VERSION ""

NS_ :

BS_:

BU_: VMCU VGGSECUSystem TECU OBDScanT2 HMIIOM EMS ECUspare2 ECUspare1 DACU CIOM BBM

BO_ 2483002322 HMIIOM_BB2_07P: 8 HMIIOM
 SG_ AudioSourceBtStreamAvailable_ISi : 40|2@1+ (1,0) [0|0] ""  CIOM
 SG_ MainBeam_StalkStatus_4 : 56|3@1+ (1,0) [0|0] ""  VMCU
 SG_ AudioSourceCdAvailable_ISig_4 : 26|2@1+ (1,0) [0|0] ""  CIOM
 SG_ LightMode_SwitchStatus : 48|3@1+ (1,0) [0|0] ""  VMCU
 SG_ PhoneButtonIndication_cmd : 6|2@1+ (1,0) [0|0] ""  CIOM
 SG_ AudioVolumeIndicationCmd_ISig_4 : 8|6@1+ (1,0) [0|63] "Step"  CIOM
 SG_ AudioSourceIpodAvailable_ISig_4 : 36|2@1+ (1,0) [0|0] ""  CIOM
 SG_ AudioSystemStatus_ISig_4 : 4|2@1+ (1,0) [0|0] ""  CIOM
 SG_ WiperAdjustStatus_4 : 59|3@1+ (1,0) [0|0] ""  VMCU
 SG_ AudioSourceUsbAvailable_ISig_4 : 38|2@1+ (1,0) [0|0] ""  CIOM
 SG_ BTStatus : 24|2@1+ (1,0) [0|0] ""  CIOM
 SG_ AudioSourceStatus_ISig_4 : 21|3@1+ (1,0) [0|0] ""  CIOM
 SG_ Washing_Status_4 : 46|2@1+ (1,0) [0|0] ""  VMCU
 SG_ WiperStalkStat_4 : 51|3@1+ (1,0) [0|0] ""  VMCU
 SG_ AudioSourceStatus2_ISig_4 : 42|4@1+ (1,0) [0|0] ""  CIOM
 SG_ BrakeBlending_DeviceIndication : 14|2@1+ (1,0) [0|0] ""  CIOM
 SG_ PresetIndicationCmd_ISig_4 : 28|6@1+ (1,0) [0|63] "Enumeration"  CIOM
 SG_ BunkBacklightCmd_ISig_4 : 16|5@1+ (1,0) [0|0] ""  CIOM
 SG_ ABSInhibit_DeviceIndication : 34|2@1+ (1,0) [0|0] ""  CIOM
 SG_ DayOfWeek_stat_ISig_4 : 0|4@1+ (1,0) [0|0] ""  CIOM

BO_ 2499765033 HMIIOM_BB2_06S_FCM: 8 CIOM
 SG_ HMIIOM_BB2_06S_FCS : 0|64@1+ (1,0) [0|1] ""  HMIIOM

BO_ 2499765032 HMIIOM_BB2_06S: 13 HMIIOM
 SG_ PHTimerGUIEvCmd_Timer2Temp_ISig_ : 16|5@1+ (1,0) [0|0] ""  CIOM
 SG_ PHTimerGUIEvCmd_Timer1Recur_ISig : 24|4@1+ (1,0) [0|0] ""  CIOM
 SG_ PHTimerGUIEvCmd_Timer3Hours_ISig : 88|8@1+ (1,0) [0|255] "h"  CIOM
 SG_ PHTimerGUIEvCmd_Timer3Recur_ISig : 28|4@1+ (1,0) [0|0] ""  CIOM
 SG_ PHTimerGUIEvCmd_PhTimer1_cmd_ISi : 5|3@1+ (1,0) [0|0] ""  CIOM
 SG_ PHTimerGUIEvCmd_Timer2Minutes_IS : 72|8@1+ (1,0) [0|255] "min"  CIOM
 SG_ PHTimerGUIEvCmd_Timer3StartDay_I : 40|4@1+ (1,0) [0|0] ""  CIOM
 SG_ PHTimerGUIEvCmd_Timer2Hours_ISig : 48|8@1+ (1,0) [0|255] "h"  CIOM
 SG_ PHTimerGUIEvCmd_Timer1Duration_I : 96|7@1+ (1,0) [0|127] "min"  CIOM
 SG_ PHTimerGUIEvCmd_Timer2Recur_ISig : 44|4@1+ (1,0) [0|0] ""  CIOM
 SG_ PHTimerGUIEvCmd_Timer2StartDay_I : 36|4@1+ (1,0) [0|0] ""  CIOM
 SG_ PHTimerGUIEvCmd_Timer3Minutes_IS : 64|8@1+ (1,0) [0|255] "min"  CIOM
 SG_ PHTimerGUIEvCmd_Timer3Temp_ISig_ : 0|5@1+ (1,0) [0|0] ""  CIOM
 SG_ PHTimerGUIEvCmd_Timer1Temp_ISig_ : 8|5@1+ (1,0) [0|0] ""  CIOM
 SG_ PHTimerGUIEvCmd_Timer1StartDay_I : 32|4@1+ (1,0) [0|0] ""  CIOM
 SG_ PHTimerGUIEvCmd_PhTimer3_cmd_ISi : 13|3@1+ (1,0) [0|0] ""  CIOM
 SG_ PHTimerGUIEvCmd_PhTimer2_cmd_ISi : 21|3@1+ (1,0) [0|0] ""  CIOM
 SG_ PHTimerGUIEvCmd_Timer1Hours_ISig : 56|8@1+ (1,0) [0|255] "h"  CIOM
 SG_ PHTimerGUIEvCmd_Timer1Minutes_IS : 80|8@1+ (1,0) [0|255] "min"  CIOM

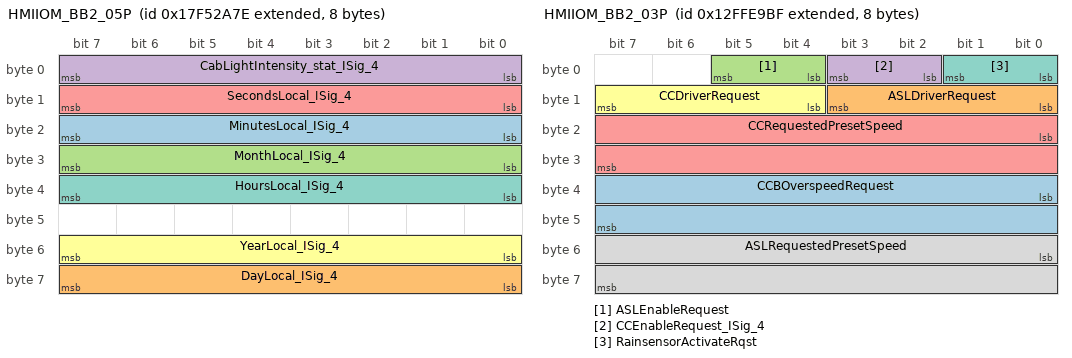
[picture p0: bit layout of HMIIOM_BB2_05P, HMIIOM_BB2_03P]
BO_ 2549426814 HMIIOM_BB2_05P: 8 HMIIOM
 SG_ MinutesLocal_ISig_4 : 16|8@1+ (1,0) [0|255] "min"  CIOM
 SG_ DayLocal_ISig_4 : 56|8@1+ (0.25,0) [0|63.75] "Days"  CIOM
 SG_ MonthLocal_ISig_4 : 24|8@1+ (1,0) [0|255] "Months"  CIOM
 SG_ CabLightIntensity_stat_ISig_4 : 0|8@1+ (0.4,0) [0|102] "Percent"  BBM,DACU
 SG_ SecondsLocal_ISig_4 : 8|8@1+ (0.25,0) [0|63.75] "s"  CIOM
 SG_ YearLocal_ISig_4 : 48|8@1+ (1,1985) [1985|2240] "Years"  CIOM
 SG_ HoursLocal_ISig_4 : 32|8@1+ (1,0) [0|255] "h"  CIOM

BO_ 2499743274 HMIIOM_BB2_04S_FCM: 8 CIOM
 SG_ HMIIOM_BB2_04S_FCS : 0|64@1+ (1,0) [0|1] ""  HMIIOM

BO_ 2499743273 HMIIOM_BB2_04S: 11 HMIIOM
 SG_ EngTimerGUIEvCmd_EhTimer3_cmd_IS : 24|3@1+ (1,0) [0|0] ""  CIOM
 SG_ EngTimerGUIEvCmd_Timer3StartDay_ : 20|4@1+ (1,0) [0|0] ""  CIOM
 SG_ EngTimerGUIEvCmd_Timer2Recur_ISi : 12|4@1+ (1,0) [0|0] ""  CIOM
 SG_ EngTimerGUIEvCmd_Timer3Recur_ISi : 8|4@1+ (1,0) [0|0] ""  CIOM
 SG_ EngTimerGUIEvCmd_Timer1Minutes_I : 72|8@1+ (1,0) [0|255] "min"  CIOM
 SG_ EngTimerGUIEvCmd_Timer3Hours_ISi : 56|8@1+ (1,0) [0|255] "h"  CIOM
 SG_ EngTimerGUIEvCmd_Timer1StartDay_ : 4|4@1+ (1,0) [0|0] ""  CIOM
 SG_ EngTimerGUIEvCmd_Timer3Minutes_I : 64|8@1+ (1,0) [0|255] "min"  CIOM
 SG_ EngTimerGUIEvCmd_Timer2StartDay_ : 16|4@1+ (1,0) [0|0] ""  CIOM
 SG_ EngTimerGUIEvCmd_Timer1Hours_ISi : 48|8@1+ (1,0) [0|255] "h"  CIOM
 SG_ EngTimerGUIEvCmd_EhTimer2_cmd_IS : 27|3@1+ (1,0) [0|0] ""  CIOM
 SG_ EngTimerGUIEvCmd_Timer2Minutes_I : 40|8@1+ (1,0) [0|255] "min"  CIOM
 SG_ EngTimerGUIEvCmd_Timer2Hours_ISi : 80|8@1+ (1,0) [0|255] "h"  CIOM
 SG_ EngTimerGUIEvCmd_Timer1Recur_ISi : 0|4@1+ (1,0) [0|0] ""  CIOM
 SG_ EngTimerGUIEvCmd_EhTimer1_cmd_IS : 32|3@1+ (1,0) [0|0] ""  CIOM

BO_ 2466245055 HMIIOM_BB2_03P: 8 HMIIOM
 SG_ CCBOverspeedRequest : 32|16@1+ (0.00390625,0) [0|255.99609375] "Km_per_h"  VMCU
 SG_ ASLDriverRequest : 8|4@1+ (1,0) [0|0] ""  VMCU
 SG_ ASLEnableRequest : 4|2@1+ (1,0) [0|0] ""  VMCU
 SG_ CCEnableRequest_ISig_4 : 2|2@1+ (1,0) [0|0] ""  CIOM,VMCU,BBM
 SG_ CCRequestedPresetSpeed : 16|16@1+ (0.00390625,0) [0|255.99609375] "Km_per_h"  VMCU
 SG_ CCDriverRequest : 12|4@1+ (1,0) [0|0] ""  VMCU,BBM
 SG_ RainsensorActivateRqst : 0|2@1+ (1,0) [0|0] ""  VMCU
 SG_ ASLRequestedPresetSpeed : 48|16@1+ (0.00390625,0) [0|255.99609375] "Km_per_h"  VMCU

BO_ 2365538239 HMIIOM_BB2_02P: 8 HMIIOM
 SG_ Rainsensor_ButtonStatus : 2|2@1+ (1,0) [0|0] ""  VMCU
 SG_ Traction_DualDeviceIndication : 43|4@1+ (1,0) [0|0] ""  CIOM
 SG_ WiperStalkStat_1 : 24|3@1+ (1,0) [0|0] ""  VMCU
 SG_ RequestForHighestGearRatio : 22|2@1+ (1,0) [0|0] ""  TECU
 SG_ RequestedUpshiftDownshiftSteps : 32|3@1+ (1,0) [0|0] ""  TECU
 SG_ WiperAdjustStatus_1 : 16|3@1+ (1,0) [0|0] ""  VMCU
 SG_ UpShiftRequest : 30|2@1+ (1,0) [0|0] ""  TECU
 SG_ MainBeam_StalkStatus_1 : 27|3@1+ (1,0) [0|0] ""  VMCU
 SG_ DirInd_StalkStatus_1 : 8|3@1+ (1,0) [0|0] ""  VMCU
 SG_ LimpHomeSwitch_stat : 14|2@1+ (1,0) [0|0] ""  TECU
 SG_ GearLeverPosition_UB_ISig_4 : 47|1@1+ (1,0) [0|0] ""  VMCU,BBM,TECU
 SG_ Washing_Status_2 : 4|2@1+ (1,0) [0|0] ""  VMCU
 SG_ EconomyPowerSwitch_stat : 38|2@1+ (1,0) [0|0] ""  TECU
 SG_ GearLeverPosition_ISig_4 : 52|4@1+ (1,0) [0|0] ""  VMCU,TECU,BBM
 SG_ DownShiftRequest : 56|2@1+ (1,0) [0|0] ""  TECU
 SG_ MainBeam_StalkStatus_2 : 35|3@1+ (1,0) [0|0] ""  VMCU
 SG_ DirInd_StalkStatus_2 : 11|3@1+ (1,0) [0|0] ""  VMCU
 SG_ RetarderStalkPosition_1 : 48|4@1+ (1,0) [0|0] ""  VMCU
 SG_ RetarderStalkPosition_2 : 58|4@1+ (1,0) [0|0] ""  VMCU
 SG_ EcoRollEnableRequest_ISig_4 : 6|2@1+ (1,0) [0|0] ""  TECU
 SG_ Washing_Status_1 : 0|2@1+ (1,0) [0|0] ""  VMCU
 SG_ SelectedEcoCruiseLevel_ISig_4 : 40|3@1+ (1,0) [0|0] ""  EMS,DACU,TECU,VMCU
 SG_ WiperStalkStat_2 : 19|3@1+ (1,0) [0|0] ""  VMCU

BO_ 2432634208 HMIIOM_BB2_01P: 8 HMIIOM
 SG_ IdleAdjustDeactivationRequest : 6|2@1+ (1,0) [0|0] ""  VMCU
 SG_ ACMode_Selection_ISig_4 : 11|3@1+ (1,0) [0|0] ""  CIOM
 SG_ TripmeterReset_rqst_ISig_4 : 19|3@1+ (1,0) [0|0] ""  VMCU
 SG_ WaterInFuelDrainRequest : 32|2@1+ (1,0) [0|0] ""  EMS
 SG_ FuncIndIlluminationLevel_ISig_4 : 8|3@1+ (1,0) [0|0] ""  VMCU,CIOM
 SG_ IdleAdjustActivationRequest : 38|2@1+ (1,0) [0|0] ""  VMCU
 SG_ AutoDefogmode_Selection_ISig_4 : 29|3@1+ (1,0) [0|0] ""  CIOM
 SG_ ResumeRequestForACC_ISig_4 : 22|2@1+ (1,0) [0|0] ""  DACU
 SG_ AudioMuteStat_ISig_4 : 57|3@1+ (1,0) [0|0] ""  CIOM
 SG_ IdleAdjustTrimGuiEventCmd : 42|3@1+ (1,0) [0|0] ""  VMCU
 SG_ IdleAdjustStoreRequest : 40|2@1+ (1,0) [0|0] ""  VMCU
 SG_ SWSpeedControlAdjustMode : 52|4@1+ (1,0) [0|0] ""  VMCU,CIOM
 SG_ ACCTimeGapRqst_ISig_4 : 3|3@1+ (1,0) [0|0] ""  DACU
 SG_ AQSMode_Selection_ISig_4 : 14|2@1+ (1,0) [0|0] ""  CIOM
 SG_ ACCEnableRqst_ISig_4 : 34|2@1+ (1,0) [0|0] ""  VMCU,DACU,CIOM
 SG_ StopAlert_cmd_ISig_4 : 45|3@1+ (1,0) [0|0] ""  VMCU
 SG_ BacklightCmd_ISig_4 : 24|5@1+ (1,0) [0|0] ""  CIOM,VMCU
 SG_ AutoBlowerLevel_Selection_ISig_4 : 16|3@1+ (1,0) [0|0] ""  CIOM
 SG_ CMTelltale_stat_ISig_4 : 0|3@1+ (1,0) [0|0] ""  DACU
 SG_ SWSpdCtrlButtonsStatus1 : 48|4@1+ (1,0) [0|0] ""  VMCU,DACU,CIOM

BO_ 2499755792 EMS_BB2_16P: 8 EMS
 SG_ SCR_SulphurLevel_ISig_4 : 0|8@1+ (1,0) [0|255] "Percent"  HMIIOM

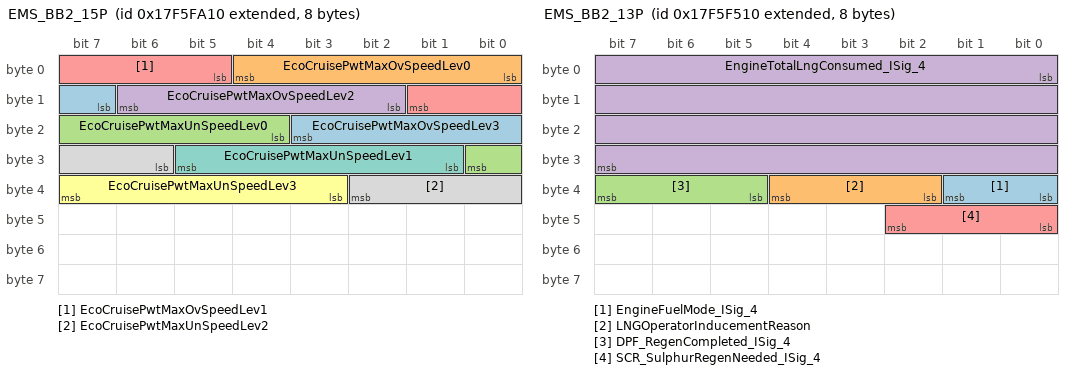
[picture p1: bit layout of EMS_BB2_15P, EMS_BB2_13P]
BO_ 2549479952 EMS_BB2_15P: 8 EMS
 SG_ EcoCruisePwtMaxOvSpeedLev3 : 15|5@1+ (1,0) [0|31] "Km_per_h"  VMCU
 SG_ EcoCruisePwtMaxOvSpeedLev0 : 0|5@1+ (1,0) [0|31] "Km_per_h"  VMCU
 SG_ EcoCruisePwtMaxUnSpeedLev0 : 20|5@1+ (1,0) [0|31] "Km_per_h"  VMCU
 SG_ EcoCruisePwtMaxOvSpeedLev2 : 10|5@1+ (1,0) [0|31] "Km_per_h"  VMCU
 SG_ EcoCruisePwtMaxOvSpeedLev1 : 5|5@1+ (1,0) [0|31] "Km_per_h"  VMCU
 SG_ EcoCruisePwtMaxUnSpeedLev3 : 35|5@1+ (1,0) [0|31] "Km_per_h"  VMCU
 SG_ EcoCruisePwtMaxUnSpeedLev1 : 25|5@1+ (1,0) [0|31] "Km_per_h"  VMCU
 SG_ EcoCruisePwtMaxUnSpeedLev2 : 30|5@1+ (1,0) [0|31] "Km_per_h"  VMCU

BO_ 2549479440 EMS_BB2_14P: 8 EMS
 SG_ TotPTOLNGHighAccuracy : 0|32@1+ (0.01,0) [0|42949672.95] "kg"  VMCU

BO_ 2549478672 EMS_BB2_13P: 8 EMS
 SG_ EngineFuelMode_ISig_4 : 32|2@1+ (1,0) [0|0] ""  HMIIOM,VMCU
 SG_ LNGOperatorInducementReason : 34|3@1+ (1,0) [0|0] ""  HMIIOM
 SG_ DPF_RegenCompleted_ISig_4 : 37|3@1+ (1,0) [0|0] ""  HMIIOM
 SG_ EngineTotalLngConsumed_ISig_4 : 0|32@1+ (0.01,0) [0|42949672.95] "kg"  CIOM,HMIIOM,VMCU
 SG_ SCR_SulphurRegenNeeded_ISig_4 : 40|3@1+ (1,0) [0|0] ""  HMIIOM

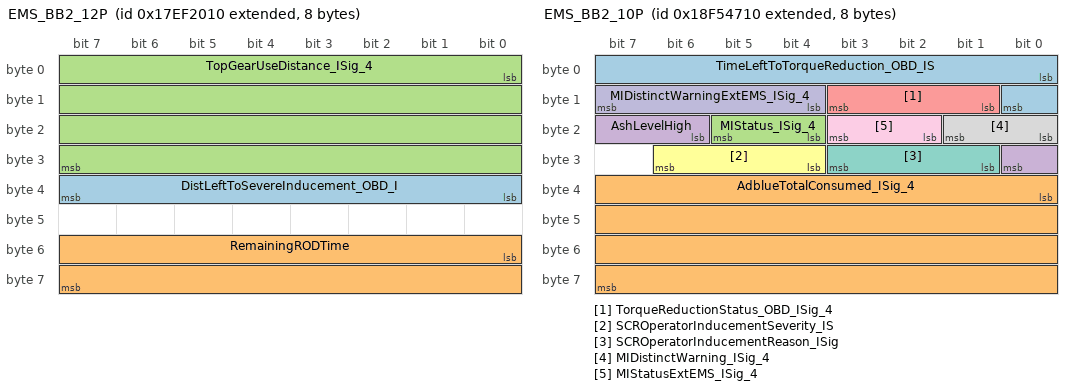
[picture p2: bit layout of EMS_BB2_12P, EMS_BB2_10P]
BO_ 2549030928 EMS_BB2_12P: 8 EMS
 SG_ DistLeftToSevereInducement_OBD_I : 32|8@1+ (5,0) [0|1275] "Km"  HMIIOM
 SG_ RemainingRODTime : 48|16@1+ (1,0) [0|65535] "s"  HMIIOM
 SG_ TopGearUseDistance_ISig_4 : 0|32@1+ (0.01,0) [0|42949672.95] "km"  HMIIOM

BO_ 2499780369 EMS_BB2_11S_FCM: 8 CIOM
 SG_ EMS_BB2_11S_FCS : 0|64@1+ (1,0) [0|0] ""  EMS

BO_ 2499780368 EMS_BB2_11S: 16 EMS
 SG_ KeyID_EngineStartAuth : 0|128@1+ (1,0) [0|0] ""  CIOM

BO_ 2566211344 EMS_BB2_10P: 8 EMS
 SG_ TimeLeftToTorqueReduction_OBD_IS : 0|9@1+ (12,0) [0|6132] "min"  HMIIOM
 SG_ AdblueTotalConsumed_ISig_4 : 32|32@1+ (0.01,0) [0|42949672.95] "l"  VMCU,HMIIOM
 SG_ MIStatus_ISig_4 : 20|2@1+ (1,0) [0|0] ""  VMCU,HMIIOM
 SG_ AshLevelHigh : 22|3@1+ (1,0) [0|0] ""  HMIIOM
 SG_ TorqueReductionStatus_OBD_ISig_4 : 9|3@1+ (1,0) [0|0] ""  HMIIOM
 SG_ SCROperatorInducementSeverity_IS : 28|3@1+ (1,0) [0|0] ""  HMIIOM
 SG_ SCROperatorInducementReason_ISig : 25|3@1+ (1,0) [0|0] ""  HMIIOM
 SG_ MIDistinctWarning_ISig_4 : 16|2@1+ (1,0) [0|0] ""  VMCU,HMIIOM
 SG_ MIStatusExtEMS_ISig_4 : 18|2@1+ (1,0) [0|0] ""  HMIIOM
 SG_ MIDistinctWarningExtEMS_ISig_4 : 12|4@1+ (1,0) [0|0] ""  VMCU,HMIIOM

BO_ 2565955857 EMS_BB2_09S_FCM: 8 CIOM
 SG_ EMS_BB2_09S_FCS : 0|64@1+ (1,0) [0|0] ""  EMS

BO_ 2565955856 EMS_BB2_09S: 11 EMS
 SG_ ECU4VIN_stat : 0|88@1+ (1,0) [0|0] ""  CIOM

BO_ 2566356790 EMS_BB2_08P: 8 EMS
 SG_ EngineRunningTime_ISig_4 : 0|32@1+ (1,0) [0|4294967295] "s"  BBM,HMIIOM,VMCU,CIOM
 SG_ TotPTOFuelHighAccuracy : 32|32@1+ (0.01,0) [0|42949672.95] "l"  VMCU

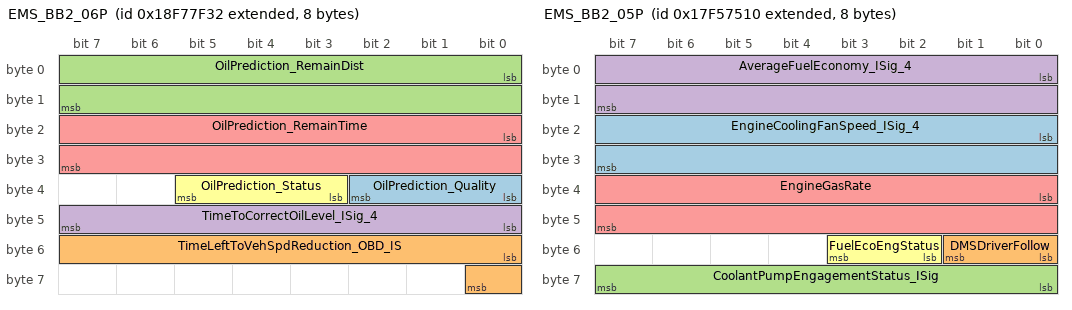
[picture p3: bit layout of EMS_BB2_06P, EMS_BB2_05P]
BO_ 2566356786 EMS_BB2_06P: 8 EMS
 SG_ OilPrediction_Quality : 32|3@1+ (1,0) [0|0] ""  CIOM,VMCU
 SG_ TimeLeftToVehSpdReduction_OBD_IS : 48|9@1+ (15,0) [0|7665] "min"  HMIIOM
 SG_ OilPrediction_RemainDist : 0|16@1+ (10,0) [0|655350] "km"  CIOM,VMCU
 SG_ TimeToCorrectOilLevel_ISig_4 : 40|8@1+ (1,0) [0|255] "min"  HMIIOM,VGGSECUSystem
 SG_ OilPrediction_RemainTime : 16|16@1+ (1,0) [0|65535] "h"  VMCU,CIOM
 SG_ OilPrediction_Status : 35|3@1+ (1,0) [0|0] ""  CIOM,VMCU

BO_ 2549445904 EMS_BB2_05P: 8 EMS
 SG_ EngineCoolingFanSpeed_ISig_4 : 16|16@1+ (1,0) [0|65535] "rpm"  VGGSECUSystem,CIOM
 SG_ DMSDriverFollow : 48|2@1+ (1,0) [0|0] ""  VMCU
 SG_ CoolantPumpEngagementStatus_ISig : 56|8@1+ (0.4,0) [0|102] "Percent"  CIOM
 SG_ AverageFuelEconomy_ISig_4 : 0|16@1+ (0.00390625,0) [0|255.99609375] "miles_per_gallon"  HMIIOM
 SG_ EngineGasRate : 32|16@1+ (0.05,0) [0|3276.75] "Kg_per_h"  VMCU,CIOM,HMIIOM
 SG_ FuelEcoEngStatus : 50|2@1+ (1,0) [0|0] ""  VMCU

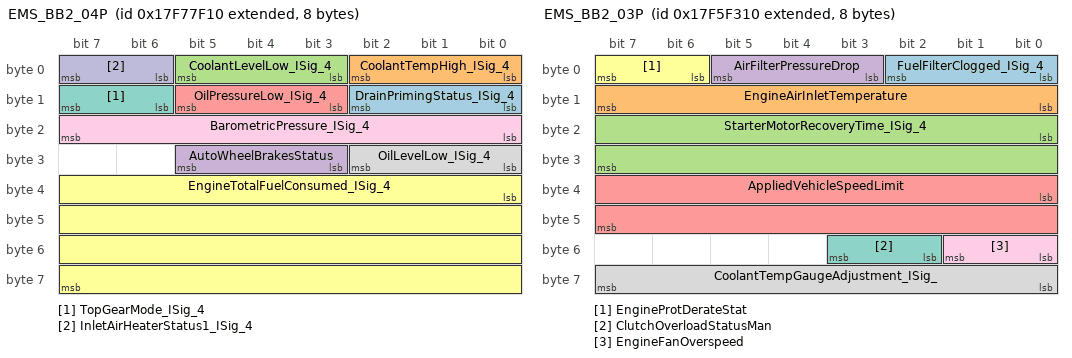
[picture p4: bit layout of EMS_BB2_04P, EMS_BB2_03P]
BO_ 2549579536 EMS_BB2_04P: 8 EMS
 SG_ DrainPrimingStatus_ISig_4 : 8|3@1+ (1,0) [0|0] ""  VGGSECUSystem,HMIIOM
 SG_ CoolantTempHigh_ISig_4 : 0|3@1+ (1,0) [0|0] ""  HMIIOM,VMCU,VGGSECUSystem,BBM
 SG_ CoolantLevelLow_ISig_4 : 3|3@1+ (1,0) [0|0] ""  VMCU,BBM,HMIIOM,VGGSECUSystem
 SG_ AutoWheelBrakesStatus : 27|3@1+ (1,0) [0|0] ""  TECU
 SG_ OilPressureLow_ISig_4 : 11|3@1+ (1,0) [0|0] ""  VMCU,HMIIOM,BBM,VGGSECUSystem
 SG_ EngineTotalFuelConsumed_ISig_4 : 32|32@1+ (0.01,0) [0|42949672.95] "l"  HMIIOM,BBM,CIOM,VMCU,TECU
 SG_ TopGearMode_ISig_4 : 14|2@1+ (1,0) [0|0] ""  HMIIOM
 SG_ OilLevelLow_ISig_4 : 24|3@1+ (1,0) [0|0] ""  VGGSECUSystem,HMIIOM,BBM
 SG_ BarometricPressure_ISig_4 : 16|8@1+ (0.5,0) [0|127.5] "kPa"  TECU,BBM,VMCU
 SG_ InletAirHeaterStatus1_ISig_4 : 6|2@1+ (1,0) [0|0] ""  HMIIOM,VGGSECUSystem

BO_ 2549478160 EMS_BB2_03P: 8 EMS
 SG_ FuelFilterClogged_ISig_4 : 0|3@1+ (1,0) [0|0] ""  VGGSECUSystem,HMIIOM
 SG_ EngineAirInletTemperature : 8|8@1+ (1,-40) [-40|215] "DegreeC"  VMCU
 SG_ StarterMotorRecoveryTime_ISig_4 : 16|16@1+ (1,0) [0|65535] "s"  VGGSECUSystem,HMIIOM
 SG_ AirFilterPressureDrop : 3|3@1+ (1,0) [0|0] ""  HMIIOM,VGGSECUSystem
 SG_ AppliedVehicleSpeedLimit : 32|16@1+ (0.00390625,0) [0|255.99609375] "Km_per_h"  VMCU,TECU,HMIIOM
 SG_ EngineProtDerateStat : 6|2@1+ (1,0) [0|0] ""  VGGSECUSystem,VMCU
 SG_ ClutchOverloadStatusMan : 50|2@1+ (1,0) [0|0] ""  HMIIOM
 SG_ CoolantTempGaugeAdjustment_ISig_ : 56|8@1+ (0.4,0) [0|102] "Percent"  VGGSECUSystem,HMIIOM
 SG_ EngineFanOverspeed : 48|2@1+ (1,0) [0|0] ""  VGGSECUSystem,HMIIOM

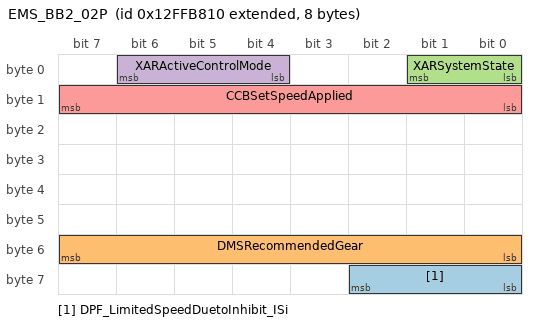
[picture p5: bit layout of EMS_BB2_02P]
BO_ 2466232336 EMS_BB2_02P: 8 EMS
 SG_ DPF_LimitedSpeedDuetoInhibit_ISi : 56|3@1+ (1,0) [0|0] ""  HMIIOM
 SG_ DMSRecommendedGear : 48|8@1+ (1,-125) [-125|130] "GearValue"  HMIIOM
 SG_ XARSystemState : 0|2@1+ (1,0) [0|0] ""  DACU
 SG_ XARActiveControlMode : 4|3@1+ (1,0) [0|0] ""  DACU
 SG_ CCBSetSpeedApplied : 8|8@1+ (1,0) [0|255] "Km_per_h"  VMCU,DACU

CM_ SG_ 2483002322 PresetIndicationCmd_ISig_4 "62 Error ; 63 Not Available";
CM_ SG_ 2499765032 PHTimerGUIEvCmd_Timer3Hours_ISig "254 Error ; 255 Not available";
CM_ SG_ 2499765032 PHTimerGUIEvCmd_Timer2Minutes_IS "254 Error ; 255 Not available";
CM_ SG_ 2499765032 PHTimerGUIEvCmd_Timer2Hours_ISig "254 Error ; 255 Not available";
CM_ SG_ 2499765032 PHTimerGUIEvCmd_Timer1Duration_I "126 Error ; 127 Not available";
CM_ SG_ 2499765032 PHTimerGUIEvCmd_Timer3Minutes_IS "254 Error ; 255 Not available";
CM_ SG_ 2499765032 PHTimerGUIEvCmd_Timer1Hours_ISig "254 Error ; 255 Not available";
CM_ SG_ 2499765032 PHTimerGUIEvCmd_Timer1Minutes_IS "254 Error ; 255 Not available";
CM_ SG_ 2549426814 MinutesLocal_ISig_4 "254 Error ; 255 Not available";
CM_ SG_ 2549426814 DayLocal_ISig_4 "254 Error ; 255 Not available";
CM_ SG_ 2549426814 MonthLocal_ISig_4 "254 Error ; 255 Not available";
CM_ SG_ 2549426814 CabLightIntensity_stat_ISig_4 "254 Error ; 255 Not available";
CM_ SG_ 2549426814 SecondsLocal_ISig_4 "254 Error ; 255 Not available";
CM_ SG_ 2549426814 YearLocal_ISig_4 "254 Error ; 255 Not available";
CM_ SG_ 2549426814 HoursLocal_ISig_4 "254 Error ; 255 Not available";
CM_ SG_ 2499743273 EngTimerGUIEvCmd_Timer1Minutes_I "254 Error ; 255 Not available";
CM_ SG_ 2499743273 EngTimerGUIEvCmd_Timer3Hours_ISi "254 Error ; 255 Not available";
CM_ SG_ 2499743273 EngTimerGUIEvCmd_Timer3Minutes_I "254 Error ; 255 Not available";
CM_ SG_ 2499743273 EngTimerGUIEvCmd_Timer1Hours_ISi "254 Error ; 255 Not available";
CM_ SG_ 2499743273 EngTimerGUIEvCmd_Timer2Minutes_I "254 Error ; 255 Not available";
CM_ SG_ 2499743273 EngTimerGUIEvCmd_Timer2Hours_ISi "254 Error ; 255 Not available";
CM_ SG_ 2466245055 CCBOverspeedRequest "65024 - 65279 Error ; 65280 - 65535 Not available";
CM_ SG_ 2466245055 CCRequestedPresetSpeed "65024 - 65279 Error ; 65280 - 65535 Not available";
CM_ SG_ 2466245055 ASLRequestedPresetSpeed "65024 - 65279 Error ; 65280 - 65535 Not available";
CM_ SG_ 2549478672 EngineTotalLngConsumed_ISig_4 "4211081216 - 4261412863 Spare; 4261412864 - 4278190079 Error; 4278190080 - 4294967295 NotAvailable";
CM_ SG_ 2566211344 TimeLeftToTorqueReduction_OBD_IS "510 Error ; 511 Not available";
CM_ SG_ 2566211344 AdblueTotalConsumed_ISig_4 "4261412864 - 4278190079 Error ; 4278190080 - 4294967295 Not available";
CM_ SG_ 2566356790 EngineRunningTime_ISig_4 "4261412864 - 4278190079 Error ; 4278190080 - 4294967295 Not available";
CM_ SG_ 2566356790 TotPTOFuelHighAccuracy "4261412864 - 4278190079 Error ; 4278190080 - 4294967295 Not available";
CM_ SG_ 2566356786 OilPrediction_RemainDist "65024 - 65279 Error ; 65280 - 65535 Not available";
CM_ SG_ 2566356786 TimeToCorrectOilLevel_ISig_4 "254 Error ; 255 Not Available";
CM_ SG_ 2566356786 OilPrediction_RemainTime "65024 - 65279 Error ; 65280 - 65535 Not available";
CM_ SG_ 2549579536 EngineTotalFuelConsumed_ISig_4 "4261412864 - 4278190079 Error ; 4278190080 - 4294967295 Not available";
CM_ SG_ 2549579536 BarometricPressure_ISig_4 "254 Error ; 255 Not available";
CM_ SG_ 2549478160 EngineAirInletTemperature "254 Error ; 255 Not available";
CM_ SG_ 2549478160 StarterMotorRecoveryTime_ISig_4 "65024 - 65279 Error ; 65280 - 65535 Not available";
CM_ SG_ 2549478160 AppliedVehicleSpeedLimit "65024 - 65279 Error ; 65280 - 65535 Not available";
CM_ BO_ 2466232336 "COM_MATRIX_1.7.0 Removed signals: XARActivePriority bit 2-3, XARAbilityMinAcceleration bit16-31, XARAbilityMaxAcceleration bit 32-47";
CM_ SG_ 2466232336 DMSRecommendedGear "250 No recommendation; 251 Up Arrow to be displayed when recommended upper gear is unknown; 252-253 Spare; 254 Error ; 255 Not available
";
BA_DEF_ BO_  "GenMsgStartDelayTime" INT 0 0;
BA_DEF_ BO_  "GenMsgDelayTime" INT 0 0;
BA_DEF_ BO_  "GenMsgCycleTime" INT 0 0;
BA_DEF_ BO_  "GenMsgSendType" ENUM  "Cyclic","NotUsed","NotUsed","NotUsed","NotUsed","NotUsed","NotUsed","IfActive","NoMsgSendType","NotUsed";
BA_DEF_ SG_  "GenSigStartValue" INT 0 0;
BA_DEF_ SG_  "GenSigCycleTimeActive" INT 0 0;
BA_DEF_ SG_  "GenSigCycleTime" INT 0 0;
BA_DEF_ SG_  "GenSigSendType" ENUM  "Cyclic","OnWrite","OnWriteWithRepetition","OnChange","OnChangeWithRepetition","IfActive","IfActiveWithRepetition","NoSigSendType","NotUsed","NotUsed","NotUsed","NotUsed","NotUsed";
BA_DEF_ BO_  "VFrameFormat" ENUM  "StandardCAN","ExtendedCAN","reserved","J1939PG";
BA_DEF_ SG_  "SigType" ENUM  "Default","Range","RangeSigned","ASCII","Discrete","Control","ReferencePGN","DTC","StringDelimiter","StringLength","StringLengthControl";
BA_DEF_ SG_  "SeToolVersion_SIGNAL" STRING ;
BA_DEF_ SG_  "SeToolUniqueID_SIGNAL" STRING ;
BA_DEF_ SG_  "SeToolOwnerSigGroup_SIGNAL" STRING ;
BA_DEF_ SG_  "SeToolOwnerSigGroupID_SIGNAL" STRING ;
BA_DEF_ SG_  "SeToolName_SIGNAL" STRING ;
BA_DEF_ SG_  "SeToolItemID_SIGNAL" STRING ;
BA_DEF_ SG_  "SeToolAncestorID_SIGNAL" STRING ;
BA_DEF_ SG_  "Platform_VMCU1_Sig" ENUM  "No","Yes";
BA_DEF_ BO_  "NmAsrMessage" ENUM  "No","Yes";
BA_DEF_ SG_  "NeedsUpdateBit" ENUM  "No","Yes";
BA_DEF_ SG_  "MmAnSignal" ENUM  "No","Yes";
BA_DEF_ SG_  "GenSigMaxLatency" INT 0 65535;
BA_DEF_ SG_  "GenSigILSupport" ENUM  "Yes","No";
BA_DEF_ BO_  "GenMsgRequestable" INT 0 1;
BA_DEF_ BO_  "GenMsgILSupport" ENUM  "No","Yes";
BA_DEF_ BO_  "DiagUUDTResponse" ENUM  "No","Yes";
BA_DEF_ BO_  "DiagState" ENUM  "No","Yes";
BA_DEF_ BO_  "DiagResponse" ENUM  "No","Yes";
BA_DEF_ BO_  "DiagRequest" ENUM  "No","Yes";
BA_DEF_ BO_  "DiagConnection" HEX 0 65535;
BA_DEF_ BO_  "CanTpSTmin" INT 0 255;
BA_DEF_ BO_  "CanTpFcFrameId" HEX 0 2147483647;
BA_DEF_ BO_  "CanTpBs" INT 0 255;
BA_DEF_ SG_  "SystemSignalLongSymbol" STRING ;
BA_DEF_REL_ BU_SG_REL_  "GenSigTimeoutTime" INT 0 65535;
BA_DEF_REL_ BU_SG_REL_  "GenSigFirstTimeoutTime" INT 0 65535;
BA_DEF_DEF_  "GenMsgStartDelayTime" 0;
BA_DEF_DEF_  "GenMsgDelayTime" 0;
BA_DEF_DEF_  "GenMsgCycleTime" 0;
BA_DEF_DEF_  "GenMsgSendType" "Cyclic";
BA_DEF_DEF_  "GenSigStartValue" 0;
BA_DEF_DEF_  "GenSigCycleTimeActive" 0;
BA_DEF_DEF_  "GenSigCycleTime" 0;
BA_DEF_DEF_  "GenSigSendType" "Cyclic";
BA_DEF_DEF_  "VFrameFormat" "ExtendedCAN";
BA_DEF_DEF_  "SigType" "Default";
BA_DEF_DEF_  "SeToolVersion_SIGNAL" "";
BA_DEF_DEF_  "SeToolUniqueID_SIGNAL" "";
BA_DEF_DEF_  "SeToolOwnerSigGroup_SIGNAL" "";
BA_DEF_DEF_  "SeToolOwnerSigGroupID_SIGNAL" "";
BA_DEF_DEF_  "SeToolName_SIGNAL" "";
BA_DEF_DEF_  "SeToolItemID_SIGNAL" "";
BA_DEF_DEF_  "SeToolAncestorID_SIGNAL" "";
BA_DEF_DEF_  "Platform_VMCU1_Sig" "No";
BA_DEF_DEF_  "NmAsrMessage" "No";
BA_DEF_DEF_  "NeedsUpdateBit" "No";
BA_DEF_DEF_  "MmAnSignal" "No";
BA_DEF_DEF_  "GenSigMaxLatency" 0;
BA_DEF_DEF_  "GenSigILSupport" "Yes";
BA_DEF_DEF_  "GenMsgRequestable" 1;
BA_DEF_DEF_  "GenMsgILSupport" "Yes";
BA_DEF_DEF_  "DiagUUDTResponse" "No";
BA_DEF_DEF_  "DiagState" "No";
BA_DEF_DEF_  "DiagResponse" "No";
BA_DEF_DEF_  "DiagRequest" "No";
BA_DEF_DEF_  "DiagConnection" 0;
BA_DEF_DEF_  "CanTpSTmin" 0;
BA_DEF_DEF_  "CanTpFcFrameId" 2147483647;
BA_DEF_DEF_  "CanTpBs" 255;
BA_DEF_DEF_REL_ "GenSigTimeoutTime" 0;
BA_DEF_DEF_REL_ "GenSigFirstTimeoutTime" 0;
BA_DEF_DEF_  "SystemSignalLongSymbol" "";
BA_ "GenMsgCycleTime" BO_ 2483002322 60;
BA_ "GenMsgStartDelayTime" BO_ 2483002322 10;
BA_ "GenMsgILSupport" BO_ 2499765033 0;
BA_ "GenMsgSendType" BO_ 2499765033 8;
BA_ "CanTpFcFrameId" BO_ 2499765032 352281385;
BA_ "GenMsgSendType" BO_ 2499765032 8;
BA_ "GenMsgDelayTime" BO_ 2499765032 75;
BA_ "GenMsgCycleTime" BO_ 2549426814 200;
BA_ "GenMsgStartDelayTime" BO_ 2549426814 5;
BA_ "GenMsgILSupport" BO_ 2499743274 0;
BA_ "GenMsgSendType" BO_ 2499743274 8;
BA_ "CanTpFcFrameId" BO_ 2499743273 352259626;
BA_ "GenMsgSendType" BO_ 2499743273 8;
BA_ "GenMsgDelayTime" BO_ 2499743273 75;
BA_ "GenMsgCycleTime" BO_ 2466245055 35;
BA_ "GenMsgStartDelayTime" BO_ 2466245055 20;
BA_ "GenMsgCycleTime" BO_ 2365538239 15;
BA_ "GenMsgCycleTime" BO_ 2432634208 25;
BA_ "GenMsgCycleTime" BO_ 2499755792 40;
BA_ "GenMsgStartDelayTime" BO_ 2499755792 50;
BA_ "GenMsgCycleTime" BO_ 2549479952 1000;
BA_ "GenMsgStartDelayTime" BO_ 2549479952 150;
BA_ "GenMsgCycleTime" BO_ 2549479440 1000;
BA_ "GenMsgCycleTime" BO_ 2549478672 500;
BA_ "GenMsgStartDelayTime" BO_ 2549478672 100;
BA_ "GenMsgCycleTime" BO_ 2549030928 1000;
BA_ "GenMsgStartDelayTime" BO_ 2549030928 75;
BA_ "GenMsgILSupport" BO_ 2499780369 0;
BA_ "GenMsgSendType" BO_ 2499780369 8;
BA_ "CanTpFcFrameId" BO_ 2499780368 352296721;
BA_ "GenMsgSendType" BO_ 2499780368 8;
BA_ "GenMsgDelayTime" BO_ 2499780368 85;
BA_ "GenMsgCycleTime" BO_ 2566211344 1000;
BA_ "GenMsgStartDelayTime" BO_ 2566211344 40;
BA_ "GenMsgILSupport" BO_ 2565955857 0;
BA_ "GenMsgSendType" BO_ 2565955857 8;
BA_ "CanTpFcFrameId" BO_ 2565955856 418472209;
BA_ "GenMsgSendType" BO_ 2565955856 8;
BA_ "GenMsgDelayTime" BO_ 2565955856 110;
BA_ "GenMsgCycleTime" BO_ 2566356790 1200;
BA_ "GenMsgStartDelayTime" BO_ 2566356790 60;
BA_ "GenMsgCycleTime" BO_ 2566356786 1500;
BA_ "GenMsgStartDelayTime" BO_ 2566356786 250;
BA_ "GenMsgCycleTime" BO_ 2549445904 250;
BA_ "GenMsgStartDelayTime" BO_ 2549445904 120;
BA_ "GenMsgCycleTime" BO_ 2549579536 250;
BA_ "GenMsgStartDelayTime" BO_ 2549579536 15;
BA_ "GenMsgCycleTime" BO_ 2549478160 250;
BA_ "GenMsgStartDelayTime" BO_ 2549478160 5;
BA_ "GenMsgCycleTime" BO_ 2466232336 45;
BA_ "GenSigCycleTime" SG_ 2483002322 AudioSourceBtStreamAvailable_ISi 100;
BA_ "GenSigCycleTimeActive" SG_ 2483002322 AudioSourceBtStreamAvailable_ISi 100;
BA_ "GenSigStartValue" SG_ 2483002322 AudioSourceBtStreamAvailable_ISi 3;
BA_ "Platform_VMCU1_Sig" SG_ 2483002322 AudioSourceBtStreamAvailable_ISi 1;
BA_ "SystemSignalLongSymbol" SG_ 2483002322 AudioSourceBtStreamAvailable_ISi "AudioSourceBtStreamAvailable_ISig_4";
BA_ "GenSigCycleTime" SG_ 2483002322 MainBeam_StalkStatus_4 100;
BA_ "GenSigCycleTimeActive" SG_ 2483002322 MainBeam_StalkStatus_4 100;
BA_ "GenSigStartValue" SG_ 2483002322 MainBeam_StalkStatus_4 7;
BA_ "Platform_VMCU1_Sig" SG_ 2483002322 MainBeam_StalkStatus_4 1;
BA_ "GenSigCycleTime" SG_ 2483002322 AudioSourceCdAvailable_ISig_4 100;
BA_ "GenSigCycleTimeActive" SG_ 2483002322 AudioSourceCdAvailable_ISig_4 100;
BA_ "GenSigStartValue" SG_ 2483002322 AudioSourceCdAvailable_ISig_4 3;
BA_ "Platform_VMCU1_Sig" SG_ 2483002322 AudioSourceCdAvailable_ISig_4 1;
BA_ "GenSigCycleTime" SG_ 2483002322 LightMode_SwitchStatus 100;
BA_ "GenSigCycleTimeActive" SG_ 2483002322 LightMode_SwitchStatus 100;
BA_ "GenSigStartValue" SG_ 2483002322 LightMode_SwitchStatus 7;
BA_ "Platform_VMCU1_Sig" SG_ 2483002322 LightMode_SwitchStatus 1;
BA_ "GenSigCycleTime" SG_ 2483002322 PhoneButtonIndication_cmd 100;
BA_ "GenSigCycleTimeActive" SG_ 2483002322 PhoneButtonIndication_cmd 100;
BA_ "GenSigStartValue" SG_ 2483002322 PhoneButtonIndication_cmd 3;
BA_ "GenSigMaxLatency" SG_ 2483002322 PhoneButtonIndication_cmd 71;
BA_ "Platform_VMCU1_Sig" SG_ 2483002322 PhoneButtonIndication_cmd 1;
BA_ "GenSigCycleTime" SG_ 2483002322 AudioVolumeIndicationCmd_ISig_4 100;
BA_ "GenSigCycleTimeActive" SG_ 2483002322 AudioVolumeIndicationCmd_ISig_4 100;
BA_ "GenSigMaxLatency" SG_ 2483002322 AudioVolumeIndicationCmd_ISig_4 71;
BA_ "Platform_VMCU1_Sig" SG_ 2483002322 AudioVolumeIndicationCmd_ISig_4 1;
BA_ "GenSigCycleTime" SG_ 2483002322 AudioSourceIpodAvailable_ISig_4 100;
BA_ "GenSigCycleTimeActive" SG_ 2483002322 AudioSourceIpodAvailable_ISig_4 100;
BA_ "GenSigStartValue" SG_ 2483002322 AudioSourceIpodAvailable_ISig_4 3;
BA_ "Platform_VMCU1_Sig" SG_ 2483002322 AudioSourceIpodAvailable_ISig_4 1;
BA_ "GenSigCycleTime" SG_ 2483002322 AudioSystemStatus_ISig_4 100;
BA_ "GenSigCycleTimeActive" SG_ 2483002322 AudioSystemStatus_ISig_4 100;
BA_ "GenSigStartValue" SG_ 2483002322 AudioSystemStatus_ISig_4 3;
BA_ "GenSigMaxLatency" SG_ 2483002322 AudioSystemStatus_ISig_4 71;
BA_ "Platform_VMCU1_Sig" SG_ 2483002322 AudioSystemStatus_ISig_4 1;
BA_ "GenSigCycleTime" SG_ 2483002322 WiperAdjustStatus_4 100;
BA_ "GenSigCycleTimeActive" SG_ 2483002322 WiperAdjustStatus_4 100;
BA_ "GenSigStartValue" SG_ 2483002322 WiperAdjustStatus_4 7;
BA_ "Platform_VMCU1_Sig" SG_ 2483002322 WiperAdjustStatus_4 1;
BA_ "GenSigCycleTime" SG_ 2483002322 AudioSourceUsbAvailable_ISig_4 100;
BA_ "GenSigCycleTimeActive" SG_ 2483002322 AudioSourceUsbAvailable_ISig_4 100;
BA_ "GenSigStartValue" SG_ 2483002322 AudioSourceUsbAvailable_ISig_4 3;
BA_ "Platform_VMCU1_Sig" SG_ 2483002322 AudioSourceUsbAvailable_ISig_4 1;
BA_ "GenSigCycleTime" SG_ 2483002322 BTStatus 100;
BA_ "GenSigCycleTimeActive" SG_ 2483002322 BTStatus 100;
BA_ "GenSigStartValue" SG_ 2483002322 BTStatus 3;
BA_ "Platform_VMCU1_Sig" SG_ 2483002322 BTStatus 1;
BA_ "GenSigCycleTime" SG_ 2483002322 AudioSourceStatus_ISig_4 100;
BA_ "GenSigCycleTimeActive" SG_ 2483002322 AudioSourceStatus_ISig_4 100;
BA_ "GenSigStartValue" SG_ 2483002322 AudioSourceStatus_ISig_4 7;
BA_ "GenSigMaxLatency" SG_ 2483002322 AudioSourceStatus_ISig_4 71;
BA_ "Platform_VMCU1_Sig" SG_ 2483002322 AudioSourceStatus_ISig_4 1;
BA_ "GenSigCycleTime" SG_ 2483002322 Washing_Status_4 100;
BA_ "GenSigCycleTimeActive" SG_ 2483002322 Washing_Status_4 100;
BA_ "GenSigStartValue" SG_ 2483002322 Washing_Status_4 3;
BA_ "Platform_VMCU1_Sig" SG_ 2483002322 Washing_Status_4 1;
BA_ "GenSigCycleTime" SG_ 2483002322 WiperStalkStat_4 100;
BA_ "GenSigCycleTimeActive" SG_ 2483002322 WiperStalkStat_4 100;
BA_ "GenSigStartValue" SG_ 2483002322 WiperStalkStat_4 7;
BA_ "Platform_VMCU1_Sig" SG_ 2483002322 WiperStalkStat_4 1;
BA_ "GenSigCycleTime" SG_ 2483002322 AudioSourceStatus2_ISig_4 100;
BA_ "GenSigCycleTimeActive" SG_ 2483002322 AudioSourceStatus2_ISig_4 100;
BA_ "GenSigStartValue" SG_ 2483002322 AudioSourceStatus2_ISig_4 15;
BA_ "Platform_VMCU1_Sig" SG_ 2483002322 AudioSourceStatus2_ISig_4 1;
BA_ "GenSigCycleTime" SG_ 2483002322 BrakeBlending_DeviceIndication 100;
BA_ "GenSigCycleTimeActive" SG_ 2483002322 BrakeBlending_DeviceIndication 100;
BA_ "GenSigStartValue" SG_ 2483002322 BrakeBlending_DeviceIndication 3;
BA_ "GenSigMaxLatency" SG_ 2483002322 BrakeBlending_DeviceIndication 71;
BA_ "Platform_VMCU1_Sig" SG_ 2483002322 BrakeBlending_DeviceIndication 1;
BA_ "GenSigCycleTime" SG_ 2483002322 PresetIndicationCmd_ISig_4 100;
BA_ "GenSigCycleTimeActive" SG_ 2483002322 PresetIndicationCmd_ISig_4 100;
BA_ "GenSigStartValue" SG_ 2483002322 PresetIndicationCmd_ISig_4 63;
BA_ "Platform_VMCU1_Sig" SG_ 2483002322 PresetIndicationCmd_ISig_4 1;
BA_ "GenSigCycleTime" SG_ 2483002322 BunkBacklightCmd_ISig_4 100;
BA_ "GenSigCycleTimeActive" SG_ 2483002322 BunkBacklightCmd_ISig_4 100;
BA_ "GenSigMaxLatency" SG_ 2483002322 BunkBacklightCmd_ISig_4 71;
BA_ "Platform_VMCU1_Sig" SG_ 2483002322 BunkBacklightCmd_ISig_4 1;
BA_ "GenSigCycleTime" SG_ 2483002322 ABSInhibit_DeviceIndication 100;
BA_ "GenSigCycleTimeActive" SG_ 2483002322 ABSInhibit_DeviceIndication 100;
BA_ "GenSigStartValue" SG_ 2483002322 ABSInhibit_DeviceIndication 3;
BA_ "Platform_VMCU1_Sig" SG_ 2483002322 ABSInhibit_DeviceIndication 1;
BA_ "GenSigCycleTime" SG_ 2483002322 DayOfWeek_stat_ISig_4 100;
BA_ "GenSigCycleTimeActive" SG_ 2483002322 DayOfWeek_stat_ISig_4 100;
BA_ "GenSigStartValue" SG_ 2483002322 DayOfWeek_stat_ISig_4 15;
BA_ "GenSigMaxLatency" SG_ 2483002322 DayOfWeek_stat_ISig_4 71;
BA_ "Platform_VMCU1_Sig" SG_ 2483002322 DayOfWeek_stat_ISig_4 1;
BA_ "GenSigSendType" SG_ 2499765033 HMIIOM_BB2_06S_FCS 7;
BA_ "Platform_VMCU1_Sig" SG_ 2499765033 HMIIOM_BB2_06S_FCS 1;
BA_ "GenSigSendType" SG_ 2499765032 PHTimerGUIEvCmd_Timer2Temp_ISig_ 1;
BA_ "GenSigCycleTime" SG_ 2499765032 PHTimerGUIEvCmd_Timer2Temp_ISig_ 100;
BA_ "GenSigCycleTimeActive" SG_ 2499765032 PHTimerGUIEvCmd_Timer2Temp_ISig_ 100;
BA_ "GenSigStartValue" SG_ 2499765032 PHTimerGUIEvCmd_Timer2Temp_ISig_ 31;
BA_ "GenSigMaxLatency" SG_ 2499765032 PHTimerGUIEvCmd_Timer2Temp_ISig_ 57;
BA_ "Platform_VMCU1_Sig" SG_ 2499765032 PHTimerGUIEvCmd_Timer2Temp_ISig_ 1;
BA_ "SystemSignalLongSymbol" SG_ 2499765032 PHTimerGUIEvCmd_Timer2Temp_ISig_ "PHTimerGUIEvCmd_Timer2Temp_ISig_4";
BA_ "GenSigSendType" SG_ 2499765032 PHTimerGUIEvCmd_Timer1Recur_ISig 1;
BA_ "GenSigCycleTime" SG_ 2499765032 PHTimerGUIEvCmd_Timer1Recur_ISig 100;
BA_ "GenSigCycleTimeActive" SG_ 2499765032 PHTimerGUIEvCmd_Timer1Recur_ISig 100;
BA_ "GenSigStartValue" SG_ 2499765032 PHTimerGUIEvCmd_Timer1Recur_ISig 15;
BA_ "GenSigMaxLatency" SG_ 2499765032 PHTimerGUIEvCmd_Timer1Recur_ISig 57;
BA_ "Platform_VMCU1_Sig" SG_ 2499765032 PHTimerGUIEvCmd_Timer1Recur_ISig 1;
BA_ "SystemSignalLongSymbol" SG_ 2499765032 PHTimerGUIEvCmd_Timer1Recur_ISig "PHTimerGUIEvCmd_Timer1Recur_ISig_4";
BA_ "GenSigSendType" SG_ 2499765032 PHTimerGUIEvCmd_Timer3Hours_ISig 1;
BA_ "GenSigCycleTime" SG_ 2499765032 PHTimerGUIEvCmd_Timer3Hours_ISig 100;
BA_ "GenSigCycleTimeActive" SG_ 2499765032 PHTimerGUIEvCmd_Timer3Hours_ISig 100;
BA_ "GenSigStartValue" SG_ 2499765032 PHTimerGUIEvCmd_Timer3Hours_ISig 255;
BA_ "GenSigMaxLatency" SG_ 2499765032 PHTimerGUIEvCmd_Timer3Hours_ISig 57;
BA_ "Platform_VMCU1_Sig" SG_ 2499765032 PHTimerGUIEvCmd_Timer3Hours_ISig 1;
BA_ "SystemSignalLongSymbol" SG_ 2499765032 PHTimerGUIEvCmd_Timer3Hours_ISig "PHTimerGUIEvCmd_Timer3Hours_ISig_4";
BA_ "GenSigSendType" SG_ 2499765032 PHTimerGUIEvCmd_Timer3Recur_ISig 1;
BA_ "GenSigCycleTime" SG_ 2499765032 PHTimerGUIEvCmd_Timer3Recur_ISig 100;
BA_ "GenSigCycleTimeActive" SG_ 2499765032 PHTimerGUIEvCmd_Timer3Recur_ISig 100;
BA_ "GenSigStartValue" SG_ 2499765032 PHTimerGUIEvCmd_Timer3Recur_ISig 15;
BA_ "GenSigMaxLatency" SG_ 2499765032 PHTimerGUIEvCmd_Timer3Recur_ISig 57;
BA_ "Platform_VMCU1_Sig" SG_ 2499765032 PHTimerGUIEvCmd_Timer3Recur_ISig 1;
BA_ "SystemSignalLongSymbol" SG_ 2499765032 PHTimerGUIEvCmd_Timer3Recur_ISig "PHTimerGUIEvCmd_Timer3Recur_ISig_4";
BA_ "GenSigSendType" SG_ 2499765032 PHTimerGUIEvCmd_PhTimer1_cmd_ISi 1;
BA_ "GenSigCycleTime" SG_ 2499765032 PHTimerGUIEvCmd_PhTimer1_cmd_ISi 100;
BA_ "GenSigCycleTimeActive" SG_ 2499765032 PHTimerGUIEvCmd_PhTimer1_cmd_ISi 100;
BA_ "GenSigStartValue" SG_ 2499765032 PHTimerGUIEvCmd_PhTimer1_cmd_ISi 7;
BA_ "GenSigMaxLatency" SG_ 2499765032 PHTimerGUIEvCmd_PhTimer1_cmd_ISi 57;
BA_ "Platform_VMCU1_Sig" SG_ 2499765032 PHTimerGUIEvCmd_PhTimer1_cmd_ISi 1;
BA_ "SystemSignalLongSymbol" SG_ 2499765032 PHTimerGUIEvCmd_PhTimer1_cmd_ISi "PHTimerGUIEvCmd_PhTimer1_cmd_ISig_4";
BA_ "GenSigSendType" SG_ 2499765032 PHTimerGUIEvCmd_Timer2Minutes_IS 1;
BA_ "GenSigCycleTime" SG_ 2499765032 PHTimerGUIEvCmd_Timer2Minutes_IS 100;
BA_ "GenSigCycleTimeActive" SG_ 2499765032 PHTimerGUIEvCmd_Timer2Minutes_IS 100;
BA_ "GenSigStartValue" SG_ 2499765032 PHTimerGUIEvCmd_Timer2Minutes_IS 255;
BA_ "GenSigMaxLatency" SG_ 2499765032 PHTimerGUIEvCmd_Timer2Minutes_IS 57;
BA_ "Platform_VMCU1_Sig" SG_ 2499765032 PHTimerGUIEvCmd_Timer2Minutes_IS 1;
BA_ "SystemSignalLongSymbol" SG_ 2499765032 PHTimerGUIEvCmd_Timer2Minutes_IS "PHTimerGUIEvCmd_Timer2Minutes_ISig_4";
BA_ "GenSigSendType" SG_ 2499765032 PHTimerGUIEvCmd_Timer3StartDay_I 1;
BA_ "GenSigCycleTime" SG_ 2499765032 PHTimerGUIEvCmd_Timer3StartDay_I 100;
BA_ "GenSigCycleTimeActive" SG_ 2499765032 PHTimerGUIEvCmd_Timer3StartDay_I 100;
BA_ "GenSigStartValue" SG_ 2499765032 PHTimerGUIEvCmd_Timer3StartDay_I 15;
BA_ "GenSigMaxLatency" SG_ 2499765032 PHTimerGUIEvCmd_Timer3StartDay_I 57;
BA_ "Platform_VMCU1_Sig" SG_ 2499765032 PHTimerGUIEvCmd_Timer3StartDay_I 1;
BA_ "SystemSignalLongSymbol" SG_ 2499765032 PHTimerGUIEvCmd_Timer3StartDay_I "PHTimerGUIEvCmd_Timer3StartDay_ISig_4";
BA_ "GenSigSendType" SG_ 2499765032 PHTimerGUIEvCmd_Timer2Hours_ISig 1;
BA_ "GenSigCycleTime" SG_ 2499765032 PHTimerGUIEvCmd_Timer2Hours_ISig 100;
BA_ "GenSigCycleTimeActive" SG_ 2499765032 PHTimerGUIEvCmd_Timer2Hours_ISig 100;
BA_ "GenSigStartValue" SG_ 2499765032 PHTimerGUIEvCmd_Timer2Hours_ISig 255;
BA_ "GenSigMaxLatency" SG_ 2499765032 PHTimerGUIEvCmd_Timer2Hours_ISig 57;
BA_ "Platform_VMCU1_Sig" SG_ 2499765032 PHTimerGUIEvCmd_Timer2Hours_ISig 1;
BA_ "SystemSignalLongSymbol" SG_ 2499765032 PHTimerGUIEvCmd_Timer2Hours_ISig "PHTimerGUIEvCmd_Timer2Hours_ISig_4";
BA_ "GenSigSendType" SG_ 2499765032 PHTimerGUIEvCmd_Timer1Duration_I 1;
BA_ "GenSigCycleTime" SG_ 2499765032 PHTimerGUIEvCmd_Timer1Duration_I 100;
BA_ "GenSigCycleTimeActive" SG_ 2499765032 PHTimerGUIEvCmd_Timer1Duration_I 100;
BA_ "GenSigStartValue" SG_ 2499765032 PHTimerGUIEvCmd_Timer1Duration_I 127;
BA_ "GenSigMaxLatency" SG_ 2499765032 PHTimerGUIEvCmd_Timer1Duration_I 57;
BA_ "Platform_VMCU1_Sig" SG_ 2499765032 PHTimerGUIEvCmd_Timer1Duration_I 1;
BA_ "SystemSignalLongSymbol" SG_ 2499765032 PHTimerGUIEvCmd_Timer1Duration_I "PHTimerGUIEvCmd_Timer1Duration_ISig_4";
BA_ "GenSigSendType" SG_ 2499765032 PHTimerGUIEvCmd_Timer2Recur_ISig 1;
BA_ "GenSigCycleTime" SG_ 2499765032 PHTimerGUIEvCmd_Timer2Recur_ISig 100;
BA_ "GenSigCycleTimeActive" SG_ 2499765032 PHTimerGUIEvCmd_Timer2Recur_ISig 100;
BA_ "GenSigStartValue" SG_ 2499765032 PHTimerGUIEvCmd_Timer2Recur_ISig 15;
BA_ "GenSigMaxLatency" SG_ 2499765032 PHTimerGUIEvCmd_Timer2Recur_ISig 57;
BA_ "Platform_VMCU1_Sig" SG_ 2499765032 PHTimerGUIEvCmd_Timer2Recur_ISig 1;
BA_ "SystemSignalLongSymbol" SG_ 2499765032 PHTimerGUIEvCmd_Timer2Recur_ISig "PHTimerGUIEvCmd_Timer2Recur_ISig_4";
BA_ "GenSigSendType" SG_ 2499765032 PHTimerGUIEvCmd_Timer2StartDay_I 1;
BA_ "GenSigCycleTime" SG_ 2499765032 PHTimerGUIEvCmd_Timer2StartDay_I 100;
BA_ "GenSigCycleTimeActive" SG_ 2499765032 PHTimerGUIEvCmd_Timer2StartDay_I 100;
BA_ "GenSigStartValue" SG_ 2499765032 PHTimerGUIEvCmd_Timer2StartDay_I 15;
BA_ "GenSigMaxLatency" SG_ 2499765032 PHTimerGUIEvCmd_Timer2StartDay_I 57;
BA_ "Platform_VMCU1_Sig" SG_ 2499765032 PHTimerGUIEvCmd_Timer2StartDay_I 1;
BA_ "SystemSignalLongSymbol" SG_ 2499765032 PHTimerGUIEvCmd_Timer2StartDay_I "PHTimerGUIEvCmd_Timer2StartDay_ISig_4";
BA_ "GenSigSendType" SG_ 2499765032 PHTimerGUIEvCmd_Timer3Minutes_IS 1;
BA_ "GenSigCycleTime" SG_ 2499765032 PHTimerGUIEvCmd_Timer3Minutes_IS 100;
BA_ "GenSigCycleTimeActive" SG_ 2499765032 PHTimerGUIEvCmd_Timer3Minutes_IS 100;
BA_ "GenSigStartValue" SG_ 2499765032 PHTimerGUIEvCmd_Timer3Minutes_IS 255;
BA_ "GenSigMaxLatency" SG_ 2499765032 PHTimerGUIEvCmd_Timer3Minutes_IS 57;
BA_ "Platform_VMCU1_Sig" SG_ 2499765032 PHTimerGUIEvCmd_Timer3Minutes_IS 1;
BA_ "SystemSignalLongSymbol" SG_ 2499765032 PHTimerGUIEvCmd_Timer3Minutes_IS "PHTimerGUIEvCmd_Timer3Minutes_ISig_4";
BA_ "GenSigSendType" SG_ 2499765032 PHTimerGUIEvCmd_Timer3Temp_ISig_ 1;
BA_ "GenSigCycleTime" SG_ 2499765032 PHTimerGUIEvCmd_Timer3Temp_ISig_ 100;
BA_ "GenSigCycleTimeActive" SG_ 2499765032 PHTimerGUIEvCmd_Timer3Temp_ISig_ 100;
BA_ "GenSigStartValue" SG_ 2499765032 PHTimerGUIEvCmd_Timer3Temp_ISig_ 31;
BA_ "GenSigMaxLatency" SG_ 2499765032 PHTimerGUIEvCmd_Timer3Temp_ISig_ 57;
BA_ "Platform_VMCU1_Sig" SG_ 2499765032 PHTimerGUIEvCmd_Timer3Temp_ISig_ 1;
BA_ "SystemSignalLongSymbol" SG_ 2499765032 PHTimerGUIEvCmd_Timer3Temp_ISig_ "PHTimerGUIEvCmd_Timer3Temp_ISig_4";
BA_ "GenSigSendType" SG_ 2499765032 PHTimerGUIEvCmd_Timer1Temp_ISig_ 1;
BA_ "GenSigCycleTime" SG_ 2499765032 PHTimerGUIEvCmd_Timer1Temp_ISig_ 100;
BA_ "GenSigCycleTimeActive" SG_ 2499765032 PHTimerGUIEvCmd_Timer1Temp_ISig_ 100;
BA_ "GenSigStartValue" SG_ 2499765032 PHTimerGUIEvCmd_Timer1Temp_ISig_ 31;
BA_ "GenSigMaxLatency" SG_ 2499765032 PHTimerGUIEvCmd_Timer1Temp_ISig_ 57;
BA_ "Platform_VMCU1_Sig" SG_ 2499765032 PHTimerGUIEvCmd_Timer1Temp_ISig_ 1;
BA_ "SystemSignalLongSymbol" SG_ 2499765032 PHTimerGUIEvCmd_Timer1Temp_ISig_ "PHTimerGUIEvCmd_Timer1Temp_ISig_4";
BA_ "GenSigSendType" SG_ 2499765032 PHTimerGUIEvCmd_Timer1StartDay_I 1;
BA_ "GenSigCycleTime" SG_ 2499765032 PHTimerGUIEvCmd_Timer1StartDay_I 100;
BA_ "GenSigCycleTimeActive" SG_ 2499765032 PHTimerGUIEvCmd_Timer1StartDay_I 100;
BA_ "GenSigStartValue" SG_ 2499765032 PHTimerGUIEvCmd_Timer1StartDay_I 15;
BA_ "GenSigMaxLatency" SG_ 2499765032 PHTimerGUIEvCmd_Timer1StartDay_I 57;
BA_ "Platform_VMCU1_Sig" SG_ 2499765032 PHTimerGUIEvCmd_Timer1StartDay_I 1;
BA_ "SystemSignalLongSymbol" SG_ 2499765032 PHTimerGUIEvCmd_Timer1StartDay_I "PHTimerGUIEvCmd_Timer1StartDay_ISig_4";
BA_ "GenSigSendType" SG_ 2499765032 PHTimerGUIEvCmd_PhTimer3_cmd_ISi 1;
BA_ "GenSigCycleTime" SG_ 2499765032 PHTimerGUIEvCmd_PhTimer3_cmd_ISi 100;
BA_ "GenSigCycleTimeActive" SG_ 2499765032 PHTimerGUIEvCmd_PhTimer3_cmd_ISi 100;
BA_ "GenSigStartValue" SG_ 2499765032 PHTimerGUIEvCmd_PhTimer3_cmd_ISi 7;
BA_ "GenSigMaxLatency" SG_ 2499765032 PHTimerGUIEvCmd_PhTimer3_cmd_ISi 57;
BA_ "Platform_VMCU1_Sig" SG_ 2499765032 PHTimerGUIEvCmd_PhTimer3_cmd_ISi 1;
BA_ "SystemSignalLongSymbol" SG_ 2499765032 PHTimerGUIEvCmd_PhTimer3_cmd_ISi "PHTimerGUIEvCmd_PhTimer3_cmd_ISig_4";
BA_ "GenSigSendType" SG_ 2499765032 PHTimerGUIEvCmd_PhTimer2_cmd_ISi 1;
BA_ "GenSigCycleTime" SG_ 2499765032 PHTimerGUIEvCmd_PhTimer2_cmd_ISi 100;
BA_ "GenSigCycleTimeActive" SG_ 2499765032 PHTimerGUIEvCmd_PhTimer2_cmd_ISi 100;
BA_ "GenSigStartValue" SG_ 2499765032 PHTimerGUIEvCmd_PhTimer2_cmd_ISi 7;
BA_ "GenSigMaxLatency" SG_ 2499765032 PHTimerGUIEvCmd_PhTimer2_cmd_ISi 57;
BA_ "Platform_VMCU1_Sig" SG_ 2499765032 PHTimerGUIEvCmd_PhTimer2_cmd_ISi 1;
BA_ "SystemSignalLongSymbol" SG_ 2499765032 PHTimerGUIEvCmd_PhTimer2_cmd_ISi "PHTimerGUIEvCmd_PhTimer2_cmd_ISig_4";
BA_ "GenSigSendType" SG_ 2499765032 PHTimerGUIEvCmd_Timer1Hours_ISig 1;
BA_ "GenSigCycleTime" SG_ 2499765032 PHTimerGUIEvCmd_Timer1Hours_ISig 100;
BA_ "GenSigCycleTimeActive" SG_ 2499765032 PHTimerGUIEvCmd_Timer1Hours_ISig 100;
BA_ "GenSigStartValue" SG_ 2499765032 PHTimerGUIEvCmd_Timer1Hours_ISig 255;
BA_ "GenSigMaxLatency" SG_ 2499765032 PHTimerGUIEvCmd_Timer1Hours_ISig 57;
BA_ "Platform_VMCU1_Sig" SG_ 2499765032 PHTimerGUIEvCmd_Timer1Hours_ISig 1;
BA_ "SystemSignalLongSymbol" SG_ 2499765032 PHTimerGUIEvCmd_Timer1Hours_ISig "PHTimerGUIEvCmd_Timer1Hours_ISig_4";
BA_ "GenSigSendType" SG_ 2499765032 PHTimerGUIEvCmd_Timer1Minutes_IS 1;
BA_ "GenSigCycleTime" SG_ 2499765032 PHTimerGUIEvCmd_Timer1Minutes_IS 100;
BA_ "GenSigCycleTimeActive" SG_ 2499765032 PHTimerGUIEvCmd_Timer1Minutes_IS 100;
BA_ "GenSigStartValue" SG_ 2499765032 PHTimerGUIEvCmd_Timer1Minutes_IS 255;
BA_ "GenSigMaxLatency" SG_ 2499765032 PHTimerGUIEvCmd_Timer1Minutes_IS 57;
BA_ "Platform_VMCU1_Sig" SG_ 2499765032 PHTimerGUIEvCmd_Timer1Minutes_IS 1;
BA_ "SystemSignalLongSymbol" SG_ 2499765032 PHTimerGUIEvCmd_Timer1Minutes_IS "PHTimerGUIEvCmd_Timer1Minutes_ISig_4";
BA_ "GenSigCycleTime" SG_ 2549426814 MinutesLocal_ISig_4 100;
BA_ "GenSigCycleTimeActive" SG_ 2549426814 MinutesLocal_ISig_4 100;
BA_ "GenSigStartValue" SG_ 2549426814 MinutesLocal_ISig_4 255;
BA_ "GenSigMaxLatency" SG_ 2549426814 MinutesLocal_ISig_4 121;
BA_ "Platform_VMCU1_Sig" SG_ 2549426814 MinutesLocal_ISig_4 1;
BA_ "GenSigCycleTime" SG_ 2549426814 DayLocal_ISig_4 100;
BA_ "GenSigCycleTimeActive" SG_ 2549426814 DayLocal_ISig_4 100;
BA_ "GenSigStartValue" SG_ 2549426814 DayLocal_ISig_4 255;
BA_ "GenSigMaxLatency" SG_ 2549426814 DayLocal_ISig_4 121;
BA_ "Platform_VMCU1_Sig" SG_ 2549426814 DayLocal_ISig_4 1;
BA_ "GenSigCycleTime" SG_ 2549426814 MonthLocal_ISig_4 100;
BA_ "GenSigCycleTimeActive" SG_ 2549426814 MonthLocal_ISig_4 100;
BA_ "GenSigStartValue" SG_ 2549426814 MonthLocal_ISig_4 255;
BA_ "GenSigMaxLatency" SG_ 2549426814 MonthLocal_ISig_4 121;
BA_ "Platform_VMCU1_Sig" SG_ 2549426814 MonthLocal_ISig_4 1;
BA_ "GenSigCycleTime" SG_ 2549426814 CabLightIntensity_stat_ISig_4 100;
BA_ "GenSigCycleTimeActive" SG_ 2549426814 CabLightIntensity_stat_ISig_4 100;
BA_ "GenSigStartValue" SG_ 2549426814 CabLightIntensity_stat_ISig_4 255;
BA_ "GenSigMaxLatency" SG_ 2549426814 CabLightIntensity_stat_ISig_4 56;
BA_ "Platform_VMCU1_Sig" SG_ 2549426814 CabLightIntensity_stat_ISig_4 1;
BA_ "SeToolAncestorID_SIGNAL" SG_ 2549426814 CabLightIntensity_stat_ISig_4 "x0000001D041AFE81";
BA_ "SeToolItemID_SIGNAL" SG_ 2549426814 CabLightIntensity_stat_ISig_4 "x0000001D0433F018";
BA_ "SeToolName_SIGNAL" SG_ 2549426814 CabLightIntensity_stat_ISig_4 "LightSensor_Data";
BA_ "SeToolVersion_SIGNAL" SG_ 2549426814 CabLightIntensity_stat_ISig_4 "2";
BA_ "GenSigCycleTime" SG_ 2549426814 SecondsLocal_ISig_4 100;
BA_ "GenSigCycleTimeActive" SG_ 2549426814 SecondsLocal_ISig_4 100;
BA_ "GenSigStartValue" SG_ 2549426814 SecondsLocal_ISig_4 255;
BA_ "GenSigMaxLatency" SG_ 2549426814 SecondsLocal_ISig_4 121;
BA_ "Platform_VMCU1_Sig" SG_ 2549426814 SecondsLocal_ISig_4 1;
BA_ "GenSigCycleTime" SG_ 2549426814 YearLocal_ISig_4 100;
BA_ "GenSigCycleTimeActive" SG_ 2549426814 YearLocal_ISig_4 100;
BA_ "GenSigStartValue" SG_ 2549426814 YearLocal_ISig_4 255;
BA_ "GenSigMaxLatency" SG_ 2549426814 YearLocal_ISig_4 121;
BA_ "Platform_VMCU1_Sig" SG_ 2549426814 YearLocal_ISig_4 1;
BA_ "GenSigCycleTime" SG_ 2549426814 HoursLocal_ISig_4 100;
BA_ "GenSigCycleTimeActive" SG_ 2549426814 HoursLocal_ISig_4 100;
BA_ "GenSigStartValue" SG_ 2549426814 HoursLocal_ISig_4 255;
BA_ "GenSigMaxLatency" SG_ 2549426814 HoursLocal_ISig_4 121;
BA_ "Platform_VMCU1_Sig" SG_ 2549426814 HoursLocal_ISig_4 1;
BA_ "GenSigSendType" SG_ 2499743274 HMIIOM_BB2_04S_FCS 7;
BA_ "Platform_VMCU1_Sig" SG_ 2499743274 HMIIOM_BB2_04S_FCS 1;
BA_ "GenSigSendType" SG_ 2499743273 EngTimerGUIEvCmd_EhTimer3_cmd_IS 1;
BA_ "GenSigCycleTime" SG_ 2499743273 EngTimerGUIEvCmd_EhTimer3_cmd_IS 100;
BA_ "GenSigCycleTimeActive" SG_ 2499743273 EngTimerGUIEvCmd_EhTimer3_cmd_IS 100;
BA_ "GenSigStartValue" SG_ 2499743273 EngTimerGUIEvCmd_EhTimer3_cmd_IS 7;
BA_ "GenSigMaxLatency" SG_ 2499743273 EngTimerGUIEvCmd_EhTimer3_cmd_IS 55;
BA_ "Platform_VMCU1_Sig" SG_ 2499743273 EngTimerGUIEvCmd_EhTimer3_cmd_IS 1;
BA_ "SystemSignalLongSymbol" SG_ 2499743273 EngTimerGUIEvCmd_EhTimer3_cmd_IS "EngTimerGUIEvCmd_EhTimer3_cmd_ISig_4";
BA_ "GenSigSendType" SG_ 2499743273 EngTimerGUIEvCmd_Timer3StartDay_ 1;
BA_ "GenSigCycleTime" SG_ 2499743273 EngTimerGUIEvCmd_Timer3StartDay_ 100;
BA_ "GenSigCycleTimeActive" SG_ 2499743273 EngTimerGUIEvCmd_Timer3StartDay_ 100;
BA_ "GenSigStartValue" SG_ 2499743273 EngTimerGUIEvCmd_Timer3StartDay_ 15;
BA_ "GenSigMaxLatency" SG_ 2499743273 EngTimerGUIEvCmd_Timer3StartDay_ 55;
BA_ "Platform_VMCU1_Sig" SG_ 2499743273 EngTimerGUIEvCmd_Timer3StartDay_ 1;
BA_ "SystemSignalLongSymbol" SG_ 2499743273 EngTimerGUIEvCmd_Timer3StartDay_ "EngTimerGUIEvCmd_Timer3StartDay_ISig_4";
BA_ "GenSigSendType" SG_ 2499743273 EngTimerGUIEvCmd_Timer2Recur_ISi 1;
BA_ "GenSigCycleTime" SG_ 2499743273 EngTimerGUIEvCmd_Timer2Recur_ISi 100;
BA_ "GenSigCycleTimeActive" SG_ 2499743273 EngTimerGUIEvCmd_Timer2Recur_ISi 100;
BA_ "GenSigStartValue" SG_ 2499743273 EngTimerGUIEvCmd_Timer2Recur_ISi 15;
BA_ "GenSigMaxLatency" SG_ 2499743273 EngTimerGUIEvCmd_Timer2Recur_ISi 55;
BA_ "Platform_VMCU1_Sig" SG_ 2499743273 EngTimerGUIEvCmd_Timer2Recur_ISi 1;
BA_ "SystemSignalLongSymbol" SG_ 2499743273 EngTimerGUIEvCmd_Timer2Recur_ISi "EngTimerGUIEvCmd_Timer2Recur_ISig_4";
BA_ "GenSigSendType" SG_ 2499743273 EngTimerGUIEvCmd_Timer3Recur_ISi 1;
BA_ "GenSigCycleTime" SG_ 2499743273 EngTimerGUIEvCmd_Timer3Recur_ISi 100;
BA_ "GenSigCycleTimeActive" SG_ 2499743273 EngTimerGUIEvCmd_Timer3Recur_ISi 100;
BA_ "GenSigStartValue" SG_ 2499743273 EngTimerGUIEvCmd_Timer3Recur_ISi 15;
BA_ "GenSigMaxLatency" SG_ 2499743273 EngTimerGUIEvCmd_Timer3Recur_ISi 55;
BA_ "Platform_VMCU1_Sig" SG_ 2499743273 EngTimerGUIEvCmd_Timer3Recur_ISi 1;
BA_ "SystemSignalLongSymbol" SG_ 2499743273 EngTimerGUIEvCmd_Timer3Recur_ISi "EngTimerGUIEvCmd_Timer3Recur_ISig_4";
BA_ "GenSigSendType" SG_ 2499743273 EngTimerGUIEvCmd_Timer1Minutes_I 1;
BA_ "GenSigCycleTime" SG_ 2499743273 EngTimerGUIEvCmd_Timer1Minutes_I 100;
BA_ "GenSigCycleTimeActive" SG_ 2499743273 EngTimerGUIEvCmd_Timer1Minutes_I 100;
BA_ "GenSigStartValue" SG_ 2499743273 EngTimerGUIEvCmd_Timer1Minutes_I 255;
BA_ "GenSigMaxLatency" SG_ 2499743273 EngTimerGUIEvCmd_Timer1Minutes_I 55;
BA_ "Platform_VMCU1_Sig" SG_ 2499743273 EngTimerGUIEvCmd_Timer1Minutes_I 1;
BA_ "SystemSignalLongSymbol" SG_ 2499743273 EngTimerGUIEvCmd_Timer1Minutes_I "EngTimerGUIEvCmd_Timer1Minutes_ISig_4";
BA_ "GenSigSendType" SG_ 2499743273 EngTimerGUIEvCmd_Timer3Hours_ISi 1;
BA_ "GenSigCycleTime" SG_ 2499743273 EngTimerGUIEvCmd_Timer3Hours_ISi 100;
BA_ "GenSigCycleTimeActive" SG_ 2499743273 EngTimerGUIEvCmd_Timer3Hours_ISi 100;
BA_ "GenSigStartValue" SG_ 2499743273 EngTimerGUIEvCmd_Timer3Hours_ISi 255;
BA_ "GenSigMaxLatency" SG_ 2499743273 EngTimerGUIEvCmd_Timer3Hours_ISi 55;
BA_ "Platform_VMCU1_Sig" SG_ 2499743273 EngTimerGUIEvCmd_Timer3Hours_ISi 1;
BA_ "SystemSignalLongSymbol" SG_ 2499743273 EngTimerGUIEvCmd_Timer3Hours_ISi "EngTimerGUIEvCmd_Timer3Hours_ISig_4";
BA_ "GenSigSendType" SG_ 2499743273 EngTimerGUIEvCmd_Timer1StartDay_ 1;
BA_ "GenSigCycleTime" SG_ 2499743273 EngTimerGUIEvCmd_Timer1StartDay_ 100;
BA_ "GenSigCycleTimeActive" SG_ 2499743273 EngTimerGUIEvCmd_Timer1StartDay_ 100;
BA_ "GenSigStartValue" SG_ 2499743273 EngTimerGUIEvCmd_Timer1StartDay_ 15;
BA_ "GenSigMaxLatency" SG_ 2499743273 EngTimerGUIEvCmd_Timer1StartDay_ 55;
BA_ "Platform_VMCU1_Sig" SG_ 2499743273 EngTimerGUIEvCmd_Timer1StartDay_ 1;
BA_ "SystemSignalLongSymbol" SG_ 2499743273 EngTimerGUIEvCmd_Timer1StartDay_ "EngTimerGUIEvCmd_Timer1StartDay_ISig_4";
BA_ "GenSigSendType" SG_ 2499743273 EngTimerGUIEvCmd_Timer3Minutes_I 1;
BA_ "GenSigCycleTime" SG_ 2499743273 EngTimerGUIEvCmd_Timer3Minutes_I 100;
BA_ "GenSigCycleTimeActive" SG_ 2499743273 EngTimerGUIEvCmd_Timer3Minutes_I 100;
BA_ "GenSigStartValue" SG_ 2499743273 EngTimerGUIEvCmd_Timer3Minutes_I 255;
BA_ "GenSigMaxLatency" SG_ 2499743273 EngTimerGUIEvCmd_Timer3Minutes_I 55;
BA_ "Platform_VMCU1_Sig" SG_ 2499743273 EngTimerGUIEvCmd_Timer3Minutes_I 1;
BA_ "SystemSignalLongSymbol" SG_ 2499743273 EngTimerGUIEvCmd_Timer3Minutes_I "EngTimerGUIEvCmd_Timer3Minutes_ISig_4";
BA_ "GenSigSendType" SG_ 2499743273 EngTimerGUIEvCmd_Timer2StartDay_ 1;
BA_ "GenSigCycleTime" SG_ 2499743273 EngTimerGUIEvCmd_Timer2StartDay_ 100;
BA_ "GenSigCycleTimeActive" SG_ 2499743273 EngTimerGUIEvCmd_Timer2StartDay_ 100;
BA_ "GenSigStartValue" SG_ 2499743273 EngTimerGUIEvCmd_Timer2StartDay_ 15;
BA_ "GenSigMaxLatency" SG_ 2499743273 EngTimerGUIEvCmd_Timer2StartDay_ 55;
BA_ "Platform_VMCU1_Sig" SG_ 2499743273 EngTimerGUIEvCmd_Timer2StartDay_ 1;
BA_ "SystemSignalLongSymbol" SG_ 2499743273 EngTimerGUIEvCmd_Timer2StartDay_ "EngTimerGUIEvCmd_Timer2StartDay_ISig_4";
BA_ "GenSigSendType" SG_ 2499743273 EngTimerGUIEvCmd_Timer1Hours_ISi 1;
BA_ "GenSigCycleTime" SG_ 2499743273 EngTimerGUIEvCmd_Timer1Hours_ISi 100;
BA_ "GenSigCycleTimeActive" SG_ 2499743273 EngTimerGUIEvCmd_Timer1Hours_ISi 100;
BA_ "GenSigStartValue" SG_ 2499743273 EngTimerGUIEvCmd_Timer1Hours_ISi 255;
BA_ "GenSigMaxLatency" SG_ 2499743273 EngTimerGUIEvCmd_Timer1Hours_ISi 55;
BA_ "Platform_VMCU1_Sig" SG_ 2499743273 EngTimerGUIEvCmd_Timer1Hours_ISi 1;
BA_ "SystemSignalLongSymbol" SG_ 2499743273 EngTimerGUIEvCmd_Timer1Hours_ISi "EngTimerGUIEvCmd_Timer1Hours_ISig_4";
BA_ "GenSigSendType" SG_ 2499743273 EngTimerGUIEvCmd_EhTimer2_cmd_IS 1;
BA_ "GenSigCycleTime" SG_ 2499743273 EngTimerGUIEvCmd_EhTimer2_cmd_IS 100;
BA_ "GenSigCycleTimeActive" SG_ 2499743273 EngTimerGUIEvCmd_EhTimer2_cmd_IS 100;
BA_ "GenSigStartValue" SG_ 2499743273 EngTimerGUIEvCmd_EhTimer2_cmd_IS 7;
BA_ "GenSigMaxLatency" SG_ 2499743273 EngTimerGUIEvCmd_EhTimer2_cmd_IS 55;
BA_ "Platform_VMCU1_Sig" SG_ 2499743273 EngTimerGUIEvCmd_EhTimer2_cmd_IS 1;
BA_ "SystemSignalLongSymbol" SG_ 2499743273 EngTimerGUIEvCmd_EhTimer2_cmd_IS "EngTimerGUIEvCmd_EhTimer2_cmd_ISig_4";
BA_ "GenSigSendType" SG_ 2499743273 EngTimerGUIEvCmd_Timer2Minutes_I 1;
BA_ "GenSigCycleTime" SG_ 2499743273 EngTimerGUIEvCmd_Timer2Minutes_I 100;
BA_ "GenSigCycleTimeActive" SG_ 2499743273 EngTimerGUIEvCmd_Timer2Minutes_I 100;
BA_ "GenSigStartValue" SG_ 2499743273 EngTimerGUIEvCmd_Timer2Minutes_I 255;
BA_ "GenSigMaxLatency" SG_ 2499743273 EngTimerGUIEvCmd_Timer2Minutes_I 55;
BA_ "Platform_VMCU1_Sig" SG_ 2499743273 EngTimerGUIEvCmd_Timer2Minutes_I 1;
BA_ "SystemSignalLongSymbol" SG_ 2499743273 EngTimerGUIEvCmd_Timer2Minutes_I "EngTimerGUIEvCmd_Timer2Minutes_ISig_4";
BA_ "GenSigSendType" SG_ 2499743273 EngTimerGUIEvCmd_Timer2Hours_ISi 1;
BA_ "GenSigCycleTime" SG_ 2499743273 EngTimerGUIEvCmd_Timer2Hours_ISi 100;
BA_ "GenSigCycleTimeActive" SG_ 2499743273 EngTimerGUIEvCmd_Timer2Hours_ISi 100;
BA_ "GenSigStartValue" SG_ 2499743273 EngTimerGUIEvCmd_Timer2Hours_ISi 255;
BA_ "GenSigMaxLatency" SG_ 2499743273 EngTimerGUIEvCmd_Timer2Hours_ISi 55;
BA_ "Platform_VMCU1_Sig" SG_ 2499743273 EngTimerGUIEvCmd_Timer2Hours_ISi 1;
BA_ "SystemSignalLongSymbol" SG_ 2499743273 EngTimerGUIEvCmd_Timer2Hours_ISi "EngTimerGUIEvCmd_Timer2Hours_ISig_4";
BA_ "GenSigSendType" SG_ 2499743273 EngTimerGUIEvCmd_Timer1Recur_ISi 1;
BA_ "GenSigCycleTime" SG_ 2499743273 EngTimerGUIEvCmd_Timer1Recur_ISi 100;
BA_ "GenSigCycleTimeActive" SG_ 2499743273 EngTimerGUIEvCmd_Timer1Recur_ISi 100;
BA_ "GenSigStartValue" SG_ 2499743273 EngTimerGUIEvCmd_Timer1Recur_ISi 15;
BA_ "GenSigMaxLatency" SG_ 2499743273 EngTimerGUIEvCmd_Timer1Recur_ISi 55;
BA_ "Platform_VMCU1_Sig" SG_ 2499743273 EngTimerGUIEvCmd_Timer1Recur_ISi 1;
BA_ "SystemSignalLongSymbol" SG_ 2499743273 EngTimerGUIEvCmd_Timer1Recur_ISi "EngTimerGUIEvCmd_Timer1Recur_ISig_4";
BA_ "GenSigSendType" SG_ 2499743273 EngTimerGUIEvCmd_EhTimer1_cmd_IS 1;
BA_ "GenSigCycleTime" SG_ 2499743273 EngTimerGUIEvCmd_EhTimer1_cmd_IS 100;
BA_ "GenSigCycleTimeActive" SG_ 2499743273 EngTimerGUIEvCmd_EhTimer1_cmd_IS 100;
BA_ "GenSigStartValue" SG_ 2499743273 EngTimerGUIEvCmd_EhTimer1_cmd_IS 7;
BA_ "GenSigMaxLatency" SG_ 2499743273 EngTimerGUIEvCmd_EhTimer1_cmd_IS 55;
BA_ "Platform_VMCU1_Sig" SG_ 2499743273 EngTimerGUIEvCmd_EhTimer1_cmd_IS 1;
BA_ "SystemSignalLongSymbol" SG_ 2499743273 EngTimerGUIEvCmd_EhTimer1_cmd_IS "EngTimerGUIEvCmd_EhTimer1_cmd_ISig_4";
BA_ "GenSigCycleTime" SG_ 2466245055 CCBOverspeedRequest 100;
BA_ "GenSigCycleTimeActive" SG_ 2466245055 CCBOverspeedRequest 100;
BA_ "GenSigStartValue" SG_ 2466245055 CCBOverspeedRequest 65535;
BA_ "GenSigMaxLatency" SG_ 2466245055 CCBOverspeedRequest 41;
BA_ "Platform_VMCU1_Sig" SG_ 2466245055 CCBOverspeedRequest 1;
BA_ "GenSigCycleTime" SG_ 2466245055 ASLDriverRequest 100;
BA_ "GenSigCycleTimeActive" SG_ 2466245055 ASLDriverRequest 100;
BA_ "GenSigStartValue" SG_ 2466245055 ASLDriverRequest 15;
BA_ "GenSigMaxLatency" SG_ 2466245055 ASLDriverRequest 41;
BA_ "Platform_VMCU1_Sig" SG_ 2466245055 ASLDriverRequest 1;
BA_ "GenSigCycleTime" SG_ 2466245055 ASLEnableRequest 100;
BA_ "GenSigCycleTimeActive" SG_ 2466245055 ASLEnableRequest 100;
BA_ "GenSigStartValue" SG_ 2466245055 ASLEnableRequest 3;
BA_ "GenSigMaxLatency" SG_ 2466245055 ASLEnableRequest 41;
BA_ "Platform_VMCU1_Sig" SG_ 2466245055 ASLEnableRequest 1;
BA_ "GenSigCycleTime" SG_ 2466245055 CCEnableRequest_ISig_4 100;
BA_ "GenSigCycleTimeActive" SG_ 2466245055 CCEnableRequest_ISig_4 100;
BA_ "GenSigStartValue" SG_ 2466245055 CCEnableRequest_ISig_4 3;
BA_ "GenSigMaxLatency" SG_ 2466245055 CCEnableRequest_ISig_4 41;
BA_ "Platform_VMCU1_Sig" SG_ 2466245055 CCEnableRequest_ISig_4 1;
BA_ "GenSigCycleTime" SG_ 2466245055 CCRequestedPresetSpeed 100;
BA_ "GenSigCycleTimeActive" SG_ 2466245055 CCRequestedPresetSpeed 100;
BA_ "GenSigStartValue" SG_ 2466245055 CCRequestedPresetSpeed 65535;
BA_ "GenSigMaxLatency" SG_ 2466245055 CCRequestedPresetSpeed 41;
BA_ "Platform_VMCU1_Sig" SG_ 2466245055 CCRequestedPresetSpeed 1;
BA_ "GenSigCycleTime" SG_ 2466245055 CCDriverRequest 100;
BA_ "GenSigCycleTimeActive" SG_ 2466245055 CCDriverRequest 100;
BA_ "GenSigStartValue" SG_ 2466245055 CCDriverRequest 15;
BA_ "GenSigMaxLatency" SG_ 2466245055 CCDriverRequest 41;
BA_ "Platform_VMCU1_Sig" SG_ 2466245055 CCDriverRequest 1;
BA_ "GenSigCycleTime" SG_ 2466245055 RainsensorActivateRqst 100;
BA_ "GenSigCycleTimeActive" SG_ 2466245055 RainsensorActivateRqst 100;
BA_ "GenSigStartValue" SG_ 2466245055 RainsensorActivateRqst 3;
BA_ "GenSigMaxLatency" SG_ 2466245055 RainsensorActivateRqst 41;
BA_ "Platform_VMCU1_Sig" SG_ 2466245055 RainsensorActivateRqst 1;
BA_ "GenSigCycleTime" SG_ 2466245055 ASLRequestedPresetSpeed 100;
BA_ "GenSigCycleTimeActive" SG_ 2466245055 ASLRequestedPresetSpeed 100;
BA_ "GenSigStartValue" SG_ 2466245055 ASLRequestedPresetSpeed 65535;
BA_ "GenSigMaxLatency" SG_ 2466245055 ASLRequestedPresetSpeed 41;
BA_ "Platform_VMCU1_Sig" SG_ 2466245055 ASLRequestedPresetSpeed 1;
BA_ "GenSigCycleTime" SG_ 2365538239 Rainsensor_ButtonStatus 100;
BA_ "GenSigCycleTimeActive" SG_ 2365538239 Rainsensor_ButtonStatus 100;
BA_ "GenSigStartValue" SG_ 2365538239 Rainsensor_ButtonStatus 3;
BA_ "GenSigMaxLatency" SG_ 2365538239 Rainsensor_ButtonStatus 27;
BA_ "Platform_VMCU1_Sig" SG_ 2365538239 Rainsensor_ButtonStatus 1;
BA_ "SeToolAncestorID_SIGNAL" SG_ 2365538239 Rainsensor_ButtonStatus "x0000001D0423D932";
BA_ "SeToolItemID_SIGNAL" SG_ 2365538239 Rainsensor_ButtonStatus "x0000001D0429669B";
BA_ "SeToolName_SIGNAL" SG_ 2365538239 Rainsensor_ButtonStatus "Rainsensor_ButtonStatus";
BA_ "SeToolVersion_SIGNAL" SG_ 2365538239 Rainsensor_ButtonStatus "4";
BA_ "GenSigCycleTime" SG_ 2365538239 Traction_DualDeviceIndication 100;
BA_ "GenSigCycleTimeActive" SG_ 2365538239 Traction_DualDeviceIndication 100;
BA_ "GenSigStartValue" SG_ 2365538239 Traction_DualDeviceIndication 15;
BA_ "Platform_VMCU1_Sig" SG_ 2365538239 Traction_DualDeviceIndication 1;
BA_ "GenSigCycleTime" SG_ 2365538239 WiperStalkStat_1 100;
BA_ "GenSigCycleTimeActive" SG_ 2365538239 WiperStalkStat_1 100;
BA_ "GenSigStartValue" SG_ 2365538239 WiperStalkStat_1 7;
BA_ "GenSigMaxLatency" SG_ 2365538239 WiperStalkStat_1 27;
BA_ "Platform_VMCU1_Sig" SG_ 2365538239 WiperStalkStat_1 1;
BA_ "SeToolAncestorID_SIGNAL" SG_ 2365538239 WiperStalkStat_1 "x0000001D042420F0";
BA_ "SeToolItemID_SIGNAL" SG_ 2365538239 WiperStalkStat_1 "x0000001D0428E669";
BA_ "SeToolName_SIGNAL" SG_ 2365538239 WiperStalkStat_1 "WiperStalkStat_1";
BA_ "SeToolVersion_SIGNAL" SG_ 2365538239 WiperStalkStat_1 "3";
BA_ "GenSigCycleTime" SG_ 2365538239 RequestForHighestGearRatio 100;
BA_ "GenSigCycleTimeActive" SG_ 2365538239 RequestForHighestGearRatio 100;
BA_ "GenSigStartValue" SG_ 2365538239 RequestForHighestGearRatio 3;
BA_ "GenSigMaxLatency" SG_ 2365538239 RequestForHighestGearRatio 26;
BA_ "Platform_VMCU1_Sig" SG_ 2365538239 RequestForHighestGearRatio 1;
BA_ "SeToolAncestorID_SIGNAL" SG_ 2365538239 RequestForHighestGearRatio "x0000001D0416F366";
BA_ "SeToolItemID_SIGNAL" SG_ 2365538239 RequestForHighestGearRatio "x0000001D0416F366";
BA_ "SeToolName_SIGNAL" SG_ 2365538239 RequestForHighestGearRatio "RequestForHighestGearRatio";
BA_ "SeToolVersion_SIGNAL" SG_ 2365538239 RequestForHighestGearRatio "1";
BA_ "GenSigCycleTime" SG_ 2365538239 RequestedUpshiftDownshiftSteps 100;
BA_ "GenSigCycleTimeActive" SG_ 2365538239 RequestedUpshiftDownshiftSteps 100;
BA_ "GenSigStartValue" SG_ 2365538239 RequestedUpshiftDownshiftSteps 7;
BA_ "GenSigMaxLatency" SG_ 2365538239 RequestedUpshiftDownshiftSteps 26;
BA_ "Platform_VMCU1_Sig" SG_ 2365538239 RequestedUpshiftDownshiftSteps 1;
BA_ "SeToolAncestorID_SIGNAL" SG_ 2365538239 RequestedUpshiftDownshiftSteps "x0000001D041B21AC";
BA_ "SeToolItemID_SIGNAL" SG_ 2365538239 RequestedUpshiftDownshiftSteps "x0000001D041B21AC";
BA_ "SeToolName_SIGNAL" SG_ 2365538239 RequestedUpshiftDownshiftSteps "RequestedUpshiftDownshiftSteps";
BA_ "SeToolVersion_SIGNAL" SG_ 2365538239 RequestedUpshiftDownshiftSteps "1";
BA_ "GenSigCycleTime" SG_ 2365538239 WiperAdjustStatus_1 100;
BA_ "GenSigCycleTimeActive" SG_ 2365538239 WiperAdjustStatus_1 100;
BA_ "GenSigStartValue" SG_ 2365538239 WiperAdjustStatus_1 7;
BA_ "GenSigMaxLatency" SG_ 2365538239 WiperAdjustStatus_1 27;
BA_ "Platform_VMCU1_Sig" SG_ 2365538239 WiperAdjustStatus_1 1;
BA_ "SeToolAncestorID_SIGNAL" SG_ 2365538239 WiperAdjustStatus_1 "x0000001D0424D10B";
BA_ "SeToolItemID_SIGNAL" SG_ 2365538239 WiperAdjustStatus_1 "x0000001D0425FC1C";
BA_ "SeToolName_SIGNAL" SG_ 2365538239 WiperAdjustStatus_1 "WiperAdjustStatus_1";
BA_ "SeToolVersion_SIGNAL" SG_ 2365538239 WiperAdjustStatus_1 "2";
BA_ "GenSigCycleTime" SG_ 2365538239 UpShiftRequest 100;
BA_ "GenSigCycleTimeActive" SG_ 2365538239 UpShiftRequest 100;
BA_ "GenSigStartValue" SG_ 2365538239 UpShiftRequest 3;
BA_ "GenSigMaxLatency" SG_ 2365538239 UpShiftRequest 26;
BA_ "Platform_VMCU1_Sig" SG_ 2365538239 UpShiftRequest 1;
BA_ "SeToolAncestorID_SIGNAL" SG_ 2365538239 UpShiftRequest "x0000001D0416F32D";
BA_ "SeToolItemID_SIGNAL" SG_ 2365538239 UpShiftRequest "x0000001D0416F32D";
BA_ "SeToolName_SIGNAL" SG_ 2365538239 UpShiftRequest "UpShiftRequest";
BA_ "SeToolVersion_SIGNAL" SG_ 2365538239 UpShiftRequest "1";
BA_ "GenSigCycleTime" SG_ 2365538239 MainBeam_StalkStatus_1 100;
BA_ "GenSigCycleTimeActive" SG_ 2365538239 MainBeam_StalkStatus_1 100;
BA_ "GenSigStartValue" SG_ 2365538239 MainBeam_StalkStatus_1 7;
BA_ "GenSigMaxLatency" SG_ 2365538239 MainBeam_StalkStatus_1 29;
BA_ "Platform_VMCU1_Sig" SG_ 2365538239 MainBeam_StalkStatus_1 1;
BA_ "SeToolAncestorID_SIGNAL" SG_ 2365538239 MainBeam_StalkStatus_1 "x0000001D04261500";
BA_ "SeToolItemID_SIGNAL" SG_ 2365538239 MainBeam_StalkStatus_1 "x0000001D04292983";
BA_ "SeToolName_SIGNAL" SG_ 2365538239 MainBeam_StalkStatus_1 "MainBeam_StalkStatus_1";
BA_ "SeToolVersion_SIGNAL" SG_ 2365538239 MainBeam_StalkStatus_1 "2";
BA_ "GenSigCycleTime" SG_ 2365538239 DirInd_StalkStatus_1 100;
BA_ "GenSigCycleTimeActive" SG_ 2365538239 DirInd_StalkStatus_1 100;
BA_ "GenSigStartValue" SG_ 2365538239 DirInd_StalkStatus_1 7;
BA_ "GenSigMaxLatency" SG_ 2365538239 DirInd_StalkStatus_1 27;
BA_ "Platform_VMCU1_Sig" SG_ 2365538239 DirInd_StalkStatus_1 1;
BA_ "SeToolAncestorID_SIGNAL" SG_ 2365538239 DirInd_StalkStatus_1 "x0000001D04261502";
BA_ "SeToolItemID_SIGNAL" SG_ 2365538239 DirInd_StalkStatus_1 "x0000001D043A8A48";
BA_ "SeToolName_SIGNAL" SG_ 2365538239 DirInd_StalkStatus_1 "DirInd_StalkStatus_1";
BA_ "SeToolVersion_SIGNAL" SG_ 2365538239 DirInd_StalkStatus_1 "3";
BA_ "GenSigCycleTime" SG_ 2365538239 LimpHomeSwitch_stat 100;
BA_ "GenSigCycleTimeActive" SG_ 2365538239 LimpHomeSwitch_stat 100;
BA_ "GenSigStartValue" SG_ 2365538239 LimpHomeSwitch_stat 3;
BA_ "GenSigMaxLatency" SG_ 2365538239 LimpHomeSwitch_stat 26;
BA_ "Platform_VMCU1_Sig" SG_ 2365538239 LimpHomeSwitch_stat 1;
BA_ "SeToolAncestorID_SIGNAL" SG_ 2365538239 LimpHomeSwitch_stat "x0000001D0423C430";
BA_ "SeToolItemID_SIGNAL" SG_ 2365538239 LimpHomeSwitch_stat "x0000001D0423C430";
BA_ "SeToolName_SIGNAL" SG_ 2365538239 LimpHomeSwitch_stat "LimpHomeSwitch_stat";
BA_ "SeToolVersion_SIGNAL" SG_ 2365538239 LimpHomeSwitch_stat "1";
BA_ "GenSigSendType" SG_ 2365538239 GearLeverPosition_UB_ISig_4 7;
BA_ "Platform_VMCU1_Sig" SG_ 2365538239 GearLeverPosition_UB_ISig_4 1;
BA_ "GenSigCycleTime" SG_ 2365538239 Washing_Status_2 100;
BA_ "GenSigCycleTimeActive" SG_ 2365538239 Washing_Status_2 100;
BA_ "GenSigStartValue" SG_ 2365538239 Washing_Status_2 3;
BA_ "GenSigMaxLatency" SG_ 2365538239 Washing_Status_2 27;
BA_ "Platform_VMCU1_Sig" SG_ 2365538239 Washing_Status_2 1;
BA_ "SeToolAncestorID_SIGNAL" SG_ 2365538239 Washing_Status_2 "x0000001D0423D46E";
BA_ "SeToolItemID_SIGNAL" SG_ 2365538239 Washing_Status_2 "x0000001D04296506";
BA_ "SeToolName_SIGNAL" SG_ 2365538239 Washing_Status_2 "Washing_Status_2";
BA_ "SeToolVersion_SIGNAL" SG_ 2365538239 Washing_Status_2 "3";
BA_ "GenSigCycleTime" SG_ 2365538239 EconomyPowerSwitch_stat 100;
BA_ "GenSigCycleTimeActive" SG_ 2365538239 EconomyPowerSwitch_stat 100;
BA_ "GenSigStartValue" SG_ 2365538239 EconomyPowerSwitch_stat 3;
BA_ "GenSigMaxLatency" SG_ 2365538239 EconomyPowerSwitch_stat 26;
BA_ "Platform_VMCU1_Sig" SG_ 2365538239 EconomyPowerSwitch_stat 1;
BA_ "SeToolAncestorID_SIGNAL" SG_ 2365538239 EconomyPowerSwitch_stat "x0000001D0423C42E";
BA_ "SeToolItemID_SIGNAL" SG_ 2365538239 EconomyPowerSwitch_stat "x0000001D0423C42E";
BA_ "SeToolName_SIGNAL" SG_ 2365538239 EconomyPowerSwitch_stat "EconomyPowerSwitch_stat";
BA_ "SeToolVersion_SIGNAL" SG_ 2365538239 EconomyPowerSwitch_stat "1";
BA_ "GenSigCycleTime" SG_ 2365538239 GearLeverPosition_ISig_4 100;
BA_ "GenSigCycleTimeActive" SG_ 2365538239 GearLeverPosition_ISig_4 100;
BA_ "GenSigStartValue" SG_ 2365538239 GearLeverPosition_ISig_4 15;
BA_ "GenSigMaxLatency" SG_ 2365538239 GearLeverPosition_ISig_4 26;
BA_ "NeedsUpdateBit" SG_ 2365538239 GearLeverPosition_ISig_4 1;
BA_ "Platform_VMCU1_Sig" SG_ 2365538239 GearLeverPosition_ISig_4 1;
BA_ "SeToolAncestorID_SIGNAL" SG_ 2365538239 GearLeverPosition_ISig_4 "x0000001D0412B683";
BA_ "SeToolItemID_SIGNAL" SG_ 2365538239 GearLeverPosition_ISig_4 "x0000001D0412B683";
BA_ "SeToolName_SIGNAL" SG_ 2365538239 GearLeverPosition_ISig_4 "GearLeverPosition";
BA_ "SeToolVersion_SIGNAL" SG_ 2365538239 GearLeverPosition_ISig_4 "1";
BA_ "GenSigCycleTime" SG_ 2365538239 DownShiftRequest 100;
BA_ "GenSigCycleTimeActive" SG_ 2365538239 DownShiftRequest 100;
BA_ "GenSigStartValue" SG_ 2365538239 DownShiftRequest 3;
BA_ "GenSigMaxLatency" SG_ 2365538239 DownShiftRequest 26;
BA_ "Platform_VMCU1_Sig" SG_ 2365538239 DownShiftRequest 1;
BA_ "SeToolAncestorID_SIGNAL" SG_ 2365538239 DownShiftRequest "x0000001D0416F343";
BA_ "SeToolItemID_SIGNAL" SG_ 2365538239 DownShiftRequest "x0000001D0428EB01";
BA_ "SeToolName_SIGNAL" SG_ 2365538239 DownShiftRequest "DownShiftRequest";
BA_ "SeToolVersion_SIGNAL" SG_ 2365538239 DownShiftRequest "2";
BA_ "GenSigCycleTime" SG_ 2365538239 MainBeam_StalkStatus_2 100;
BA_ "GenSigCycleTimeActive" SG_ 2365538239 MainBeam_StalkStatus_2 100;
BA_ "GenSigStartValue" SG_ 2365538239 MainBeam_StalkStatus_2 7;
BA_ "GenSigMaxLatency" SG_ 2365538239 MainBeam_StalkStatus_2 29;
BA_ "Platform_VMCU1_Sig" SG_ 2365538239 MainBeam_StalkStatus_2 1;
BA_ "SeToolAncestorID_SIGNAL" SG_ 2365538239 MainBeam_StalkStatus_2 "x0000001D04261500";
BA_ "SeToolItemID_SIGNAL" SG_ 2365538239 MainBeam_StalkStatus_2 "x0000001D04292983";
BA_ "SeToolName_SIGNAL" SG_ 2365538239 MainBeam_StalkStatus_2 "MainBeam_StalkStatus_2";
BA_ "SeToolVersion_SIGNAL" SG_ 2365538239 MainBeam_StalkStatus_2 "2";
BA_ "GenSigCycleTime" SG_ 2365538239 DirInd_StalkStatus_2 100;
BA_ "GenSigCycleTimeActive" SG_ 2365538239 DirInd_StalkStatus_2 100;
BA_ "GenSigStartValue" SG_ 2365538239 DirInd_StalkStatus_2 7;
BA_ "GenSigMaxLatency" SG_ 2365538239 DirInd_StalkStatus_2 27;
BA_ "Platform_VMCU1_Sig" SG_ 2365538239 DirInd_StalkStatus_2 1;
BA_ "SeToolAncestorID_SIGNAL" SG_ 2365538239 DirInd_StalkStatus_2 "x0000001D04261502";
BA_ "SeToolItemID_SIGNAL" SG_ 2365538239 DirInd_StalkStatus_2 "x0000001D043A8A48";
BA_ "SeToolName_SIGNAL" SG_ 2365538239 DirInd_StalkStatus_2 "DirInd_StalkStatus_2";
BA_ "SeToolVersion_SIGNAL" SG_ 2365538239 DirInd_StalkStatus_2 "3";
BA_ "GenSigCycleTime" SG_ 2365538239 RetarderStalkPosition_1 100;
BA_ "GenSigCycleTimeActive" SG_ 2365538239 RetarderStalkPosition_1 100;
BA_ "GenSigStartValue" SG_ 2365538239 RetarderStalkPosition_1 15;
BA_ "GenSigMaxLatency" SG_ 2365538239 RetarderStalkPosition_1 89;
BA_ "Platform_VMCU1_Sig" SG_ 2365538239 RetarderStalkPosition_1 1;
BA_ "SeToolAncestorID_SIGNAL" SG_ 2365538239 RetarderStalkPosition_1 "x0000001D0425D2F4";
BA_ "SeToolItemID_SIGNAL" SG_ 2365538239 RetarderStalkPosition_1 "x0000001D0425D2F4";
BA_ "SeToolName_SIGNAL" SG_ 2365538239 RetarderStalkPosition_1 "RetarderStalkPosition_1";
BA_ "SeToolVersion_SIGNAL" SG_ 2365538239 RetarderStalkPosition_1 "1";
BA_ "GenSigCycleTime" SG_ 2365538239 RetarderStalkPosition_2 100;
BA_ "GenSigCycleTimeActive" SG_ 2365538239 RetarderStalkPosition_2 100;
BA_ "GenSigStartValue" SG_ 2365538239 RetarderStalkPosition_2 15;
BA_ "Platform_VMCU1_Sig" SG_ 2365538239 RetarderStalkPosition_2 1;
BA_ "SeToolAncestorID_SIGNAL" SG_ 2365538239 RetarderStalkPosition_2 "x0000001D0425D2F4";
BA_ "SeToolItemID_SIGNAL" SG_ 2365538239 RetarderStalkPosition_2 "x0000001D0425D2F4";
BA_ "SeToolName_SIGNAL" SG_ 2365538239 RetarderStalkPosition_2 "RetarderStalkPosition_2";
BA_ "SeToolVersion_SIGNAL" SG_ 2365538239 RetarderStalkPosition_2 "1";
BA_ "GenSigCycleTime" SG_ 2365538239 EcoRollEnableRequest_ISig_4 100;
BA_ "GenSigCycleTimeActive" SG_ 2365538239 EcoRollEnableRequest_ISig_4 100;
BA_ "GenSigStartValue" SG_ 2365538239 EcoRollEnableRequest_ISig_4 3;
BA_ "Platform_VMCU1_Sig" SG_ 2365538239 EcoRollEnableRequest_ISig_4 1;
BA_ "GenSigCycleTime" SG_ 2365538239 Washing_Status_1 100;
BA_ "GenSigCycleTimeActive" SG_ 2365538239 Washing_Status_1 100;
BA_ "GenSigStartValue" SG_ 2365538239 Washing_Status_1 3;
BA_ "GenSigMaxLatency" SG_ 2365538239 Washing_Status_1 27;
BA_ "Platform_VMCU1_Sig" SG_ 2365538239 Washing_Status_1 1;
BA_ "SeToolAncestorID_SIGNAL" SG_ 2365538239 Washing_Status_1 "x0000001D0423D46E";
BA_ "SeToolItemID_SIGNAL" SG_ 2365538239 Washing_Status_1 "x0000001D04296506";
BA_ "SeToolName_SIGNAL" SG_ 2365538239 Washing_Status_1 "Washing_Status_1";
BA_ "SeToolVersion_SIGNAL" SG_ 2365538239 Washing_Status_1 "3";
BA_ "GenSigCycleTime" SG_ 2365538239 SelectedEcoCruiseLevel_ISig_4 100;
BA_ "GenSigCycleTimeActive" SG_ 2365538239 SelectedEcoCruiseLevel_ISig_4 100;
BA_ "GenSigStartValue" SG_ 2365538239 SelectedEcoCruiseLevel_ISig_4 7;
BA_ "Platform_VMCU1_Sig" SG_ 2365538239 SelectedEcoCruiseLevel_ISig_4 1;
BA_ "GenSigCycleTime" SG_ 2365538239 WiperStalkStat_2 100;
BA_ "GenSigCycleTimeActive" SG_ 2365538239 WiperStalkStat_2 100;
BA_ "GenSigStartValue" SG_ 2365538239 WiperStalkStat_2 7;
BA_ "GenSigMaxLatency" SG_ 2365538239 WiperStalkStat_2 27;
BA_ "Platform_VMCU1_Sig" SG_ 2365538239 WiperStalkStat_2 1;
BA_ "SeToolAncestorID_SIGNAL" SG_ 2365538239 WiperStalkStat_2 "x0000001D042420F0";
BA_ "SeToolItemID_SIGNAL" SG_ 2365538239 WiperStalkStat_2 "x0000001D0428E669";
BA_ "SeToolName_SIGNAL" SG_ 2365538239 WiperStalkStat_2 "WiperStalkStat_2";
BA_ "SeToolVersion_SIGNAL" SG_ 2365538239 WiperStalkStat_2 "3";
BA_ "GenSigCycleTime" SG_ 2432634208 IdleAdjustDeactivationRequest 100;
BA_ "GenSigCycleTimeActive" SG_ 2432634208 IdleAdjustDeactivationRequest 100;
BA_ "GenSigStartValue" SG_ 2432634208 IdleAdjustDeactivationRequest 3;
BA_ "Platform_VMCU1_Sig" SG_ 2432634208 IdleAdjustDeactivationRequest 1;
BA_ "GenSigCycleTime" SG_ 2432634208 ACMode_Selection_ISig_4 100;
BA_ "GenSigCycleTimeActive" SG_ 2432634208 ACMode_Selection_ISig_4 100;
BA_ "GenSigStartValue" SG_ 2432634208 ACMode_Selection_ISig_4 7;
BA_ "GenSigMaxLatency" SG_ 2432634208 ACMode_Selection_ISig_4 26;
BA_ "Platform_VMCU1_Sig" SG_ 2432634208 ACMode_Selection_ISig_4 1;
BA_ "SeToolAncestorID_SIGNAL" SG_ 2432634208 ACMode_Selection_ISig_4 "x0000001D04410743";
BA_ "SeToolItemID_SIGNAL" SG_ 2432634208 ACMode_Selection_ISig_4 "x0000001D04410743";
BA_ "SeToolName_SIGNAL" SG_ 2432634208 ACMode_Selection_ISig_4 "ACMode_Selection";
BA_ "SeToolVersion_SIGNAL" SG_ 2432634208 ACMode_Selection_ISig_4 "1";
BA_ "GenSigCycleTime" SG_ 2432634208 TripmeterReset_rqst_ISig_4 100;
BA_ "GenSigCycleTimeActive" SG_ 2432634208 TripmeterReset_rqst_ISig_4 100;
BA_ "GenSigStartValue" SG_ 2432634208 TripmeterReset_rqst_ISig_4 7;
BA_ "GenSigMaxLatency" SG_ 2432634208 TripmeterReset_rqst_ISig_4 26;
BA_ "Platform_VMCU1_Sig" SG_ 2432634208 TripmeterReset_rqst_ISig_4 1;
BA_ "SeToolAncestorID_SIGNAL" SG_ 2432634208 TripmeterReset_rqst_ISig_4 "x0000001D04172B22";
BA_ "SeToolItemID_SIGNAL" SG_ 2432634208 TripmeterReset_rqst_ISig_4 "x0000001D0435826E";
BA_ "SeToolName_SIGNAL" SG_ 2432634208 TripmeterReset_rqst_ISig_4 "TripmeterReset_rqst";
BA_ "SeToolVersion_SIGNAL" SG_ 2432634208 TripmeterReset_rqst_ISig_4 "3";
BA_ "GenSigCycleTime" SG_ 2432634208 WaterInFuelDrainRequest 100;
BA_ "GenSigCycleTimeActive" SG_ 2432634208 WaterInFuelDrainRequest 100;
BA_ "GenSigMaxLatency" SG_ 2432634208 WaterInFuelDrainRequest 26;
BA_ "Platform_VMCU1_Sig" SG_ 2432634208 WaterInFuelDrainRequest 1;
BA_ "SeToolAncestorID_SIGNAL" SG_ 2432634208 WaterInFuelDrainRequest "x0000001D041410E9";
BA_ "SeToolItemID_SIGNAL" SG_ 2432634208 WaterInFuelDrainRequest "x0000001D041410E9";
BA_ "SeToolName_SIGNAL" SG_ 2432634208 WaterInFuelDrainRequest "WaterInFuelDrainRequest";
BA_ "SeToolVersion_SIGNAL" SG_ 2432634208 WaterInFuelDrainRequest "1";
BA_ "GenSigCycleTime" SG_ 2432634208 FuncIndIlluminationLevel_ISig_4 100;
BA_ "GenSigCycleTimeActive" SG_ 2432634208 FuncIndIlluminationLevel_ISig_4 100;
BA_ "GenSigStartValue" SG_ 2432634208 FuncIndIlluminationLevel_ISig_4 1;
BA_ "GenSigMaxLatency" SG_ 2432634208 FuncIndIlluminationLevel_ISig_4 26;
BA_ "Platform_VMCU1_Sig" SG_ 2432634208 FuncIndIlluminationLevel_ISig_4 1;
BA_ "SeToolAncestorID_SIGNAL" SG_ 2432634208 FuncIndIlluminationLevel_ISig_4 "x0000001D043A8396";
BA_ "SeToolItemID_SIGNAL" SG_ 2432634208 FuncIndIlluminationLevel_ISig_4 "x0000001D043A8396";
BA_ "SeToolName_SIGNAL" SG_ 2432634208 FuncIndIlluminationLevel_ISig_4 "FuncIndIlluminationLevel";
BA_ "SeToolVersion_SIGNAL" SG_ 2432634208 FuncIndIlluminationLevel_ISig_4 "1";
BA_ "GenSigCycleTime" SG_ 2432634208 IdleAdjustActivationRequest 100;
BA_ "GenSigCycleTimeActive" SG_ 2432634208 IdleAdjustActivationRequest 100;
BA_ "GenSigStartValue" SG_ 2432634208 IdleAdjustActivationRequest 3;
BA_ "Platform_VMCU1_Sig" SG_ 2432634208 IdleAdjustActivationRequest 1;
BA_ "GenSigCycleTime" SG_ 2432634208 AutoDefogmode_Selection_ISig_4 100;
BA_ "GenSigCycleTimeActive" SG_ 2432634208 AutoDefogmode_Selection_ISig_4 100;
BA_ "GenSigStartValue" SG_ 2432634208 AutoDefogmode_Selection_ISig_4 7;
BA_ "GenSigMaxLatency" SG_ 2432634208 AutoDefogmode_Selection_ISig_4 26;
BA_ "Platform_VMCU1_Sig" SG_ 2432634208 AutoDefogmode_Selection_ISig_4 1;
BA_ "SeToolAncestorID_SIGNAL" SG_ 2432634208 AutoDefogmode_Selection_ISig_4 "x0000001D04410A66";
BA_ "SeToolItemID_SIGNAL" SG_ 2432634208 AutoDefogmode_Selection_ISig_4 "x0000001D04410A66";
BA_ "SeToolName_SIGNAL" SG_ 2432634208 AutoDefogmode_Selection_ISig_4 "AutoDefogmode_Selection";
BA_ "SeToolVersion_SIGNAL" SG_ 2432634208 AutoDefogmode_Selection_ISig_4 "1";
BA_ "GenSigCycleTime" SG_ 2432634208 ResumeRequestForACC_ISig_4 100;
BA_ "GenSigCycleTimeActive" SG_ 2432634208 ResumeRequestForACC_ISig_4 100;
BA_ "GenSigStartValue" SG_ 2432634208 ResumeRequestForACC_ISig_4 3;
BA_ "GenSigCycleTime" SG_ 2432634208 AudioMuteStat_ISig_4 100;
BA_ "GenSigCycleTimeActive" SG_ 2432634208 AudioMuteStat_ISig_4 100;
BA_ "GenSigStartValue" SG_ 2432634208 AudioMuteStat_ISig_4 7;
BA_ "Platform_VMCU1_Sig" SG_ 2432634208 AudioMuteStat_ISig_4 1;
BA_ "SeToolAncestorID_SIGNAL" SG_ 2432634208 AudioMuteStat_ISig_4 "x0000001D043278F0";
BA_ "SeToolItemID_SIGNAL" SG_ 2432634208 AudioMuteStat_ISig_4 "x0000001D043278F0";
BA_ "SeToolName_SIGNAL" SG_ 2432634208 AudioMuteStat_ISig_4 "AudioMuteStat";
BA_ "SeToolVersion_SIGNAL" SG_ 2432634208 AudioMuteStat_ISig_4 "1";
BA_ "GenSigCycleTime" SG_ 2432634208 IdleAdjustTrimGuiEventCmd 100;
BA_ "GenSigCycleTimeActive" SG_ 2432634208 IdleAdjustTrimGuiEventCmd 100;
BA_ "GenSigStartValue" SG_ 2432634208 IdleAdjustTrimGuiEventCmd 7;
BA_ "Platform_VMCU1_Sig" SG_ 2432634208 IdleAdjustTrimGuiEventCmd 1;
BA_ "GenSigCycleTime" SG_ 2432634208 IdleAdjustStoreRequest 100;
BA_ "GenSigCycleTimeActive" SG_ 2432634208 IdleAdjustStoreRequest 100;
BA_ "GenSigStartValue" SG_ 2432634208 IdleAdjustStoreRequest 3;
BA_ "Platform_VMCU1_Sig" SG_ 2432634208 IdleAdjustStoreRequest 1;
BA_ "GenSigCycleTime" SG_ 2432634208 SWSpeedControlAdjustMode 100;
BA_ "GenSigCycleTimeActive" SG_ 2432634208 SWSpeedControlAdjustMode 100;
BA_ "GenSigStartValue" SG_ 2432634208 SWSpeedControlAdjustMode 15;
BA_ "GenSigMaxLatency" SG_ 2432634208 SWSpeedControlAdjustMode 89;
BA_ "Platform_VMCU1_Sig" SG_ 2432634208 SWSpeedControlAdjustMode 1;
BA_ "GenSigCycleTime" SG_ 2432634208 ACCTimeGapRqst_ISig_4 100;
BA_ "GenSigCycleTimeActive" SG_ 2432634208 ACCTimeGapRqst_ISig_4 100;
BA_ "GenSigStartValue" SG_ 2432634208 ACCTimeGapRqst_ISig_4 7;
BA_ "GenSigMaxLatency" SG_ 2432634208 ACCTimeGapRqst_ISig_4 26;
BA_ "Platform_VMCU1_Sig" SG_ 2432634208 ACCTimeGapRqst_ISig_4 1;
BA_ "SeToolAncestorID_SIGNAL" SG_ 2432634208 ACCTimeGapRqst_ISig_4 "x0000001D04146F87";
BA_ "SeToolItemID_SIGNAL" SG_ 2432634208 ACCTimeGapRqst_ISig_4 "x0000001D0420F337";
BA_ "SeToolName_SIGNAL" SG_ 2432634208 ACCTimeGapRqst_ISig_4 "ACCTimeGapRqst";
BA_ "SeToolVersion_SIGNAL" SG_ 2432634208 ACCTimeGapRqst_ISig_4 "2";
BA_ "GenSigCycleTime" SG_ 2432634208 AQSMode_Selection_ISig_4 100;
BA_ "GenSigCycleTimeActive" SG_ 2432634208 AQSMode_Selection_ISig_4 100;
BA_ "GenSigStartValue" SG_ 2432634208 AQSMode_Selection_ISig_4 3;
BA_ "GenSigMaxLatency" SG_ 2432634208 AQSMode_Selection_ISig_4 26;
BA_ "Platform_VMCU1_Sig" SG_ 2432634208 AQSMode_Selection_ISig_4 1;
BA_ "SeToolAncestorID_SIGNAL" SG_ 2432634208 AQSMode_Selection_ISig_4 "x0000001D044108B3";
BA_ "SeToolItemID_SIGNAL" SG_ 2432634208 AQSMode_Selection_ISig_4 "x0000001D044108B3";
BA_ "SeToolName_SIGNAL" SG_ 2432634208 AQSMode_Selection_ISig_4 "AQSMode_Selection";
BA_ "SeToolVersion_SIGNAL" SG_ 2432634208 AQSMode_Selection_ISig_4 "1";
BA_ "GenSigCycleTime" SG_ 2432634208 ACCEnableRqst_ISig_4 100;
BA_ "GenSigCycleTimeActive" SG_ 2432634208 ACCEnableRqst_ISig_4 100;
BA_ "GenSigStartValue" SG_ 2432634208 ACCEnableRqst_ISig_4 3;
BA_ "GenSigMaxLatency" SG_ 2432634208 ACCEnableRqst_ISig_4 26;
BA_ "Platform_VMCU1_Sig" SG_ 2432634208 ACCEnableRqst_ISig_4 1;
BA_ "SeToolAncestorID_SIGNAL" SG_ 2432634208 ACCEnableRqst_ISig_4 "x0000001D0414B8A6";
BA_ "SeToolItemID_SIGNAL" SG_ 2432634208 ACCEnableRqst_ISig_4 "x0000001D0414B8A6";
BA_ "SeToolName_SIGNAL" SG_ 2432634208 ACCEnableRqst_ISig_4 "ACCEnableRqst";
BA_ "SeToolVersion_SIGNAL" SG_ 2432634208 ACCEnableRqst_ISig_4 "1";
BA_ "GenSigCycleTime" SG_ 2432634208 StopAlert_cmd_ISig_4 100;
BA_ "GenSigCycleTimeActive" SG_ 2432634208 StopAlert_cmd_ISig_4 100;
BA_ "GenSigStartValue" SG_ 2432634208 StopAlert_cmd_ISig_4 7;
BA_ "Platform_VMCU1_Sig" SG_ 2432634208 StopAlert_cmd_ISig_4 1;
BA_ "SeToolAncestorID_SIGNAL" SG_ 2432634208 StopAlert_cmd_ISig_4 "x0000001D04182F7F";
BA_ "SeToolItemID_SIGNAL" SG_ 2432634208 StopAlert_cmd_ISig_4 "x0000001D04295469";
BA_ "SeToolName_SIGNAL" SG_ 2432634208 StopAlert_cmd_ISig_4 "StopAlert_cmd";
BA_ "SeToolVersion_SIGNAL" SG_ 2432634208 StopAlert_cmd_ISig_4 "4";
BA_ "GenSigCycleTime" SG_ 2432634208 BacklightCmd_ISig_4 100;
BA_ "GenSigCycleTimeActive" SG_ 2432634208 BacklightCmd_ISig_4 100;
BA_ "GenSigMaxLatency" SG_ 2432634208 BacklightCmd_ISig_4 26;
BA_ "Platform_VMCU1_Sig" SG_ 2432634208 BacklightCmd_ISig_4 1;
BA_ "SeToolAncestorID_SIGNAL" SG_ 2432634208 BacklightCmd_ISig_4 "x0000001D0439DDD1";
BA_ "SeToolItemID_SIGNAL" SG_ 2432634208 BacklightCmd_ISig_4 "x0000001D043A84D3";
BA_ "SeToolName_SIGNAL" SG_ 2432634208 BacklightCmd_ISig_4 "BacklightCmd";
BA_ "SeToolVersion_SIGNAL" SG_ 2432634208 BacklightCmd_ISig_4 "2";
BA_ "GenSigCycleTime" SG_ 2432634208 AutoBlowerLevel_Selection_ISig_4 100;
BA_ "GenSigCycleTimeActive" SG_ 2432634208 AutoBlowerLevel_Selection_ISig_4 100;
BA_ "GenSigStartValue" SG_ 2432634208 AutoBlowerLevel_Selection_ISig_4 7;
BA_ "GenSigMaxLatency" SG_ 2432634208 AutoBlowerLevel_Selection_ISig_4 26;
BA_ "Platform_VMCU1_Sig" SG_ 2432634208 AutoBlowerLevel_Selection_ISig_4 1;
BA_ "SeToolAncestorID_SIGNAL" SG_ 2432634208 AutoBlowerLevel_Selection_ISig_4 "x0000001D0441090E";
BA_ "SeToolItemID_SIGNAL" SG_ 2432634208 AutoBlowerLevel_Selection_ISig_4 "x0000001D0441090E";
BA_ "SeToolName_SIGNAL" SG_ 2432634208 AutoBlowerLevel_Selection_ISig_4 "AutoBlowerLevel_Selection";
BA_ "SeToolVersion_SIGNAL" SG_ 2432634208 AutoBlowerLevel_Selection_ISig_4 "1";
BA_ "GenSigCycleTime" SG_ 2432634208 CMTelltale_stat_ISig_4 100;
BA_ "GenSigCycleTimeActive" SG_ 2432634208 CMTelltale_stat_ISig_4 100;
BA_ "GenSigStartValue" SG_ 2432634208 CMTelltale_stat_ISig_4 7;
BA_ "Platform_VMCU1_Sig" SG_ 2432634208 CMTelltale_stat_ISig_4 1;
BA_ "GenSigCycleTime" SG_ 2432634208 SWSpdCtrlButtonsStatus1 100;
BA_ "GenSigCycleTimeActive" SG_ 2432634208 SWSpdCtrlButtonsStatus1 100;
BA_ "GenSigStartValue" SG_ 2432634208 SWSpdCtrlButtonsStatus1 15;
BA_ "GenSigMaxLatency" SG_ 2432634208 SWSpdCtrlButtonsStatus1 89;
BA_ "Platform_VMCU1_Sig" SG_ 2432634208 SWSpdCtrlButtonsStatus1 1;
BA_ "GenSigCycleTime" SG_ 2499755792 SCR_SulphurLevel_ISig_4 100;
BA_ "GenSigCycleTimeActive" SG_ 2499755792 SCR_SulphurLevel_ISig_4 100;
BA_ "GenSigStartValue" SG_ 2499755792 SCR_SulphurLevel_ISig_4 255;
BA_ "GenSigMaxLatency" SG_ 2499755792 SCR_SulphurLevel_ISig_4 59;
BA_ "GenSigCycleTime" SG_ 2549479952 EcoCruisePwtMaxOvSpeedLev3 100;
BA_ "GenSigCycleTimeActive" SG_ 2549479952 EcoCruisePwtMaxOvSpeedLev3 100;
BA_ "GenSigStartValue" SG_ 2549479952 EcoCruisePwtMaxOvSpeedLev3 31;
BA_ "Platform_VMCU1_Sig" SG_ 2549479952 EcoCruisePwtMaxOvSpeedLev3 1;
BA_ "GenSigCycleTime" SG_ 2549479952 EcoCruisePwtMaxOvSpeedLev0 100;
BA_ "GenSigCycleTimeActive" SG_ 2549479952 EcoCruisePwtMaxOvSpeedLev0 100;
BA_ "GenSigStartValue" SG_ 2549479952 EcoCruisePwtMaxOvSpeedLev0 31;
BA_ "Platform_VMCU1_Sig" SG_ 2549479952 EcoCruisePwtMaxOvSpeedLev0 1;
BA_ "GenSigCycleTime" SG_ 2549479952 EcoCruisePwtMaxUnSpeedLev0 100;
BA_ "GenSigCycleTimeActive" SG_ 2549479952 EcoCruisePwtMaxUnSpeedLev0 100;
BA_ "GenSigStartValue" SG_ 2549479952 EcoCruisePwtMaxUnSpeedLev0 31;
BA_ "Platform_VMCU1_Sig" SG_ 2549479952 EcoCruisePwtMaxUnSpeedLev0 1;
BA_ "GenSigCycleTime" SG_ 2549479952 EcoCruisePwtMaxOvSpeedLev2 100;
BA_ "GenSigCycleTimeActive" SG_ 2549479952 EcoCruisePwtMaxOvSpeedLev2 100;
BA_ "GenSigStartValue" SG_ 2549479952 EcoCruisePwtMaxOvSpeedLev2 31;
BA_ "Platform_VMCU1_Sig" SG_ 2549479952 EcoCruisePwtMaxOvSpeedLev2 1;
BA_ "GenSigCycleTime" SG_ 2549479952 EcoCruisePwtMaxOvSpeedLev1 100;
BA_ "GenSigCycleTimeActive" SG_ 2549479952 EcoCruisePwtMaxOvSpeedLev1 100;
BA_ "GenSigStartValue" SG_ 2549479952 EcoCruisePwtMaxOvSpeedLev1 31;
BA_ "Platform_VMCU1_Sig" SG_ 2549479952 EcoCruisePwtMaxOvSpeedLev1 1;
BA_ "GenSigCycleTime" SG_ 2549479952 EcoCruisePwtMaxUnSpeedLev3 100;
BA_ "GenSigCycleTimeActive" SG_ 2549479952 EcoCruisePwtMaxUnSpeedLev3 100;
BA_ "GenSigStartValue" SG_ 2549479952 EcoCruisePwtMaxUnSpeedLev3 31;
BA_ "Platform_VMCU1_Sig" SG_ 2549479952 EcoCruisePwtMaxUnSpeedLev3 1;
BA_ "GenSigCycleTime" SG_ 2549479952 EcoCruisePwtMaxUnSpeedLev1 100;
BA_ "GenSigCycleTimeActive" SG_ 2549479952 EcoCruisePwtMaxUnSpeedLev1 100;
BA_ "GenSigStartValue" SG_ 2549479952 EcoCruisePwtMaxUnSpeedLev1 31;
BA_ "Platform_VMCU1_Sig" SG_ 2549479952 EcoCruisePwtMaxUnSpeedLev1 1;
BA_ "GenSigCycleTime" SG_ 2549479952 EcoCruisePwtMaxUnSpeedLev2 100;
BA_ "GenSigCycleTimeActive" SG_ 2549479952 EcoCruisePwtMaxUnSpeedLev2 100;
BA_ "GenSigStartValue" SG_ 2549479952 EcoCruisePwtMaxUnSpeedLev2 31;
BA_ "Platform_VMCU1_Sig" SG_ 2549479952 EcoCruisePwtMaxUnSpeedLev2 1;
BA_ "GenSigCycleTime" SG_ 2549479440 TotPTOLNGHighAccuracy 100;
BA_ "GenSigCycleTimeActive" SG_ 2549479440 TotPTOLNGHighAccuracy 100;
BA_ "GenSigStartValue" SG_ 2549479440 TotPTOLNGHighAccuracy 4294967295;
BA_ "Platform_VMCU1_Sig" SG_ 2549479440 TotPTOLNGHighAccuracy 1;
BA_ "GenSigCycleTime" SG_ 2549478672 EngineFuelMode_ISig_4 100;
BA_ "GenSigCycleTimeActive" SG_ 2549478672 EngineFuelMode_ISig_4 100;
BA_ "GenSigStartValue" SG_ 2549478672 EngineFuelMode_ISig_4 3;
BA_ "Platform_VMCU1_Sig" SG_ 2549478672 EngineFuelMode_ISig_4 1;
BA_ "GenSigCycleTime" SG_ 2549478672 LNGOperatorInducementReason 100;
BA_ "GenSigCycleTimeActive" SG_ 2549478672 LNGOperatorInducementReason 100;
BA_ "GenSigStartValue" SG_ 2549478672 LNGOperatorInducementReason 7;
BA_ "Platform_VMCU1_Sig" SG_ 2549478672 LNGOperatorInducementReason 1;
BA_ "GenSigCycleTime" SG_ 2549478672 DPF_RegenCompleted_ISig_4 100;
BA_ "GenSigCycleTimeActive" SG_ 2549478672 DPF_RegenCompleted_ISig_4 100;
BA_ "GenSigStartValue" SG_ 2549478672 DPF_RegenCompleted_ISig_4 7;
BA_ "Platform_VMCU1_Sig" SG_ 2549478672 DPF_RegenCompleted_ISig_4 1;
BA_ "GenSigCycleTime" SG_ 2549478672 EngineTotalLngConsumed_ISig_4 100;
BA_ "GenSigCycleTimeActive" SG_ 2549478672 EngineTotalLngConsumed_ISig_4 100;
BA_ "GenSigStartValue" SG_ 2549478672 EngineTotalLngConsumed_ISig_4 4294967295;
BA_ "Platform_VMCU1_Sig" SG_ 2549478672 EngineTotalLngConsumed_ISig_4 1;
BA_ "GenSigCycleTime" SG_ 2549478672 SCR_SulphurRegenNeeded_ISig_4 100;
BA_ "GenSigCycleTimeActive" SG_ 2549478672 SCR_SulphurRegenNeeded_ISig_4 100;
BA_ "GenSigStartValue" SG_ 2549478672 SCR_SulphurRegenNeeded_ISig_4 7;
BA_ "GenSigCycleTime" SG_ 2549030928 DistLeftToSevereInducement_OBD_I 100;
BA_ "GenSigCycleTimeActive" SG_ 2549030928 DistLeftToSevereInducement_OBD_I 100;
BA_ "GenSigStartValue" SG_ 2549030928 DistLeftToSevereInducement_OBD_I 255;
BA_ "Platform_VMCU1_Sig" SG_ 2549030928 DistLeftToSevereInducement_OBD_I 1;
BA_ "SystemSignalLongSymbol" SG_ 2549030928 DistLeftToSevereInducement_OBD_I "DistLeftToSevereInducement_OBD_ISig_4";
BA_ "GenSigCycleTime" SG_ 2549030928 RemainingRODTime 100;
BA_ "GenSigCycleTimeActive" SG_ 2549030928 RemainingRODTime 100;
BA_ "GenSigStartValue" SG_ 2549030928 RemainingRODTime 65535;
BA_ "Platform_VMCU1_Sig" SG_ 2549030928 RemainingRODTime 1;
BA_ "GenSigCycleTime" SG_ 2549030928 TopGearUseDistance_ISig_4 100;
BA_ "GenSigCycleTimeActive" SG_ 2549030928 TopGearUseDistance_ISig_4 100;
BA_ "GenSigStartValue" SG_ 2549030928 TopGearUseDistance_ISig_4 4294967295;
BA_ "Platform_VMCU1_Sig" SG_ 2549030928 TopGearUseDistance_ISig_4 1;
BA_ "GenSigSendType" SG_ 2499780369 EMS_BB2_11S_FCS 7;
BA_ "Platform_VMCU1_Sig" SG_ 2499780369 EMS_BB2_11S_FCS 1;
BA_ "GenSigSendType" SG_ 2499780368 KeyID_EngineStartAuth 1;
BA_ "GenSigMaxLatency" SG_ 2499780368 KeyID_EngineStartAuth 100;
BA_ "Platform_VMCU1_Sig" SG_ 2499780368 KeyID_EngineStartAuth 1;
BA_ "GenSigCycleTime" SG_ 2566211344 TimeLeftToTorqueReduction_OBD_IS 100;
BA_ "GenSigCycleTimeActive" SG_ 2566211344 TimeLeftToTorqueReduction_OBD_IS 100;
BA_ "GenSigStartValue" SG_ 2566211344 TimeLeftToTorqueReduction_OBD_IS 511;
BA_ "GenSigMaxLatency" SG_ 2566211344 TimeLeftToTorqueReduction_OBD_IS 257;
BA_ "Platform_VMCU1_Sig" SG_ 2566211344 TimeLeftToTorqueReduction_OBD_IS 1;
BA_ "SeToolAncestorID_SIGNAL" SG_ 2566211344 TimeLeftToTorqueReduction_OBD_IS "x0000001D043B9BEC";
BA_ "SeToolItemID_SIGNAL" SG_ 2566211344 TimeLeftToTorqueReduction_OBD_IS "x0000001D043B9BEC";
BA_ "SeToolName_SIGNAL" SG_ 2566211344 TimeLeftToTorqueReduction_OBD_IS "TimeLeftToTorqueReduction_OBD";
BA_ "SeToolVersion_SIGNAL" SG_ 2566211344 TimeLeftToTorqueReduction_OBD_IS "1";
BA_ "SystemSignalLongSymbol" SG_ 2566211344 TimeLeftToTorqueReduction_OBD_IS "TimeLeftToTorqueReduction_OBD_ISig_4";
BA_ "GenSigCycleTime" SG_ 2566211344 AdblueTotalConsumed_ISig_4 100;
BA_ "GenSigCycleTimeActive" SG_ 2566211344 AdblueTotalConsumed_ISig_4 100;
BA_ "GenSigStartValue" SG_ 2566211344 AdblueTotalConsumed_ISig_4 4294967295;
BA_ "Platform_VMCU1_Sig" SG_ 2566211344 AdblueTotalConsumed_ISig_4 1;
BA_ "GenSigCycleTime" SG_ 2566211344 MIStatus_ISig_4 100;
BA_ "GenSigCycleTimeActive" SG_ 2566211344 MIStatus_ISig_4 100;
BA_ "GenSigStartValue" SG_ 2566211344 MIStatus_ISig_4 3;
BA_ "GenSigMaxLatency" SG_ 2566211344 MIStatus_ISig_4 257;
BA_ "Platform_VMCU1_Sig" SG_ 2566211344 MIStatus_ISig_4 1;
BA_ "SeToolAncestorID_SIGNAL" SG_ 2566211344 MIStatus_ISig_4 "x0000001D04147511";
BA_ "SeToolItemID_SIGNAL" SG_ 2566211344 MIStatus_ISig_4 "x0000001D0423C9EA";
BA_ "SeToolName_SIGNAL" SG_ 2566211344 MIStatus_ISig_4 "MIStatus";
BA_ "SeToolVersion_SIGNAL" SG_ 2566211344 MIStatus_ISig_4 "2";
BA_ "GenSigCycleTime" SG_ 2566211344 AshLevelHigh 100;
BA_ "GenSigCycleTimeActive" SG_ 2566211344 AshLevelHigh 100;
BA_ "GenSigStartValue" SG_ 2566211344 AshLevelHigh 7;
BA_ "Platform_VMCU1_Sig" SG_ 2566211344 AshLevelHigh 1;
BA_ "GenSigCycleTime" SG_ 2566211344 TorqueReductionStatus_OBD_ISig_4 100;
BA_ "GenSigCycleTimeActive" SG_ 2566211344 TorqueReductionStatus_OBD_ISig_4 100;
BA_ "GenSigStartValue" SG_ 2566211344 TorqueReductionStatus_OBD_ISig_4 7;
BA_ "GenSigMaxLatency" SG_ 2566211344 TorqueReductionStatus_OBD_ISig_4 257;
BA_ "Platform_VMCU1_Sig" SG_ 2566211344 TorqueReductionStatus_OBD_ISig_4 1;
BA_ "SeToolAncestorID_SIGNAL" SG_ 2566211344 TorqueReductionStatus_OBD_ISig_4 "x0000001D043B9BA6";
BA_ "SeToolItemID_SIGNAL" SG_ 2566211344 TorqueReductionStatus_OBD_ISig_4 "x0000001D043B9BA6";
BA_ "SeToolName_SIGNAL" SG_ 2566211344 TorqueReductionStatus_OBD_ISig_4 "TorqueReductionStatus_OBD";
BA_ "SeToolVersion_SIGNAL" SG_ 2566211344 TorqueReductionStatus_OBD_ISig_4 "1";
BA_ "GenSigCycleTime" SG_ 2566211344 SCROperatorInducementSeverity_IS 100;
BA_ "GenSigCycleTimeActive" SG_ 2566211344 SCROperatorInducementSeverity_IS 100;
BA_ "GenSigStartValue" SG_ 2566211344 SCROperatorInducementSeverity_IS 7;
BA_ "Platform_VMCU1_Sig" SG_ 2566211344 SCROperatorInducementSeverity_IS 1;
BA_ "SystemSignalLongSymbol" SG_ 2566211344 SCROperatorInducementSeverity_IS "SCROperatorInducementSeverity_ISig_4";
BA_ "GenSigCycleTime" SG_ 2566211344 SCROperatorInducementReason_ISig 100;
BA_ "GenSigCycleTimeActive" SG_ 2566211344 SCROperatorInducementReason_ISig 100;
BA_ "GenSigStartValue" SG_ 2566211344 SCROperatorInducementReason_ISig 7;
BA_ "Platform_VMCU1_Sig" SG_ 2566211344 SCROperatorInducementReason_ISig 1;
BA_ "SystemSignalLongSymbol" SG_ 2566211344 SCROperatorInducementReason_ISig "SCROperatorInducementReason_ISig_4";
BA_ "GenSigCycleTime" SG_ 2566211344 MIDistinctWarning_ISig_4 100;
BA_ "GenSigCycleTimeActive" SG_ 2566211344 MIDistinctWarning_ISig_4 100;
BA_ "GenSigStartValue" SG_ 2566211344 MIDistinctWarning_ISig_4 3;
BA_ "GenSigMaxLatency" SG_ 2566211344 MIDistinctWarning_ISig_4 257;
BA_ "Platform_VMCU1_Sig" SG_ 2566211344 MIDistinctWarning_ISig_4 1;
BA_ "SeToolAncestorID_SIGNAL" SG_ 2566211344 MIDistinctWarning_ISig_4 "x0000001D04147513";
BA_ "SeToolItemID_SIGNAL" SG_ 2566211344 MIDistinctWarning_ISig_4 "x0000001D0423C9E0";
BA_ "SeToolName_SIGNAL" SG_ 2566211344 MIDistinctWarning_ISig_4 "MIDistinctWarning";
BA_ "SeToolVersion_SIGNAL" SG_ 2566211344 MIDistinctWarning_ISig_4 "2";
BA_ "GenSigCycleTime" SG_ 2566211344 MIStatusExtEMS_ISig_4 100;
BA_ "GenSigCycleTimeActive" SG_ 2566211344 MIStatusExtEMS_ISig_4 100;
BA_ "GenSigStartValue" SG_ 2566211344 MIStatusExtEMS_ISig_4 3;
BA_ "Platform_VMCU1_Sig" SG_ 2566211344 MIStatusExtEMS_ISig_4 1;
BA_ "GenSigCycleTime" SG_ 2566211344 MIDistinctWarningExtEMS_ISig_4 100;
BA_ "GenSigCycleTimeActive" SG_ 2566211344 MIDistinctWarningExtEMS_ISig_4 100;
BA_ "GenSigStartValue" SG_ 2566211344 MIDistinctWarningExtEMS_ISig_4 15;
BA_ "Platform_VMCU1_Sig" SG_ 2566211344 MIDistinctWarningExtEMS_ISig_4 1;
BA_ "GenSigSendType" SG_ 2565955857 EMS_BB2_09S_FCS 7;
BA_ "Platform_VMCU1_Sig" SG_ 2565955857 EMS_BB2_09S_FCS 1;
BA_ "GenSigSendType" SG_ 2565955856 ECU4VIN_stat 1;
BA_ "GenSigMaxLatency" SG_ 2565955856 ECU4VIN_stat 137;
BA_ "Platform_VMCU1_Sig" SG_ 2565955856 ECU4VIN_stat 1;
BA_ "GenSigCycleTime" SG_ 2566356790 EngineRunningTime_ISig_4 100;
BA_ "GenSigCycleTimeActive" SG_ 2566356790 EngineRunningTime_ISig_4 100;
BA_ "GenSigStartValue" SG_ 2566356790 EngineRunningTime_ISig_4 4294967295;
BA_ "Platform_VMCU1_Sig" SG_ 2566356790 EngineRunningTime_ISig_4 1;
BA_ "GenSigCycleTime" SG_ 2566356790 TotPTOFuelHighAccuracy 100;
BA_ "GenSigCycleTimeActive" SG_ 2566356790 TotPTOFuelHighAccuracy 100;
BA_ "GenSigStartValue" SG_ 2566356790 TotPTOFuelHighAccuracy 4294967295;
BA_ "Platform_VMCU1_Sig" SG_ 2566356790 TotPTOFuelHighAccuracy 1;
BA_ "GenSigCycleTime" SG_ 2566356786 OilPrediction_Quality 100;
BA_ "GenSigCycleTimeActive" SG_ 2566356786 OilPrediction_Quality 100;
BA_ "GenSigStartValue" SG_ 2566356786 OilPrediction_Quality 7;
BA_ "Platform_VMCU1_Sig" SG_ 2566356786 OilPrediction_Quality 1;
BA_ "GenSigCycleTime" SG_ 2566356786 TimeLeftToVehSpdReduction_OBD_IS 100;
BA_ "GenSigCycleTimeActive" SG_ 2566356786 TimeLeftToVehSpdReduction_OBD_IS 100;
BA_ "GenSigStartValue" SG_ 2566356786 TimeLeftToVehSpdReduction_OBD_IS 511;
BA_ "Platform_VMCU1_Sig" SG_ 2566356786 TimeLeftToVehSpdReduction_OBD_IS 1;
BA_ "SystemSignalLongSymbol" SG_ 2566356786 TimeLeftToVehSpdReduction_OBD_IS "TimeLeftToVehSpdReduction_OBD_ISig_4";
BA_ "GenSigCycleTime" SG_ 2566356786 OilPrediction_RemainDist 100;
BA_ "GenSigCycleTimeActive" SG_ 2566356786 OilPrediction_RemainDist 100;
BA_ "GenSigStartValue" SG_ 2566356786 OilPrediction_RemainDist 65535;
BA_ "Platform_VMCU1_Sig" SG_ 2566356786 OilPrediction_RemainDist 1;
BA_ "GenSigCycleTime" SG_ 2566356786 TimeToCorrectOilLevel_ISig_4 100;
BA_ "GenSigCycleTimeActive" SG_ 2566356786 TimeToCorrectOilLevel_ISig_4 100;
BA_ "GenSigStartValue" SG_ 2566356786 TimeToCorrectOilLevel_ISig_4 255;
BA_ "Platform_VMCU1_Sig" SG_ 2566356786 TimeToCorrectOilLevel_ISig_4 1;
BA_ "GenSigCycleTime" SG_ 2566356786 OilPrediction_RemainTime 100;
BA_ "GenSigCycleTimeActive" SG_ 2566356786 OilPrediction_RemainTime 100;
BA_ "GenSigStartValue" SG_ 2566356786 OilPrediction_RemainTime 65535;
BA_ "Platform_VMCU1_Sig" SG_ 2566356786 OilPrediction_RemainTime 1;
BA_ "GenSigCycleTime" SG_ 2566356786 OilPrediction_Status 100;
BA_ "GenSigCycleTimeActive" SG_ 2566356786 OilPrediction_Status 100;
BA_ "GenSigStartValue" SG_ 2566356786 OilPrediction_Status 7;
BA_ "Platform_VMCU1_Sig" SG_ 2566356786 OilPrediction_Status 1;
BA_ "GenSigCycleTime" SG_ 2549445904 EngineCoolingFanSpeed_ISig_4 100;
BA_ "GenSigCycleTimeActive" SG_ 2549445904 EngineCoolingFanSpeed_ISig_4 100;
BA_ "GenSigStartValue" SG_ 2549445904 EngineCoolingFanSpeed_ISig_4 65535;
BA_ "Platform_VMCU1_Sig" SG_ 2549445904 EngineCoolingFanSpeed_ISig_4 1;
BA_ "GenSigCycleTime" SG_ 2549445904 DMSDriverFollow 100;
BA_ "GenSigCycleTimeActive" SG_ 2549445904 DMSDriverFollow 100;
BA_ "GenSigStartValue" SG_ 2549445904 DMSDriverFollow 3;
BA_ "GenSigMaxLatency" SG_ 2549445904 DMSDriverFollow 270;
BA_ "Platform_VMCU1_Sig" SG_ 2549445904 DMSDriverFollow 1;
BA_ "GenSigCycleTime" SG_ 2549445904 CoolantPumpEngagementStatus_ISig 100;
BA_ "GenSigCycleTimeActive" SG_ 2549445904 CoolantPumpEngagementStatus_ISig 100;
BA_ "GenSigStartValue" SG_ 2549445904 CoolantPumpEngagementStatus_ISig 255;
BA_ "Platform_VMCU1_Sig" SG_ 2549445904 CoolantPumpEngagementStatus_ISig 1;
BA_ "SystemSignalLongSymbol" SG_ 2549445904 CoolantPumpEngagementStatus_ISig "CoolantPumpEngagementStatus_ISig_4";
BA_ "GenSigCycleTime" SG_ 2549445904 AverageFuelEconomy_ISig_4 100;
BA_ "GenSigCycleTimeActive" SG_ 2549445904 AverageFuelEconomy_ISig_4 100;
BA_ "GenSigMaxLatency" SG_ 2549445904 AverageFuelEconomy_ISig_4 270;
BA_ "Platform_VMCU1_Sig" SG_ 2549445904 AverageFuelEconomy_ISig_4 1;
BA_ "GenSigCycleTime" SG_ 2549445904 EngineGasRate 100;
BA_ "GenSigCycleTimeActive" SG_ 2549445904 EngineGasRate 100;
BA_ "GenSigStartValue" SG_ 2549445904 EngineGasRate 65535;
BA_ "Platform_VMCU1_Sig" SG_ 2549445904 EngineGasRate 1;
BA_ "GenSigCycleTime" SG_ 2549445904 FuelEcoEngStatus 100;
BA_ "GenSigCycleTimeActive" SG_ 2549445904 FuelEcoEngStatus 100;
BA_ "GenSigStartValue" SG_ 2549445904 FuelEcoEngStatus 3;
BA_ "Platform_VMCU1_Sig" SG_ 2549445904 FuelEcoEngStatus 1;
BA_ "GenSigCycleTime" SG_ 2549579536 DrainPrimingStatus_ISig_4 100;
BA_ "GenSigCycleTimeActive" SG_ 2549579536 DrainPrimingStatus_ISig_4 100;
BA_ "GenSigStartValue" SG_ 2549579536 DrainPrimingStatus_ISig_4 7;
BA_ "GenSigMaxLatency" SG_ 2549579536 DrainPrimingStatus_ISig_4 258;
BA_ "Platform_VMCU1_Sig" SG_ 2549579536 DrainPrimingStatus_ISig_4 1;
BA_ "SeToolAncestorID_SIGNAL" SG_ 2549579536 DrainPrimingStatus_ISig_4 "x0000001D041410EE";
BA_ "SeToolItemID_SIGNAL" SG_ 2549579536 DrainPrimingStatus_ISig_4 "x0000001D042EB380";
BA_ "SeToolName_SIGNAL" SG_ 2549579536 DrainPrimingStatus_ISig_4 "DrainPrimingStatus";
BA_ "SeToolVersion_SIGNAL" SG_ 2549579536 DrainPrimingStatus_ISig_4 "2";
BA_ "GenSigCycleTime" SG_ 2549579536 CoolantTempHigh_ISig_4 100;
BA_ "GenSigCycleTimeActive" SG_ 2549579536 CoolantTempHigh_ISig_4 100;
BA_ "GenSigStartValue" SG_ 2549579536 CoolantTempHigh_ISig_4 7;
BA_ "GenSigMaxLatency" SG_ 2549579536 CoolantTempHigh_ISig_4 258;
BA_ "Platform_VMCU1_Sig" SG_ 2549579536 CoolantTempHigh_ISig_4 1;
BA_ "SeToolAncestorID_SIGNAL" SG_ 2549579536 CoolantTempHigh_ISig_4 "x0000001D0412B8A6";
BA_ "SeToolItemID_SIGNAL" SG_ 2549579536 CoolantTempHigh_ISig_4 "x0000001D0412B8A6";
BA_ "SeToolName_SIGNAL" SG_ 2549579536 CoolantTempHigh_ISig_4 "CoolantTempHigh";
BA_ "SeToolVersion_SIGNAL" SG_ 2549579536 CoolantTempHigh_ISig_4 "1";
BA_ "GenSigCycleTime" SG_ 2549579536 CoolantLevelLow_ISig_4 100;
BA_ "GenSigCycleTimeActive" SG_ 2549579536 CoolantLevelLow_ISig_4 100;
BA_ "GenSigStartValue" SG_ 2549579536 CoolantLevelLow_ISig_4 7;
BA_ "GenSigMaxLatency" SG_ 2549579536 CoolantLevelLow_ISig_4 258;
BA_ "Platform_VMCU1_Sig" SG_ 2549579536 CoolantLevelLow_ISig_4 1;
BA_ "SeToolAncestorID_SIGNAL" SG_ 2549579536 CoolantLevelLow_ISig_4 "x0000001D0412B8A4";
BA_ "SeToolItemID_SIGNAL" SG_ 2549579536 CoolantLevelLow_ISig_4 "x0000001D0412B8A4";
BA_ "SeToolName_SIGNAL" SG_ 2549579536 CoolantLevelLow_ISig_4 "CoolantLevelLow";
BA_ "SeToolVersion_SIGNAL" SG_ 2549579536 CoolantLevelLow_ISig_4 "1";
BA_ "GenSigCycleTime" SG_ 2549579536 AutoWheelBrakesStatus 100;
BA_ "GenSigCycleTimeActive" SG_ 2549579536 AutoWheelBrakesStatus 100;
BA_ "GenSigStartValue" SG_ 2549579536 AutoWheelBrakesStatus 7;
BA_ "GenSigCycleTime" SG_ 2549579536 OilPressureLow_ISig_4 100;
BA_ "GenSigCycleTimeActive" SG_ 2549579536 OilPressureLow_ISig_4 100;
BA_ "GenSigStartValue" SG_ 2549579536 OilPressureLow_ISig_4 7;
BA_ "GenSigMaxLatency" SG_ 2549579536 OilPressureLow_ISig_4 513;
BA_ "Platform_VMCU1_Sig" SG_ 2549579536 OilPressureLow_ISig_4 1;
BA_ "SeToolAncestorID_SIGNAL" SG_ 2549579536 OilPressureLow_ISig_4 "x0000001D0412B8B1";
BA_ "SeToolItemID_SIGNAL" SG_ 2549579536 OilPressureLow_ISig_4 "x0000001D0412B8B1";
BA_ "SeToolName_SIGNAL" SG_ 2549579536 OilPressureLow_ISig_4 "OilPressureLow";
BA_ "SeToolVersion_SIGNAL" SG_ 2549579536 OilPressureLow_ISig_4 "1";
BA_ "GenSigCycleTime" SG_ 2549579536 EngineTotalFuelConsumed_ISig_4 100;
BA_ "GenSigCycleTimeActive" SG_ 2549579536 EngineTotalFuelConsumed_ISig_4 100;
BA_ "GenSigStartValue" SG_ 2549579536 EngineTotalFuelConsumed_ISig_4 4294967295;
BA_ "GenSigMaxLatency" SG_ 2549579536 EngineTotalFuelConsumed_ISig_4 258;
BA_ "Platform_VMCU1_Sig" SG_ 2549579536 EngineTotalFuelConsumed_ISig_4 1;
BA_ "SeToolAncestorID_SIGNAL" SG_ 2549579536 EngineTotalFuelConsumed_ISig_4 "x0000001D04172521";
BA_ "SeToolItemID_SIGNAL" SG_ 2549579536 EngineTotalFuelConsumed_ISig_4 "x0000001D04172521";
BA_ "SeToolName_SIGNAL" SG_ 2549579536 EngineTotalFuelConsumed_ISig_4 "EngineTotalFuelConsumed";
BA_ "SeToolVersion_SIGNAL" SG_ 2549579536 EngineTotalFuelConsumed_ISig_4 "1";
BA_ "GenSigCycleTime" SG_ 2549579536 TopGearMode_ISig_4 100;
BA_ "GenSigCycleTimeActive" SG_ 2549579536 TopGearMode_ISig_4 100;
BA_ "GenSigStartValue" SG_ 2549579536 TopGearMode_ISig_4 3;
BA_ "Platform_VMCU1_Sig" SG_ 2549579536 TopGearMode_ISig_4 1;
BA_ "GenSigCycleTime" SG_ 2549579536 OilLevelLow_ISig_4 100;
BA_ "GenSigCycleTimeActive" SG_ 2549579536 OilLevelLow_ISig_4 100;
BA_ "GenSigStartValue" SG_ 2549579536 OilLevelLow_ISig_4 7;
BA_ "GenSigMaxLatency" SG_ 2549579536 OilLevelLow_ISig_4 513;
BA_ "Platform_VMCU1_Sig" SG_ 2549579536 OilLevelLow_ISig_4 1;
BA_ "SeToolAncestorID_SIGNAL" SG_ 2549579536 OilLevelLow_ISig_4 "x0000001D0412B8AA";
BA_ "SeToolItemID_SIGNAL" SG_ 2549579536 OilLevelLow_ISig_4 "x0000001D0412B8AA";
BA_ "SeToolName_SIGNAL" SG_ 2549579536 OilLevelLow_ISig_4 "OilLevelLow";
BA_ "SeToolVersion_SIGNAL" SG_ 2549579536 OilLevelLow_ISig_4 "1";
BA_ "GenSigCycleTime" SG_ 2549579536 BarometricPressure_ISig_4 100;
BA_ "GenSigCycleTimeActive" SG_ 2549579536 BarometricPressure_ISig_4 100;
BA_ "GenSigStartValue" SG_ 2549579536 BarometricPressure_ISig_4 255;
BA_ "GenSigMaxLatency" SG_ 2549579536 BarometricPressure_ISig_4 258;
BA_ "Platform_VMCU1_Sig" SG_ 2549579536 BarometricPressure_ISig_4 1;
BA_ "SeToolAncestorID_SIGNAL" SG_ 2549579536 BarometricPressure_ISig_4 "x0000001D040FEBBD";
BA_ "SeToolItemID_SIGNAL" SG_ 2549579536 BarometricPressure_ISig_4 "x0000001D040FEBBD";
BA_ "SeToolName_SIGNAL" SG_ 2549579536 BarometricPressure_ISig_4 "BarometricPressure";
BA_ "SeToolVersion_SIGNAL" SG_ 2549579536 BarometricPressure_ISig_4 "1";
BA_ "GenSigCycleTime" SG_ 2549579536 InletAirHeaterStatus1_ISig_4 100;
BA_ "GenSigCycleTimeActive" SG_ 2549579536 InletAirHeaterStatus1_ISig_4 100;
BA_ "GenSigStartValue" SG_ 2549579536 InletAirHeaterStatus1_ISig_4 3;
BA_ "GenSigMaxLatency" SG_ 2549579536 InletAirHeaterStatus1_ISig_4 258;
BA_ "Platform_VMCU1_Sig" SG_ 2549579536 InletAirHeaterStatus1_ISig_4 1;
BA_ "SeToolAncestorID_SIGNAL" SG_ 2549579536 InletAirHeaterStatus1_ISig_4 "x0000001D04130F0B";
BA_ "SeToolItemID_SIGNAL" SG_ 2549579536 InletAirHeaterStatus1_ISig_4 "x0000001D043210A4";
BA_ "SeToolName_SIGNAL" SG_ 2549579536 InletAirHeaterStatus1_ISig_4 "InletAirHeaterStatus1";
BA_ "SeToolVersion_SIGNAL" SG_ 2549579536 InletAirHeaterStatus1_ISig_4 "2";
BA_ "GenSigCycleTime" SG_ 2549478160 FuelFilterClogged_ISig_4 100;
BA_ "GenSigCycleTimeActive" SG_ 2549478160 FuelFilterClogged_ISig_4 100;
BA_ "GenSigStartValue" SG_ 2549478160 FuelFilterClogged_ISig_4 7;
BA_ "GenSigMaxLatency" SG_ 2549478160 FuelFilterClogged_ISig_4 257;
BA_ "Platform_VMCU1_Sig" SG_ 2549478160 FuelFilterClogged_ISig_4 1;
BA_ "SeToolAncestorID_SIGNAL" SG_ 2549478160 FuelFilterClogged_ISig_4 "x0000001D04181612";
BA_ "SeToolItemID_SIGNAL" SG_ 2549478160 FuelFilterClogged_ISig_4 "x0000001D04181612";
BA_ "SeToolName_SIGNAL" SG_ 2549478160 FuelFilterClogged_ISig_4 "FuelFilterClogged";
BA_ "SeToolVersion_SIGNAL" SG_ 2549478160 FuelFilterClogged_ISig_4 "1";
BA_ "GenSigCycleTime" SG_ 2549478160 EngineAirInletTemperature 100;
BA_ "GenSigCycleTimeActive" SG_ 2549478160 EngineAirInletTemperature 100;
BA_ "GenSigStartValue" SG_ 2549478160 EngineAirInletTemperature 255;
BA_ "GenSigMaxLatency" SG_ 2549478160 EngineAirInletTemperature 257;
BA_ "Platform_VMCU1_Sig" SG_ 2549478160 EngineAirInletTemperature 1;
BA_ "SeToolAncestorID_SIGNAL" SG_ 2549478160 EngineAirInletTemperature "x0000001D041943AE";
BA_ "SeToolItemID_SIGNAL" SG_ 2549478160 EngineAirInletTemperature "x0000001D0421DC80";
BA_ "SeToolName_SIGNAL" SG_ 2549478160 EngineAirInletTemperature "EngineAirInletTemperature";
BA_ "SeToolVersion_SIGNAL" SG_ 2549478160 EngineAirInletTemperature "2";
BA_ "GenSigCycleTime" SG_ 2549478160 StarterMotorRecoveryTime_ISig_4 100;
BA_ "GenSigCycleTimeActive" SG_ 2549478160 StarterMotorRecoveryTime_ISig_4 100;
BA_ "GenSigStartValue" SG_ 2549478160 StarterMotorRecoveryTime_ISig_4 65535;
BA_ "GenSigMaxLatency" SG_ 2549478160 StarterMotorRecoveryTime_ISig_4 257;
BA_ "Platform_VMCU1_Sig" SG_ 2549478160 StarterMotorRecoveryTime_ISig_4 1;
BA_ "SeToolAncestorID_SIGNAL" SG_ 2549478160 StarterMotorRecoveryTime_ISig_4 "x0000001D0421E90A";
BA_ "SeToolItemID_SIGNAL" SG_ 2549478160 StarterMotorRecoveryTime_ISig_4 "x0000001D0421E90A";
BA_ "SeToolName_SIGNAL" SG_ 2549478160 StarterMotorRecoveryTime_ISig_4 "StarterMotorRecoveryTime";
BA_ "SeToolVersion_SIGNAL" SG_ 2549478160 StarterMotorRecoveryTime_ISig_4 "1";
BA_ "GenSigCycleTime" SG_ 2549478160 AirFilterPressureDrop 100;
BA_ "GenSigCycleTimeActive" SG_ 2549478160 AirFilterPressureDrop 100;
BA_ "GenSigStartValue" SG_ 2549478160 AirFilterPressureDrop 7;
BA_ "Platform_VMCU1_Sig" SG_ 2549478160 AirFilterPressureDrop 1;
BA_ "GenSigCycleTime" SG_ 2549478160 AppliedVehicleSpeedLimit 100;
BA_ "GenSigCycleTimeActive" SG_ 2549478160 AppliedVehicleSpeedLimit 100;
BA_ "GenSigStartValue" SG_ 2549478160 AppliedVehicleSpeedLimit 65535;
BA_ "Platform_VMCU1_Sig" SG_ 2549478160 AppliedVehicleSpeedLimit 1;
BA_ "GenSigCycleTime" SG_ 2549478160 EngineProtDerateStat 100;
BA_ "GenSigCycleTimeActive" SG_ 2549478160 EngineProtDerateStat 100;
BA_ "GenSigStartValue" SG_ 2549478160 EngineProtDerateStat 3;
BA_ "Platform_VMCU1_Sig" SG_ 2549478160 EngineProtDerateStat 1;
BA_ "GenSigCycleTime" SG_ 2549478160 ClutchOverloadStatusMan 100;
BA_ "GenSigCycleTimeActive" SG_ 2549478160 ClutchOverloadStatusMan 100;
BA_ "GenSigStartValue" SG_ 2549478160 ClutchOverloadStatusMan 3;
BA_ "Platform_VMCU1_Sig" SG_ 2549478160 ClutchOverloadStatusMan 1;
BA_ "GenSigCycleTime" SG_ 2549478160 CoolantTempGaugeAdjustment_ISig_ 100;
BA_ "GenSigCycleTimeActive" SG_ 2549478160 CoolantTempGaugeAdjustment_ISig_ 100;
BA_ "GenSigStartValue" SG_ 2549478160 CoolantTempGaugeAdjustment_ISig_ 255;
BA_ "Platform_VMCU1_Sig" SG_ 2549478160 CoolantTempGaugeAdjustment_ISig_ 1;
BA_ "SystemSignalLongSymbol" SG_ 2549478160 CoolantTempGaugeAdjustment_ISig_ "CoolantTempGaugeAdjustment_ISig_4";
BA_ "GenSigCycleTime" SG_ 2549478160 EngineFanOverspeed 100;
BA_ "GenSigCycleTimeActive" SG_ 2549478160 EngineFanOverspeed 100;
BA_ "GenSigStartValue" SG_ 2549478160 EngineFanOverspeed 3;
BA_ "Platform_VMCU1_Sig" SG_ 2549478160 EngineFanOverspeed 1;
BA_ "GenSigCycleTime" SG_ 2466232336 DPF_LimitedSpeedDuetoInhibit_ISi 100;
BA_ "GenSigCycleTimeActive" SG_ 2466232336 DPF_LimitedSpeedDuetoInhibit_ISi 100;
BA_ "GenSigStartValue" SG_ 2466232336 DPF_LimitedSpeedDuetoInhibit_ISi 7;
BA_ "Platform_VMCU1_Sig" SG_ 2466232336 DPF_LimitedSpeedDuetoInhibit_ISi 1;
BA_ "SystemSignalLongSymbol" SG_ 2466232336 DPF_LimitedSpeedDuetoInhibit_ISi "DPF_LimitedSpeedDuetoInhibit_ISig_4";
BA_ "GenSigCycleTime" SG_ 2466232336 DMSRecommendedGear 100;
BA_ "GenSigCycleTimeActive" SG_ 2466232336 DMSRecommendedGear 100;
BA_ "GenSigStartValue" SG_ 2466232336 DMSRecommendedGear 255;
BA_ "Platform_VMCU1_Sig" SG_ 2466232336 DMSRecommendedGear 1;
BA_ "GenSigCycleTime" SG_ 2466232336 XARSystemState 100;
BA_ "GenSigCycleTimeActive" SG_ 2466232336 XARSystemState 100;
BA_ "GenSigStartValue" SG_ 2466232336 XARSystemState 3;
BA_ "GenSigMaxLatency" SG_ 2466232336 XARSystemState 58;
BA_ "Platform_VMCU1_Sig" SG_ 2466232336 XARSystemState 1;
BA_ "SeToolAncestorID_SIGNAL" SG_ 2466232336 XARSystemState "x0000001D0425407E";
BA_ "SeToolItemID_SIGNAL" SG_ 2466232336 XARSystemState "x0000001D0425407E";
BA_ "SeToolName_SIGNAL" SG_ 2466232336 XARSystemState "XARSystemState";
BA_ "SeToolVersion_SIGNAL" SG_ 2466232336 XARSystemState "1";
BA_ "GenSigCycleTime" SG_ 2466232336 XARActiveControlMode 100;
BA_ "GenSigCycleTimeActive" SG_ 2466232336 XARActiveControlMode 100;
BA_ "GenSigStartValue" SG_ 2466232336 XARActiveControlMode 7;
BA_ "GenSigMaxLatency" SG_ 2466232336 XARActiveControlMode 58;
BA_ "Platform_VMCU1_Sig" SG_ 2466232336 XARActiveControlMode 1;
BA_ "SeToolAncestorID_SIGNAL" SG_ 2466232336 XARActiveControlMode "x0000001D04254078";
BA_ "SeToolItemID_SIGNAL" SG_ 2466232336 XARActiveControlMode "x0000001D043C593D";
BA_ "SeToolName_SIGNAL" SG_ 2466232336 XARActiveControlMode "XARActiveControlMode";
BA_ "SeToolVersion_SIGNAL" SG_ 2466232336 XARActiveControlMode "2";
BA_ "GenSigCycleTime" SG_ 2466232336 CCBSetSpeedApplied 100;
BA_ "GenSigCycleTimeActive" SG_ 2466232336 CCBSetSpeedApplied 100;
BA_ "GenSigStartValue" SG_ 2466232336 CCBSetSpeedApplied 255;
BA_ "Platform_VMCU1_Sig" SG_ 2466232336 CCBSetSpeedApplied 1;
BA_REL_ "GenSigFirstTimeoutTime" BU_SG_REL_ CIOM SG_ 2483002322 AudioSourceBtStreamAvailable_ISi 3000;
BA_REL_ "GenSigTimeoutTime" BU_SG_REL_ CIOM SG_ 2483002322 AudioSourceBtStreamAvailable_ISi 360;
BA_REL_ "GenSigFirstTimeoutTime" BU_SG_REL_ VMCU SG_ 2483002322 MainBeam_StalkStatus_4 3000;
BA_REL_ "GenSigTimeoutTime" BU_SG_REL_ VMCU SG_ 2483002322 MainBeam_StalkStatus_4 360;
BA_REL_ "GenSigFirstTimeoutTime" BU_SG_REL_ CIOM SG_ 2483002322 AudioSourceCdAvailable_ISig_4 3000;
BA_REL_ "GenSigTimeoutTime" BU_SG_REL_ CIOM SG_ 2483002322 AudioSourceCdAvailable_ISig_4 360;
BA_REL_ "GenSigFirstTimeoutTime" BU_SG_REL_ VMCU SG_ 2483002322 LightMode_SwitchStatus 3000;
BA_REL_ "GenSigTimeoutTime" BU_SG_REL_ VMCU SG_ 2483002322 LightMode_SwitchStatus 360;
BA_REL_ "GenSigFirstTimeoutTime" BU_SG_REL_ CIOM SG_ 2483002322 PhoneButtonIndication_cmd 3000;
BA_REL_ "GenSigTimeoutTime" BU_SG_REL_ CIOM SG_ 2483002322 PhoneButtonIndication_cmd 360;
BA_REL_ "GenSigFirstTimeoutTime" BU_SG_REL_ CIOM SG_ 2483002322 AudioVolumeIndicationCmd_ISig_4 3000;
BA_REL_ "GenSigTimeoutTime" BU_SG_REL_ CIOM SG_ 2483002322 AudioVolumeIndicationCmd_ISig_4 360;
BA_REL_ "GenSigFirstTimeoutTime" BU_SG_REL_ CIOM SG_ 2483002322 AudioSourceIpodAvailable_ISig_4 3000;
BA_REL_ "GenSigTimeoutTime" BU_SG_REL_ CIOM SG_ 2483002322 AudioSourceIpodAvailable_ISig_4 360;
BA_REL_ "GenSigFirstTimeoutTime" BU_SG_REL_ CIOM SG_ 2483002322 AudioSystemStatus_ISig_4 3000;
BA_REL_ "GenSigTimeoutTime" BU_SG_REL_ CIOM SG_ 2483002322 AudioSystemStatus_ISig_4 360;
BA_REL_ "GenSigFirstTimeoutTime" BU_SG_REL_ VMCU SG_ 2483002322 WiperAdjustStatus_4 3000;
BA_REL_ "GenSigTimeoutTime" BU_SG_REL_ VMCU SG_ 2483002322 WiperAdjustStatus_4 360;
BA_REL_ "GenSigFirstTimeoutTime" BU_SG_REL_ CIOM SG_ 2483002322 AudioSourceUsbAvailable_ISig_4 3000;
BA_REL_ "GenSigTimeoutTime" BU_SG_REL_ CIOM SG_ 2483002322 AudioSourceUsbAvailable_ISig_4 360;
BA_REL_ "GenSigFirstTimeoutTime" BU_SG_REL_ CIOM SG_ 2483002322 BTStatus 3000;
BA_REL_ "GenSigTimeoutTime" BU_SG_REL_ CIOM SG_ 2483002322 BTStatus 360;
BA_REL_ "GenSigFirstTimeoutTime" BU_SG_REL_ CIOM SG_ 2483002322 AudioSourceStatus_ISig_4 3000;
BA_REL_ "GenSigTimeoutTime" BU_SG_REL_ CIOM SG_ 2483002322 AudioSourceStatus_ISig_4 360;
BA_REL_ "GenSigFirstTimeoutTime" BU_SG_REL_ VMCU SG_ 2483002322 Washing_Status_4 3000;
BA_REL_ "GenSigTimeoutTime" BU_SG_REL_ VMCU SG_ 2483002322 Washing_Status_4 360;
BA_REL_ "GenSigFirstTimeoutTime" BU_SG_REL_ VMCU SG_ 2483002322 WiperStalkStat_4 3000;
BA_REL_ "GenSigTimeoutTime" BU_SG_REL_ VMCU SG_ 2483002322 WiperStalkStat_4 360;
BA_REL_ "GenSigFirstTimeoutTime" BU_SG_REL_ CIOM SG_ 2483002322 AudioSourceStatus2_ISig_4 3000;
BA_REL_ "GenSigTimeoutTime" BU_SG_REL_ CIOM SG_ 2483002322 AudioSourceStatus2_ISig_4 360;
BA_REL_ "GenSigFirstTimeoutTime" BU_SG_REL_ CIOM SG_ 2483002322 BrakeBlending_DeviceIndication 3000;
BA_REL_ "GenSigTimeoutTime" BU_SG_REL_ CIOM SG_ 2483002322 BrakeBlending_DeviceIndication 360;
BA_REL_ "GenSigFirstTimeoutTime" BU_SG_REL_ CIOM SG_ 2483002322 PresetIndicationCmd_ISig_4 3000;
BA_REL_ "GenSigTimeoutTime" BU_SG_REL_ CIOM SG_ 2483002322 PresetIndicationCmd_ISig_4 360;
BA_REL_ "GenSigFirstTimeoutTime" BU_SG_REL_ CIOM SG_ 2483002322 BunkBacklightCmd_ISig_4 3000;
BA_REL_ "GenSigTimeoutTime" BU_SG_REL_ CIOM SG_ 2483002322 BunkBacklightCmd_ISig_4 360;
BA_REL_ "GenSigFirstTimeoutTime" BU_SG_REL_ CIOM SG_ 2483002322 ABSInhibit_DeviceIndication 3000;
BA_REL_ "GenSigTimeoutTime" BU_SG_REL_ CIOM SG_ 2483002322 ABSInhibit_DeviceIndication 360;
BA_REL_ "GenSigFirstTimeoutTime" BU_SG_REL_ CIOM SG_ 2483002322 DayOfWeek_stat_ISig_4 3000;
BA_REL_ "GenSigTimeoutTime" BU_SG_REL_ CIOM SG_ 2483002322 DayOfWeek_stat_ISig_4 360;
BA_REL_ "GenSigFirstTimeoutTime" BU_SG_REL_ CIOM SG_ 2549426814 MinutesLocal_ISig_4 4800;
BA_REL_ "GenSigTimeoutTime" BU_SG_REL_ CIOM SG_ 2549426814 MinutesLocal_ISig_4 1200;
BA_REL_ "GenSigFirstTimeoutTime" BU_SG_REL_ CIOM SG_ 2549426814 DayLocal_ISig_4 4800;
BA_REL_ "GenSigTimeoutTime" BU_SG_REL_ CIOM SG_ 2549426814 DayLocal_ISig_4 1200;
BA_REL_ "GenSigFirstTimeoutTime" BU_SG_REL_ CIOM SG_ 2549426814 MonthLocal_ISig_4 4800;
BA_REL_ "GenSigTimeoutTime" BU_SG_REL_ CIOM SG_ 2549426814 MonthLocal_ISig_4 1200;
BA_REL_ "GenSigFirstTimeoutTime" BU_SG_REL_ BBM SG_ 2549426814 CabLightIntensity_stat_ISig_4 4800;
BA_REL_ "GenSigTimeoutTime" BU_SG_REL_ BBM SG_ 2549426814 CabLightIntensity_stat_ISig_4 1200;
BA_REL_ "GenSigFirstTimeoutTime" BU_SG_REL_ DACU SG_ 2549426814 CabLightIntensity_stat_ISig_4 4800;
BA_REL_ "GenSigTimeoutTime" BU_SG_REL_ DACU SG_ 2549426814 CabLightIntensity_stat_ISig_4 1200;
BA_REL_ "GenSigFirstTimeoutTime" BU_SG_REL_ CIOM SG_ 2549426814 SecondsLocal_ISig_4 4800;
BA_REL_ "GenSigTimeoutTime" BU_SG_REL_ CIOM SG_ 2549426814 SecondsLocal_ISig_4 1200;
BA_REL_ "GenSigFirstTimeoutTime" BU_SG_REL_ CIOM SG_ 2549426814 YearLocal_ISig_4 4800;
BA_REL_ "GenSigTimeoutTime" BU_SG_REL_ CIOM SG_ 2549426814 YearLocal_ISig_4 1200;
BA_REL_ "GenSigFirstTimeoutTime" BU_SG_REL_ CIOM SG_ 2549426814 HoursLocal_ISig_4 4800;
BA_REL_ "GenSigTimeoutTime" BU_SG_REL_ CIOM SG_ 2549426814 HoursLocal_ISig_4 1200;
BA_REL_ "GenSigFirstTimeoutTime" BU_SG_REL_ VMCU SG_ 2466245055 CCBOverspeedRequest 3000;
BA_REL_ "GenSigTimeoutTime" BU_SG_REL_ VMCU SG_ 2466245055 CCBOverspeedRequest 210;
BA_REL_ "GenSigFirstTimeoutTime" BU_SG_REL_ VMCU SG_ 2466245055 ASLDriverRequest 3000;
BA_REL_ "GenSigTimeoutTime" BU_SG_REL_ VMCU SG_ 2466245055 ASLDriverRequest 210;
BA_REL_ "GenSigFirstTimeoutTime" BU_SG_REL_ VMCU SG_ 2466245055 ASLEnableRequest 3000;
BA_REL_ "GenSigTimeoutTime" BU_SG_REL_ VMCU SG_ 2466245055 ASLEnableRequest 210;
BA_REL_ "GenSigFirstTimeoutTime" BU_SG_REL_ CIOM SG_ 2466245055 CCEnableRequest_ISig_4 3000;
BA_REL_ "GenSigTimeoutTime" BU_SG_REL_ CIOM SG_ 2466245055 CCEnableRequest_ISig_4 210;
BA_REL_ "GenSigFirstTimeoutTime" BU_SG_REL_ VMCU SG_ 2466245055 CCEnableRequest_ISig_4 3000;
BA_REL_ "GenSigTimeoutTime" BU_SG_REL_ VMCU SG_ 2466245055 CCEnableRequest_ISig_4 210;
BA_REL_ "GenSigFirstTimeoutTime" BU_SG_REL_ BBM SG_ 2466245055 CCEnableRequest_ISig_4 3000;
BA_REL_ "GenSigTimeoutTime" BU_SG_REL_ BBM SG_ 2466245055 CCEnableRequest_ISig_4 210;
BA_REL_ "GenSigFirstTimeoutTime" BU_SG_REL_ VMCU SG_ 2466245055 CCRequestedPresetSpeed 3000;
BA_REL_ "GenSigTimeoutTime" BU_SG_REL_ VMCU SG_ 2466245055 CCRequestedPresetSpeed 210;
BA_REL_ "GenSigFirstTimeoutTime" BU_SG_REL_ VMCU SG_ 2466245055 CCDriverRequest 3000;
BA_REL_ "GenSigTimeoutTime" BU_SG_REL_ VMCU SG_ 2466245055 CCDriverRequest 210;
BA_REL_ "GenSigFirstTimeoutTime" BU_SG_REL_ BBM SG_ 2466245055 CCDriverRequest 3000;
BA_REL_ "GenSigTimeoutTime" BU_SG_REL_ BBM SG_ 2466245055 CCDriverRequest 210;
BA_REL_ "GenSigFirstTimeoutTime" BU_SG_REL_ VMCU SG_ 2466245055 RainsensorActivateRqst 3000;
BA_REL_ "GenSigTimeoutTime" BU_SG_REL_ VMCU SG_ 2466245055 RainsensorActivateRqst 210;
BA_REL_ "GenSigFirstTimeoutTime" BU_SG_REL_ VMCU SG_ 2466245055 ASLRequestedPresetSpeed 3000;
BA_REL_ "GenSigTimeoutTime" BU_SG_REL_ VMCU SG_ 2466245055 ASLRequestedPresetSpeed 210;
BA_REL_ "GenSigFirstTimeoutTime" BU_SG_REL_ VMCU SG_ 2365538239 Rainsensor_ButtonStatus 3000;
BA_REL_ "GenSigTimeoutTime" BU_SG_REL_ VMCU SG_ 2365538239 Rainsensor_ButtonStatus 90;
BA_REL_ "GenSigFirstTimeoutTime" BU_SG_REL_ CIOM SG_ 2365538239 Traction_DualDeviceIndication 3000;
BA_REL_ "GenSigTimeoutTime" BU_SG_REL_ CIOM SG_ 2365538239 Traction_DualDeviceIndication 90;
BA_REL_ "GenSigFirstTimeoutTime" BU_SG_REL_ VMCU SG_ 2365538239 WiperStalkStat_1 3000;
BA_REL_ "GenSigTimeoutTime" BU_SG_REL_ VMCU SG_ 2365538239 WiperStalkStat_1 90;
BA_REL_ "GenSigFirstTimeoutTime" BU_SG_REL_ TECU SG_ 2365538239 RequestForHighestGearRatio 3000;
BA_REL_ "GenSigTimeoutTime" BU_SG_REL_ TECU SG_ 2365538239 RequestForHighestGearRatio 90;
BA_REL_ "GenSigFirstTimeoutTime" BU_SG_REL_ TECU SG_ 2365538239 RequestedUpshiftDownshiftSteps 3000;
BA_REL_ "GenSigTimeoutTime" BU_SG_REL_ TECU SG_ 2365538239 RequestedUpshiftDownshiftSteps 90;
BA_REL_ "GenSigFirstTimeoutTime" BU_SG_REL_ VMCU SG_ 2365538239 WiperAdjustStatus_1 3000;
BA_REL_ "GenSigTimeoutTime" BU_SG_REL_ VMCU SG_ 2365538239 WiperAdjustStatus_1 90;
BA_REL_ "GenSigFirstTimeoutTime" BU_SG_REL_ TECU SG_ 2365538239 UpShiftRequest 3000;
BA_REL_ "GenSigTimeoutTime" BU_SG_REL_ TECU SG_ 2365538239 UpShiftRequest 90;
BA_REL_ "GenSigFirstTimeoutTime" BU_SG_REL_ VMCU SG_ 2365538239 MainBeam_StalkStatus_1 3000;
BA_REL_ "GenSigTimeoutTime" BU_SG_REL_ VMCU SG_ 2365538239 MainBeam_StalkStatus_1 90;
BA_REL_ "GenSigFirstTimeoutTime" BU_SG_REL_ VMCU SG_ 2365538239 DirInd_StalkStatus_1 3000;
BA_REL_ "GenSigTimeoutTime" BU_SG_REL_ VMCU SG_ 2365538239 DirInd_StalkStatus_1 90;
BA_REL_ "GenSigFirstTimeoutTime" BU_SG_REL_ TECU SG_ 2365538239 LimpHomeSwitch_stat 3000;
BA_REL_ "GenSigTimeoutTime" BU_SG_REL_ TECU SG_ 2365538239 LimpHomeSwitch_stat 90;
BA_REL_ "GenSigFirstTimeoutTime" BU_SG_REL_ VMCU SG_ 2365538239 Washing_Status_2 3000;
BA_REL_ "GenSigTimeoutTime" BU_SG_REL_ VMCU SG_ 2365538239 Washing_Status_2 90;
BA_REL_ "GenSigFirstTimeoutTime" BU_SG_REL_ TECU SG_ 2365538239 EconomyPowerSwitch_stat 3000;
BA_REL_ "GenSigTimeoutTime" BU_SG_REL_ TECU SG_ 2365538239 EconomyPowerSwitch_stat 90;
BA_REL_ "GenSigFirstTimeoutTime" BU_SG_REL_ VMCU SG_ 2365538239 GearLeverPosition_ISig_4 3000;
BA_REL_ "GenSigTimeoutTime" BU_SG_REL_ VMCU SG_ 2365538239 GearLeverPosition_ISig_4 500;
BA_REL_ "GenSigFirstTimeoutTime" BU_SG_REL_ TECU SG_ 2365538239 GearLeverPosition_ISig_4 3000;
BA_REL_ "GenSigTimeoutTime" BU_SG_REL_ TECU SG_ 2365538239 GearLeverPosition_ISig_4 500;
BA_REL_ "GenSigFirstTimeoutTime" BU_SG_REL_ BBM SG_ 2365538239 GearLeverPosition_ISig_4 3000;
BA_REL_ "GenSigTimeoutTime" BU_SG_REL_ BBM SG_ 2365538239 GearLeverPosition_ISig_4 500;
BA_REL_ "GenSigFirstTimeoutTime" BU_SG_REL_ TECU SG_ 2365538239 DownShiftRequest 3000;
BA_REL_ "GenSigTimeoutTime" BU_SG_REL_ TECU SG_ 2365538239 DownShiftRequest 90;
BA_REL_ "GenSigFirstTimeoutTime" BU_SG_REL_ VMCU SG_ 2365538239 MainBeam_StalkStatus_2 3000;
BA_REL_ "GenSigTimeoutTime" BU_SG_REL_ VMCU SG_ 2365538239 MainBeam_StalkStatus_2 90;
BA_REL_ "GenSigFirstTimeoutTime" BU_SG_REL_ VMCU SG_ 2365538239 DirInd_StalkStatus_2 3000;
BA_REL_ "GenSigTimeoutTime" BU_SG_REL_ VMCU SG_ 2365538239 DirInd_StalkStatus_2 90;
BA_REL_ "GenSigFirstTimeoutTime" BU_SG_REL_ VMCU SG_ 2365538239 RetarderStalkPosition_1 3000;
BA_REL_ "GenSigTimeoutTime" BU_SG_REL_ VMCU SG_ 2365538239 RetarderStalkPosition_1 90;
BA_REL_ "GenSigFirstTimeoutTime" BU_SG_REL_ VMCU SG_ 2365538239 RetarderStalkPosition_2 3000;
BA_REL_ "GenSigTimeoutTime" BU_SG_REL_ VMCU SG_ 2365538239 RetarderStalkPosition_2 90;
BA_REL_ "GenSigFirstTimeoutTime" BU_SG_REL_ TECU SG_ 2365538239 EcoRollEnableRequest_ISig_4 3000;
BA_REL_ "GenSigTimeoutTime" BU_SG_REL_ TECU SG_ 2365538239 EcoRollEnableRequest_ISig_4 90;
BA_REL_ "GenSigFirstTimeoutTime" BU_SG_REL_ VMCU SG_ 2365538239 Washing_Status_1 3000;
BA_REL_ "GenSigTimeoutTime" BU_SG_REL_ VMCU SG_ 2365538239 Washing_Status_1 90;
BA_REL_ "GenSigFirstTimeoutTime" BU_SG_REL_ EMS SG_ 2365538239 SelectedEcoCruiseLevel_ISig_4 12000;
BA_REL_ "GenSigTimeoutTime" BU_SG_REL_ EMS SG_ 2365538239 SelectedEcoCruiseLevel_ISig_4 3000;
BA_REL_ "GenSigFirstTimeoutTime" BU_SG_REL_ DACU SG_ 2365538239 SelectedEcoCruiseLevel_ISig_4 3000;
BA_REL_ "GenSigTimeoutTime" BU_SG_REL_ DACU SG_ 2365538239 SelectedEcoCruiseLevel_ISig_4 90;
BA_REL_ "GenSigFirstTimeoutTime" BU_SG_REL_ TECU SG_ 2365538239 SelectedEcoCruiseLevel_ISig_4 3000;
BA_REL_ "GenSigTimeoutTime" BU_SG_REL_ TECU SG_ 2365538239 SelectedEcoCruiseLevel_ISig_4 90;
BA_REL_ "GenSigFirstTimeoutTime" BU_SG_REL_ VMCU SG_ 2365538239 SelectedEcoCruiseLevel_ISig_4 3000;
BA_REL_ "GenSigTimeoutTime" BU_SG_REL_ VMCU SG_ 2365538239 SelectedEcoCruiseLevel_ISig_4 90;
BA_REL_ "GenSigFirstTimeoutTime" BU_SG_REL_ VMCU SG_ 2365538239 WiperStalkStat_2 3000;
BA_REL_ "GenSigTimeoutTime" BU_SG_REL_ VMCU SG_ 2365538239 WiperStalkStat_2 90;
BA_REL_ "GenSigFirstTimeoutTime" BU_SG_REL_ VMCU SG_ 2432634208 IdleAdjustDeactivationRequest 3000;
BA_REL_ "GenSigTimeoutTime" BU_SG_REL_ VMCU SG_ 2432634208 IdleAdjustDeactivationRequest 150;
BA_REL_ "GenSigFirstTimeoutTime" BU_SG_REL_ CIOM SG_ 2432634208 ACMode_Selection_ISig_4 3000;
BA_REL_ "GenSigTimeoutTime" BU_SG_REL_ CIOM SG_ 2432634208 ACMode_Selection_ISig_4 150;
BA_REL_ "GenSigFirstTimeoutTime" BU_SG_REL_ VMCU SG_ 2432634208 TripmeterReset_rqst_ISig_4 3000;
BA_REL_ "GenSigTimeoutTime" BU_SG_REL_ VMCU SG_ 2432634208 TripmeterReset_rqst_ISig_4 150;
BA_REL_ "GenSigFirstTimeoutTime" BU_SG_REL_ EMS SG_ 2432634208 WaterInFuelDrainRequest 3000;
BA_REL_ "GenSigTimeoutTime" BU_SG_REL_ EMS SG_ 2432634208 WaterInFuelDrainRequest 150;
BA_REL_ "GenSigFirstTimeoutTime" BU_SG_REL_ VMCU SG_ 2432634208 FuncIndIlluminationLevel_ISig_4 3000;
BA_REL_ "GenSigTimeoutTime" BU_SG_REL_ VMCU SG_ 2432634208 FuncIndIlluminationLevel_ISig_4 150;
BA_REL_ "GenSigFirstTimeoutTime" BU_SG_REL_ CIOM SG_ 2432634208 FuncIndIlluminationLevel_ISig_4 3000;
BA_REL_ "GenSigTimeoutTime" BU_SG_REL_ CIOM SG_ 2432634208 FuncIndIlluminationLevel_ISig_4 150;
BA_REL_ "GenSigFirstTimeoutTime" BU_SG_REL_ VMCU SG_ 2432634208 IdleAdjustActivationRequest 3000;
BA_REL_ "GenSigTimeoutTime" BU_SG_REL_ VMCU SG_ 2432634208 IdleAdjustActivationRequest 150;
BA_REL_ "GenSigFirstTimeoutTime" BU_SG_REL_ CIOM SG_ 2432634208 AutoDefogmode_Selection_ISig_4 3000;
BA_REL_ "GenSigTimeoutTime" BU_SG_REL_ CIOM SG_ 2432634208 AutoDefogmode_Selection_ISig_4 150;
BA_REL_ "GenSigFirstTimeoutTime" BU_SG_REL_ DACU SG_ 2432634208 ResumeRequestForACC_ISig_4 3000;
BA_REL_ "GenSigTimeoutTime" BU_SG_REL_ DACU SG_ 2432634208 ResumeRequestForACC_ISig_4 150;
BA_REL_ "GenSigFirstTimeoutTime" BU_SG_REL_ CIOM SG_ 2432634208 AudioMuteStat_ISig_4 3000;
BA_REL_ "GenSigTimeoutTime" BU_SG_REL_ CIOM SG_ 2432634208 AudioMuteStat_ISig_4 150;
BA_REL_ "GenSigFirstTimeoutTime" BU_SG_REL_ VMCU SG_ 2432634208 IdleAdjustTrimGuiEventCmd 3000;
BA_REL_ "GenSigTimeoutTime" BU_SG_REL_ VMCU SG_ 2432634208 IdleAdjustTrimGuiEventCmd 150;
BA_REL_ "GenSigFirstTimeoutTime" BU_SG_REL_ VMCU SG_ 2432634208 IdleAdjustStoreRequest 3000;
BA_REL_ "GenSigTimeoutTime" BU_SG_REL_ VMCU SG_ 2432634208 IdleAdjustStoreRequest 150;
BA_REL_ "GenSigFirstTimeoutTime" BU_SG_REL_ VMCU SG_ 2432634208 SWSpeedControlAdjustMode 3000;
BA_REL_ "GenSigTimeoutTime" BU_SG_REL_ VMCU SG_ 2432634208 SWSpeedControlAdjustMode 150;
BA_REL_ "GenSigFirstTimeoutTime" BU_SG_REL_ CIOM SG_ 2432634208 SWSpeedControlAdjustMode 3000;
BA_REL_ "GenSigTimeoutTime" BU_SG_REL_ CIOM SG_ 2432634208 SWSpeedControlAdjustMode 150;
BA_REL_ "GenSigFirstTimeoutTime" BU_SG_REL_ DACU SG_ 2432634208 ACCTimeGapRqst_ISig_4 3000;
BA_REL_ "GenSigTimeoutTime" BU_SG_REL_ DACU SG_ 2432634208 ACCTimeGapRqst_ISig_4 150;
BA_REL_ "GenSigFirstTimeoutTime" BU_SG_REL_ CIOM SG_ 2432634208 AQSMode_Selection_ISig_4 3000;
BA_REL_ "GenSigTimeoutTime" BU_SG_REL_ CIOM SG_ 2432634208 AQSMode_Selection_ISig_4 150;
BA_REL_ "GenSigFirstTimeoutTime" BU_SG_REL_ VMCU SG_ 2432634208 ACCEnableRqst_ISig_4 3000;
BA_REL_ "GenSigTimeoutTime" BU_SG_REL_ VMCU SG_ 2432634208 ACCEnableRqst_ISig_4 150;
BA_REL_ "GenSigFirstTimeoutTime" BU_SG_REL_ DACU SG_ 2432634208 ACCEnableRqst_ISig_4 3000;
BA_REL_ "GenSigTimeoutTime" BU_SG_REL_ DACU SG_ 2432634208 ACCEnableRqst_ISig_4 150;
BA_REL_ "GenSigFirstTimeoutTime" BU_SG_REL_ CIOM SG_ 2432634208 ACCEnableRqst_ISig_4 3000;
BA_REL_ "GenSigTimeoutTime" BU_SG_REL_ CIOM SG_ 2432634208 ACCEnableRqst_ISig_4 150;
BA_REL_ "GenSigFirstTimeoutTime" BU_SG_REL_ VMCU SG_ 2432634208 StopAlert_cmd_ISig_4 3000;
BA_REL_ "GenSigTimeoutTime" BU_SG_REL_ VMCU SG_ 2432634208 StopAlert_cmd_ISig_4 150;
BA_REL_ "GenSigFirstTimeoutTime" BU_SG_REL_ CIOM SG_ 2432634208 BacklightCmd_ISig_4 3000;
BA_REL_ "GenSigTimeoutTime" BU_SG_REL_ CIOM SG_ 2432634208 BacklightCmd_ISig_4 150;
BA_REL_ "GenSigFirstTimeoutTime" BU_SG_REL_ VMCU SG_ 2432634208 BacklightCmd_ISig_4 3000;
BA_REL_ "GenSigTimeoutTime" BU_SG_REL_ VMCU SG_ 2432634208 BacklightCmd_ISig_4 150;
BA_REL_ "GenSigFirstTimeoutTime" BU_SG_REL_ CIOM SG_ 2432634208 AutoBlowerLevel_Selection_ISig_4 3000;
BA_REL_ "GenSigTimeoutTime" BU_SG_REL_ CIOM SG_ 2432634208 AutoBlowerLevel_Selection_ISig_4 150;
BA_REL_ "GenSigFirstTimeoutTime" BU_SG_REL_ DACU SG_ 2432634208 CMTelltale_stat_ISig_4 3000;
BA_REL_ "GenSigTimeoutTime" BU_SG_REL_ DACU SG_ 2432634208 CMTelltale_stat_ISig_4 150;
BA_REL_ "GenSigFirstTimeoutTime" BU_SG_REL_ VMCU SG_ 2432634208 SWSpdCtrlButtonsStatus1 3000;
BA_REL_ "GenSigTimeoutTime" BU_SG_REL_ VMCU SG_ 2432634208 SWSpdCtrlButtonsStatus1 150;
BA_REL_ "GenSigFirstTimeoutTime" BU_SG_REL_ DACU SG_ 2432634208 SWSpdCtrlButtonsStatus1 3000;
BA_REL_ "GenSigTimeoutTime" BU_SG_REL_ DACU SG_ 2432634208 SWSpdCtrlButtonsStatus1 150;
BA_REL_ "GenSigFirstTimeoutTime" BU_SG_REL_ CIOM SG_ 2432634208 SWSpdCtrlButtonsStatus1 3000;
BA_REL_ "GenSigTimeoutTime" BU_SG_REL_ CIOM SG_ 2432634208 SWSpdCtrlButtonsStatus1 150;
BA_REL_ "GenSigFirstTimeoutTime" BU_SG_REL_ HMIIOM SG_ 2499755792 SCR_SulphurLevel_ISig_4 3000;
BA_REL_ "GenSigTimeoutTime" BU_SG_REL_ HMIIOM SG_ 2499755792 SCR_SulphurLevel_ISig_4 240;
BA_REL_ "GenSigFirstTimeoutTime" BU_SG_REL_ VMCU SG_ 2549479952 EcoCruisePwtMaxOvSpeedLev3 24000;
BA_REL_ "GenSigTimeoutTime" BU_SG_REL_ VMCU SG_ 2549479952 EcoCruisePwtMaxOvSpeedLev3 6000;
BA_REL_ "GenSigFirstTimeoutTime" BU_SG_REL_ VMCU SG_ 2549479952 EcoCruisePwtMaxOvSpeedLev0 24000;
BA_REL_ "GenSigTimeoutTime" BU_SG_REL_ VMCU SG_ 2549479952 EcoCruisePwtMaxOvSpeedLev0 6000;
BA_REL_ "GenSigFirstTimeoutTime" BU_SG_REL_ VMCU SG_ 2549479952 EcoCruisePwtMaxUnSpeedLev0 24000;
BA_REL_ "GenSigTimeoutTime" BU_SG_REL_ VMCU SG_ 2549479952 EcoCruisePwtMaxUnSpeedLev0 6000;
BA_REL_ "GenSigFirstTimeoutTime" BU_SG_REL_ VMCU SG_ 2549479952 EcoCruisePwtMaxOvSpeedLev2 24000;
BA_REL_ "GenSigTimeoutTime" BU_SG_REL_ VMCU SG_ 2549479952 EcoCruisePwtMaxOvSpeedLev2 6000;
BA_REL_ "GenSigFirstTimeoutTime" BU_SG_REL_ VMCU SG_ 2549479952 EcoCruisePwtMaxOvSpeedLev1 24000;
BA_REL_ "GenSigTimeoutTime" BU_SG_REL_ VMCU SG_ 2549479952 EcoCruisePwtMaxOvSpeedLev1 6000;
BA_REL_ "GenSigFirstTimeoutTime" BU_SG_REL_ VMCU SG_ 2549479952 EcoCruisePwtMaxUnSpeedLev3 24000;
BA_REL_ "GenSigTimeoutTime" BU_SG_REL_ VMCU SG_ 2549479952 EcoCruisePwtMaxUnSpeedLev3 6000;
BA_REL_ "GenSigFirstTimeoutTime" BU_SG_REL_ VMCU SG_ 2549479952 EcoCruisePwtMaxUnSpeedLev1 24000;
BA_REL_ "GenSigTimeoutTime" BU_SG_REL_ VMCU SG_ 2549479952 EcoCruisePwtMaxUnSpeedLev1 6000;
BA_REL_ "GenSigFirstTimeoutTime" BU_SG_REL_ VMCU SG_ 2549479952 EcoCruisePwtMaxUnSpeedLev2 24000;
BA_REL_ "GenSigTimeoutTime" BU_SG_REL_ VMCU SG_ 2549479952 EcoCruisePwtMaxUnSpeedLev2 6000;
BA_REL_ "GenSigFirstTimeoutTime" BU_SG_REL_ VMCU SG_ 2549479440 TotPTOLNGHighAccuracy 24000;
BA_REL_ "GenSigTimeoutTime" BU_SG_REL_ VMCU SG_ 2549479440 TotPTOLNGHighAccuracy 6000;
BA_REL_ "GenSigFirstTimeoutTime" BU_SG_REL_ HMIIOM SG_ 2549478672 EngineFuelMode_ISig_4 12000;
BA_REL_ "GenSigTimeoutTime" BU_SG_REL_ HMIIOM SG_ 2549478672 EngineFuelMode_ISig_4 3000;
BA_REL_ "GenSigFirstTimeoutTime" BU_SG_REL_ VMCU SG_ 2549478672 EngineFuelMode_ISig_4 12000;
BA_REL_ "GenSigTimeoutTime" BU_SG_REL_ VMCU SG_ 2549478672 EngineFuelMode_ISig_4 3000;
BA_REL_ "GenSigFirstTimeoutTime" BU_SG_REL_ HMIIOM SG_ 2549478672 LNGOperatorInducementReason 12000;
BA_REL_ "GenSigTimeoutTime" BU_SG_REL_ HMIIOM SG_ 2549478672 LNGOperatorInducementReason 3000;
BA_REL_ "GenSigFirstTimeoutTime" BU_SG_REL_ HMIIOM SG_ 2549478672 DPF_RegenCompleted_ISig_4 12000;
BA_REL_ "GenSigTimeoutTime" BU_SG_REL_ HMIIOM SG_ 2549478672 DPF_RegenCompleted_ISig_4 3000;
BA_REL_ "GenSigFirstTimeoutTime" BU_SG_REL_ CIOM SG_ 2549478672 EngineTotalLngConsumed_ISig_4 12000;
BA_REL_ "GenSigTimeoutTime" BU_SG_REL_ CIOM SG_ 2549478672 EngineTotalLngConsumed_ISig_4 3000;
BA_REL_ "GenSigFirstTimeoutTime" BU_SG_REL_ HMIIOM SG_ 2549478672 EngineTotalLngConsumed_ISig_4 12000;
BA_REL_ "GenSigTimeoutTime" BU_SG_REL_ HMIIOM SG_ 2549478672 EngineTotalLngConsumed_ISig_4 3000;
BA_REL_ "GenSigFirstTimeoutTime" BU_SG_REL_ VMCU SG_ 2549478672 EngineTotalLngConsumed_ISig_4 12000;
BA_REL_ "GenSigTimeoutTime" BU_SG_REL_ VMCU SG_ 2549478672 EngineTotalLngConsumed_ISig_4 3000;
BA_REL_ "GenSigFirstTimeoutTime" BU_SG_REL_ HMIIOM SG_ 2549478672 SCR_SulphurRegenNeeded_ISig_4 12000;
BA_REL_ "GenSigTimeoutTime" BU_SG_REL_ HMIIOM SG_ 2549478672 SCR_SulphurRegenNeeded_ISig_4 3000;
BA_REL_ "GenSigFirstTimeoutTime" BU_SG_REL_ HMIIOM SG_ 2549030928 DistLeftToSevereInducement_OBD_I 24000;
BA_REL_ "GenSigTimeoutTime" BU_SG_REL_ HMIIOM SG_ 2549030928 DistLeftToSevereInducement_OBD_I 6000;
BA_REL_ "GenSigFirstTimeoutTime" BU_SG_REL_ HMIIOM SG_ 2549030928 RemainingRODTime 24000;
BA_REL_ "GenSigTimeoutTime" BU_SG_REL_ HMIIOM SG_ 2549030928 RemainingRODTime 6000;
BA_REL_ "GenSigFirstTimeoutTime" BU_SG_REL_ HMIIOM SG_ 2549030928 TopGearUseDistance_ISig_4 24000;
BA_REL_ "GenSigTimeoutTime" BU_SG_REL_ HMIIOM SG_ 2549030928 TopGearUseDistance_ISig_4 6000;
BA_REL_ "GenSigFirstTimeoutTime" BU_SG_REL_ HMIIOM SG_ 2566211344 TimeLeftToTorqueReduction_OBD_IS 24000;
BA_REL_ "GenSigTimeoutTime" BU_SG_REL_ HMIIOM SG_ 2566211344 TimeLeftToTorqueReduction_OBD_IS 6000;
BA_REL_ "GenSigFirstTimeoutTime" BU_SG_REL_ VMCU SG_ 2566211344 AdblueTotalConsumed_ISig_4 24000;
BA_REL_ "GenSigTimeoutTime" BU_SG_REL_ VMCU SG_ 2566211344 AdblueTotalConsumed_ISig_4 6000;
BA_REL_ "GenSigFirstTimeoutTime" BU_SG_REL_ HMIIOM SG_ 2566211344 AdblueTotalConsumed_ISig_4 24000;
BA_REL_ "GenSigTimeoutTime" BU_SG_REL_ HMIIOM SG_ 2566211344 AdblueTotalConsumed_ISig_4 6000;
BA_REL_ "GenSigFirstTimeoutTime" BU_SG_REL_ VMCU SG_ 2566211344 MIStatus_ISig_4 24000;
BA_REL_ "GenSigTimeoutTime" BU_SG_REL_ VMCU SG_ 2566211344 MIStatus_ISig_4 6000;
BA_REL_ "GenSigFirstTimeoutTime" BU_SG_REL_ HMIIOM SG_ 2566211344 MIStatus_ISig_4 24000;
BA_REL_ "GenSigTimeoutTime" BU_SG_REL_ HMIIOM SG_ 2566211344 MIStatus_ISig_4 6000;
BA_REL_ "GenSigFirstTimeoutTime" BU_SG_REL_ HMIIOM SG_ 2566211344 AshLevelHigh 24000;
BA_REL_ "GenSigTimeoutTime" BU_SG_REL_ HMIIOM SG_ 2566211344 AshLevelHigh 6000;
BA_REL_ "GenSigFirstTimeoutTime" BU_SG_REL_ HMIIOM SG_ 2566211344 TorqueReductionStatus_OBD_ISig_4 24000;
BA_REL_ "GenSigTimeoutTime" BU_SG_REL_ HMIIOM SG_ 2566211344 TorqueReductionStatus_OBD_ISig_4 6000;
BA_REL_ "GenSigFirstTimeoutTime" BU_SG_REL_ HMIIOM SG_ 2566211344 SCROperatorInducementSeverity_IS 24000;
BA_REL_ "GenSigTimeoutTime" BU_SG_REL_ HMIIOM SG_ 2566211344 SCROperatorInducementSeverity_IS 6000;
BA_REL_ "GenSigFirstTimeoutTime" BU_SG_REL_ HMIIOM SG_ 2566211344 SCROperatorInducementReason_ISig 24000;
BA_REL_ "GenSigTimeoutTime" BU_SG_REL_ HMIIOM SG_ 2566211344 SCROperatorInducementReason_ISig 6000;
BA_REL_ "GenSigFirstTimeoutTime" BU_SG_REL_ VMCU SG_ 2566211344 MIDistinctWarning_ISig_4 24000;
BA_REL_ "GenSigTimeoutTime" BU_SG_REL_ VMCU SG_ 2566211344 MIDistinctWarning_ISig_4 6000;
BA_REL_ "GenSigFirstTimeoutTime" BU_SG_REL_ HMIIOM SG_ 2566211344 MIDistinctWarning_ISig_4 24000;
BA_REL_ "GenSigTimeoutTime" BU_SG_REL_ HMIIOM SG_ 2566211344 MIDistinctWarning_ISig_4 6000;
BA_REL_ "GenSigFirstTimeoutTime" BU_SG_REL_ HMIIOM SG_ 2566211344 MIStatusExtEMS_ISig_4 24000;
BA_REL_ "GenSigTimeoutTime" BU_SG_REL_ HMIIOM SG_ 2566211344 MIStatusExtEMS_ISig_4 6000;
BA_REL_ "GenSigFirstTimeoutTime" BU_SG_REL_ VMCU SG_ 2566211344 MIDistinctWarningExtEMS_ISig_4 24000;
BA_REL_ "GenSigTimeoutTime" BU_SG_REL_ VMCU SG_ 2566211344 MIDistinctWarningExtEMS_ISig_4 6000;
BA_REL_ "GenSigFirstTimeoutTime" BU_SG_REL_ HMIIOM SG_ 2566211344 MIDistinctWarningExtEMS_ISig_4 24000;
BA_REL_ "GenSigTimeoutTime" BU_SG_REL_ HMIIOM SG_ 2566211344 MIDistinctWarningExtEMS_ISig_4 6000;
BA_REL_ "GenSigFirstTimeoutTime" BU_SG_REL_ BBM SG_ 2566356790 EngineRunningTime_ISig_4 28800;
BA_REL_ "GenSigTimeoutTime" BU_SG_REL_ BBM SG_ 2566356790 EngineRunningTime_ISig_4 7200;
BA_REL_ "GenSigFirstTimeoutTime" BU_SG_REL_ HMIIOM SG_ 2566356790 EngineRunningTime_ISig_4 28800;
BA_REL_ "GenSigTimeoutTime" BU_SG_REL_ HMIIOM SG_ 2566356790 EngineRunningTime_ISig_4 7200;
BA_REL_ "GenSigFirstTimeoutTime" BU_SG_REL_ VMCU SG_ 2566356790 EngineRunningTime_ISig_4 28800;
BA_REL_ "GenSigTimeoutTime" BU_SG_REL_ VMCU SG_ 2566356790 EngineRunningTime_ISig_4 7200;
BA_REL_ "GenSigFirstTimeoutTime" BU_SG_REL_ CIOM SG_ 2566356790 EngineRunningTime_ISig_4 28800;
BA_REL_ "GenSigTimeoutTime" BU_SG_REL_ CIOM SG_ 2566356790 EngineRunningTime_ISig_4 7200;
BA_REL_ "GenSigFirstTimeoutTime" BU_SG_REL_ VMCU SG_ 2566356790 TotPTOFuelHighAccuracy 28800;
BA_REL_ "GenSigTimeoutTime" BU_SG_REL_ VMCU SG_ 2566356790 TotPTOFuelHighAccuracy 7200;
BA_REL_ "GenSigFirstTimeoutTime" BU_SG_REL_ CIOM SG_ 2566356786 OilPrediction_Quality 36000;
BA_REL_ "GenSigTimeoutTime" BU_SG_REL_ CIOM SG_ 2566356786 OilPrediction_Quality 9000;
BA_REL_ "GenSigFirstTimeoutTime" BU_SG_REL_ VMCU SG_ 2566356786 OilPrediction_Quality 36000;
BA_REL_ "GenSigTimeoutTime" BU_SG_REL_ VMCU SG_ 2566356786 OilPrediction_Quality 9000;
BA_REL_ "GenSigFirstTimeoutTime" BU_SG_REL_ HMIIOM SG_ 2566356786 TimeLeftToVehSpdReduction_OBD_IS 36000;
BA_REL_ "GenSigTimeoutTime" BU_SG_REL_ HMIIOM SG_ 2566356786 TimeLeftToVehSpdReduction_OBD_IS 9000;
BA_REL_ "GenSigFirstTimeoutTime" BU_SG_REL_ CIOM SG_ 2566356786 OilPrediction_RemainDist 36000;
BA_REL_ "GenSigTimeoutTime" BU_SG_REL_ CIOM SG_ 2566356786 OilPrediction_RemainDist 9000;
BA_REL_ "GenSigFirstTimeoutTime" BU_SG_REL_ VMCU SG_ 2566356786 OilPrediction_RemainDist 36000;
BA_REL_ "GenSigTimeoutTime" BU_SG_REL_ VMCU SG_ 2566356786 OilPrediction_RemainDist 9000;
BA_REL_ "GenSigFirstTimeoutTime" BU_SG_REL_ HMIIOM SG_ 2566356786 TimeToCorrectOilLevel_ISig_4 36000;
BA_REL_ "GenSigTimeoutTime" BU_SG_REL_ HMIIOM SG_ 2566356786 TimeToCorrectOilLevel_ISig_4 9000;
BA_REL_ "GenSigFirstTimeoutTime" BU_SG_REL_ VGGSECUSystem SG_ 2566356786 TimeToCorrectOilLevel_ISig_4 36000;
BA_REL_ "GenSigTimeoutTime" BU_SG_REL_ VGGSECUSystem SG_ 2566356786 TimeToCorrectOilLevel_ISig_4 9000;
BA_REL_ "GenSigFirstTimeoutTime" BU_SG_REL_ VMCU SG_ 2566356786 OilPrediction_RemainTime 36000;
BA_REL_ "GenSigTimeoutTime" BU_SG_REL_ VMCU SG_ 2566356786 OilPrediction_RemainTime 9000;
BA_REL_ "GenSigFirstTimeoutTime" BU_SG_REL_ CIOM SG_ 2566356786 OilPrediction_RemainTime 36000;
BA_REL_ "GenSigTimeoutTime" BU_SG_REL_ CIOM SG_ 2566356786 OilPrediction_RemainTime 9000;
BA_REL_ "GenSigFirstTimeoutTime" BU_SG_REL_ CIOM SG_ 2566356786 OilPrediction_Status 36000;
BA_REL_ "GenSigTimeoutTime" BU_SG_REL_ CIOM SG_ 2566356786 OilPrediction_Status 9000;
BA_REL_ "GenSigFirstTimeoutTime" BU_SG_REL_ VMCU SG_ 2566356786 OilPrediction_Status 36000;
BA_REL_ "GenSigTimeoutTime" BU_SG_REL_ VMCU SG_ 2566356786 OilPrediction_Status 9000;
BA_REL_ "GenSigFirstTimeoutTime" BU_SG_REL_ VGGSECUSystem SG_ 2549445904 EngineCoolingFanSpeed_ISig_4 6000;
BA_REL_ "GenSigTimeoutTime" BU_SG_REL_ VGGSECUSystem SG_ 2549445904 EngineCoolingFanSpeed_ISig_4 1500;
BA_REL_ "GenSigFirstTimeoutTime" BU_SG_REL_ CIOM SG_ 2549445904 EngineCoolingFanSpeed_ISig_4 6000;
BA_REL_ "GenSigTimeoutTime" BU_SG_REL_ CIOM SG_ 2549445904 EngineCoolingFanSpeed_ISig_4 1500;
BA_REL_ "GenSigFirstTimeoutTime" BU_SG_REL_ VMCU SG_ 2549445904 DMSDriverFollow 6000;
BA_REL_ "GenSigTimeoutTime" BU_SG_REL_ VMCU SG_ 2549445904 DMSDriverFollow 1500;
BA_REL_ "GenSigFirstTimeoutTime" BU_SG_REL_ CIOM SG_ 2549445904 CoolantPumpEngagementStatus_ISig 6000;
BA_REL_ "GenSigTimeoutTime" BU_SG_REL_ CIOM SG_ 2549445904 CoolantPumpEngagementStatus_ISig 1500;
BA_REL_ "GenSigFirstTimeoutTime" BU_SG_REL_ HMIIOM SG_ 2549445904 AverageFuelEconomy_ISig_4 6000;
BA_REL_ "GenSigTimeoutTime" BU_SG_REL_ HMIIOM SG_ 2549445904 AverageFuelEconomy_ISig_4 1500;
BA_REL_ "GenSigFirstTimeoutTime" BU_SG_REL_ VMCU SG_ 2549445904 EngineGasRate 6000;
BA_REL_ "GenSigTimeoutTime" BU_SG_REL_ VMCU SG_ 2549445904 EngineGasRate 1500;
BA_REL_ "GenSigFirstTimeoutTime" BU_SG_REL_ CIOM SG_ 2549445904 EngineGasRate 6000;
BA_REL_ "GenSigTimeoutTime" BU_SG_REL_ CIOM SG_ 2549445904 EngineGasRate 1500;
BA_REL_ "GenSigFirstTimeoutTime" BU_SG_REL_ HMIIOM SG_ 2549445904 EngineGasRate 6000;
BA_REL_ "GenSigTimeoutTime" BU_SG_REL_ HMIIOM SG_ 2549445904 EngineGasRate 1500;
BA_REL_ "GenSigFirstTimeoutTime" BU_SG_REL_ VMCU SG_ 2549445904 FuelEcoEngStatus 6000;
BA_REL_ "GenSigTimeoutTime" BU_SG_REL_ VMCU SG_ 2549445904 FuelEcoEngStatus 1500;
BA_REL_ "GenSigFirstTimeoutTime" BU_SG_REL_ VGGSECUSystem SG_ 2549579536 DrainPrimingStatus_ISig_4 6000;
BA_REL_ "GenSigTimeoutTime" BU_SG_REL_ VGGSECUSystem SG_ 2549579536 DrainPrimingStatus_ISig_4 1500;
BA_REL_ "GenSigFirstTimeoutTime" BU_SG_REL_ HMIIOM SG_ 2549579536 DrainPrimingStatus_ISig_4 6000;
BA_REL_ "GenSigTimeoutTime" BU_SG_REL_ HMIIOM SG_ 2549579536 DrainPrimingStatus_ISig_4 1500;
BA_REL_ "GenSigFirstTimeoutTime" BU_SG_REL_ HMIIOM SG_ 2549579536 CoolantTempHigh_ISig_4 6000;
BA_REL_ "GenSigTimeoutTime" BU_SG_REL_ HMIIOM SG_ 2549579536 CoolantTempHigh_ISig_4 1500;
BA_REL_ "GenSigFirstTimeoutTime" BU_SG_REL_ VMCU SG_ 2549579536 CoolantTempHigh_ISig_4 6000;
BA_REL_ "GenSigTimeoutTime" BU_SG_REL_ VMCU SG_ 2549579536 CoolantTempHigh_ISig_4 1500;
BA_REL_ "GenSigFirstTimeoutTime" BU_SG_REL_ VGGSECUSystem SG_ 2549579536 CoolantTempHigh_ISig_4 6000;
BA_REL_ "GenSigTimeoutTime" BU_SG_REL_ VGGSECUSystem SG_ 2549579536 CoolantTempHigh_ISig_4 1500;
BA_REL_ "GenSigFirstTimeoutTime" BU_SG_REL_ BBM SG_ 2549579536 CoolantTempHigh_ISig_4 6000;
BA_REL_ "GenSigTimeoutTime" BU_SG_REL_ BBM SG_ 2549579536 CoolantTempHigh_ISig_4 1500;
BA_REL_ "GenSigFirstTimeoutTime" BU_SG_REL_ VMCU SG_ 2549579536 CoolantLevelLow_ISig_4 6000;
BA_REL_ "GenSigTimeoutTime" BU_SG_REL_ VMCU SG_ 2549579536 CoolantLevelLow_ISig_4 1500;
BA_REL_ "GenSigFirstTimeoutTime" BU_SG_REL_ BBM SG_ 2549579536 CoolantLevelLow_ISig_4 6000;
BA_REL_ "GenSigTimeoutTime" BU_SG_REL_ BBM SG_ 2549579536 CoolantLevelLow_ISig_4 1500;
BA_REL_ "GenSigFirstTimeoutTime" BU_SG_REL_ HMIIOM SG_ 2549579536 CoolantLevelLow_ISig_4 6000;
BA_REL_ "GenSigTimeoutTime" BU_SG_REL_ HMIIOM SG_ 2549579536 CoolantLevelLow_ISig_4 1500;
BA_REL_ "GenSigFirstTimeoutTime" BU_SG_REL_ VGGSECUSystem SG_ 2549579536 CoolantLevelLow_ISig_4 6000;
BA_REL_ "GenSigTimeoutTime" BU_SG_REL_ VGGSECUSystem SG_ 2549579536 CoolantLevelLow_ISig_4 1500;
BA_REL_ "GenSigFirstTimeoutTime" BU_SG_REL_ TECU SG_ 2549579536 AutoWheelBrakesStatus 6000;
BA_REL_ "GenSigTimeoutTime" BU_SG_REL_ TECU SG_ 2549579536 AutoWheelBrakesStatus 1500;
BA_REL_ "GenSigFirstTimeoutTime" BU_SG_REL_ VMCU SG_ 2549579536 OilPressureLow_ISig_4 6000;
BA_REL_ "GenSigTimeoutTime" BU_SG_REL_ VMCU SG_ 2549579536 OilPressureLow_ISig_4 1500;
BA_REL_ "GenSigFirstTimeoutTime" BU_SG_REL_ HMIIOM SG_ 2549579536 OilPressureLow_ISig_4 6000;
BA_REL_ "GenSigTimeoutTime" BU_SG_REL_ HMIIOM SG_ 2549579536 OilPressureLow_ISig_4 1500;
BA_REL_ "GenSigFirstTimeoutTime" BU_SG_REL_ BBM SG_ 2549579536 OilPressureLow_ISig_4 6000;
BA_REL_ "GenSigTimeoutTime" BU_SG_REL_ BBM SG_ 2549579536 OilPressureLow_ISig_4 1500;
BA_REL_ "GenSigFirstTimeoutTime" BU_SG_REL_ VGGSECUSystem SG_ 2549579536 OilPressureLow_ISig_4 6000;
BA_REL_ "GenSigTimeoutTime" BU_SG_REL_ VGGSECUSystem SG_ 2549579536 OilPressureLow_ISig_4 1500;
BA_REL_ "GenSigFirstTimeoutTime" BU_SG_REL_ HMIIOM SG_ 2549579536 EngineTotalFuelConsumed_ISig_4 6000;
BA_REL_ "GenSigTimeoutTime" BU_SG_REL_ HMIIOM SG_ 2549579536 EngineTotalFuelConsumed_ISig_4 1500;
BA_REL_ "GenSigFirstTimeoutTime" BU_SG_REL_ BBM SG_ 2549579536 EngineTotalFuelConsumed_ISig_4 6000;
BA_REL_ "GenSigTimeoutTime" BU_SG_REL_ BBM SG_ 2549579536 EngineTotalFuelConsumed_ISig_4 1500;
BA_REL_ "GenSigFirstTimeoutTime" BU_SG_REL_ CIOM SG_ 2549579536 EngineTotalFuelConsumed_ISig_4 6000;
BA_REL_ "GenSigTimeoutTime" BU_SG_REL_ CIOM SG_ 2549579536 EngineTotalFuelConsumed_ISig_4 1500;
BA_REL_ "GenSigFirstTimeoutTime" BU_SG_REL_ VMCU SG_ 2549579536 EngineTotalFuelConsumed_ISig_4 6000;
BA_REL_ "GenSigTimeoutTime" BU_SG_REL_ VMCU SG_ 2549579536 EngineTotalFuelConsumed_ISig_4 1500;
BA_REL_ "GenSigFirstTimeoutTime" BU_SG_REL_ TECU SG_ 2549579536 EngineTotalFuelConsumed_ISig_4 3000;
BA_REL_ "GenSigTimeoutTime" BU_SG_REL_ TECU SG_ 2549579536 EngineTotalFuelConsumed_ISig_4 1500;
BA_REL_ "GenSigFirstTimeoutTime" BU_SG_REL_ HMIIOM SG_ 2549579536 TopGearMode_ISig_4 6000;
BA_REL_ "GenSigTimeoutTime" BU_SG_REL_ HMIIOM SG_ 2549579536 TopGearMode_ISig_4 1500;
BA_REL_ "GenSigFirstTimeoutTime" BU_SG_REL_ VGGSECUSystem SG_ 2549579536 OilLevelLow_ISig_4 6000;
BA_REL_ "GenSigTimeoutTime" BU_SG_REL_ VGGSECUSystem SG_ 2549579536 OilLevelLow_ISig_4 1500;
BA_REL_ "GenSigFirstTimeoutTime" BU_SG_REL_ HMIIOM SG_ 2549579536 OilLevelLow_ISig_4 6000;
BA_REL_ "GenSigTimeoutTime" BU_SG_REL_ HMIIOM SG_ 2549579536 OilLevelLow_ISig_4 1500;
BA_REL_ "GenSigFirstTimeoutTime" BU_SG_REL_ BBM SG_ 2549579536 OilLevelLow_ISig_4 6000;
BA_REL_ "GenSigTimeoutTime" BU_SG_REL_ BBM SG_ 2549579536 OilLevelLow_ISig_4 1500;
BA_REL_ "GenSigFirstTimeoutTime" BU_SG_REL_ TECU SG_ 2549579536 BarometricPressure_ISig_4 6000;
BA_REL_ "GenSigTimeoutTime" BU_SG_REL_ TECU SG_ 2549579536 BarometricPressure_ISig_4 1500;
BA_REL_ "GenSigFirstTimeoutTime" BU_SG_REL_ BBM SG_ 2549579536 BarometricPressure_ISig_4 6000;
BA_REL_ "GenSigTimeoutTime" BU_SG_REL_ BBM SG_ 2549579536 BarometricPressure_ISig_4 1500;
BA_REL_ "GenSigFirstTimeoutTime" BU_SG_REL_ VMCU SG_ 2549579536 BarometricPressure_ISig_4 6000;
BA_REL_ "GenSigTimeoutTime" BU_SG_REL_ VMCU SG_ 2549579536 BarometricPressure_ISig_4 1500;
BA_REL_ "GenSigFirstTimeoutTime" BU_SG_REL_ HMIIOM SG_ 2549579536 InletAirHeaterStatus1_ISig_4 6000;
BA_REL_ "GenSigTimeoutTime" BU_SG_REL_ HMIIOM SG_ 2549579536 InletAirHeaterStatus1_ISig_4 1500;
BA_REL_ "GenSigFirstTimeoutTime" BU_SG_REL_ VGGSECUSystem SG_ 2549579536 InletAirHeaterStatus1_ISig_4 6000;
BA_REL_ "GenSigTimeoutTime" BU_SG_REL_ VGGSECUSystem SG_ 2549579536 InletAirHeaterStatus1_ISig_4 1500;
BA_REL_ "GenSigFirstTimeoutTime" BU_SG_REL_ VGGSECUSystem SG_ 2549478160 FuelFilterClogged_ISig_4 6000;
BA_REL_ "GenSigTimeoutTime" BU_SG_REL_ VGGSECUSystem SG_ 2549478160 FuelFilterClogged_ISig_4 1500;
BA_REL_ "GenSigFirstTimeoutTime" BU_SG_REL_ HMIIOM SG_ 2549478160 FuelFilterClogged_ISig_4 6000;
BA_REL_ "GenSigTimeoutTime" BU_SG_REL_ HMIIOM SG_ 2549478160 FuelFilterClogged_ISig_4 1500;
BA_REL_ "GenSigFirstTimeoutTime" BU_SG_REL_ VMCU SG_ 2549478160 EngineAirInletTemperature 6000;
BA_REL_ "GenSigTimeoutTime" BU_SG_REL_ VMCU SG_ 2549478160 EngineAirInletTemperature 1500;
BA_REL_ "GenSigFirstTimeoutTime" BU_SG_REL_ VGGSECUSystem SG_ 2549478160 StarterMotorRecoveryTime_ISig_4 6000;
BA_REL_ "GenSigTimeoutTime" BU_SG_REL_ VGGSECUSystem SG_ 2549478160 StarterMotorRecoveryTime_ISig_4 1500;
BA_REL_ "GenSigFirstTimeoutTime" BU_SG_REL_ HMIIOM SG_ 2549478160 StarterMotorRecoveryTime_ISig_4 6000;
BA_REL_ "GenSigTimeoutTime" BU_SG_REL_ HMIIOM SG_ 2549478160 StarterMotorRecoveryTime_ISig_4 1500;
BA_REL_ "GenSigFirstTimeoutTime" BU_SG_REL_ HMIIOM SG_ 2549478160 AirFilterPressureDrop 6000;
BA_REL_ "GenSigTimeoutTime" BU_SG_REL_ HMIIOM SG_ 2549478160 AirFilterPressureDrop 1500;
BA_REL_ "GenSigFirstTimeoutTime" BU_SG_REL_ VGGSECUSystem SG_ 2549478160 AirFilterPressureDrop 6000;
BA_REL_ "GenSigTimeoutTime" BU_SG_REL_ VGGSECUSystem SG_ 2549478160 AirFilterPressureDrop 1500;
BA_REL_ "GenSigFirstTimeoutTime" BU_SG_REL_ VMCU SG_ 2549478160 AppliedVehicleSpeedLimit 6000;
BA_REL_ "GenSigTimeoutTime" BU_SG_REL_ VMCU SG_ 2549478160 AppliedVehicleSpeedLimit 1500;
BA_REL_ "GenSigFirstTimeoutTime" BU_SG_REL_ TECU SG_ 2549478160 AppliedVehicleSpeedLimit 6000;
BA_REL_ "GenSigTimeoutTime" BU_SG_REL_ TECU SG_ 2549478160 AppliedVehicleSpeedLimit 1500;
BA_REL_ "GenSigFirstTimeoutTime" BU_SG_REL_ HMIIOM SG_ 2549478160 AppliedVehicleSpeedLimit 6000;
BA_REL_ "GenSigTimeoutTime" BU_SG_REL_ HMIIOM SG_ 2549478160 AppliedVehicleSpeedLimit 1500;
BA_REL_ "GenSigFirstTimeoutTime" BU_SG_REL_ VGGSECUSystem SG_ 2549478160 EngineProtDerateStat 6000;
BA_REL_ "GenSigTimeoutTime" BU_SG_REL_ VGGSECUSystem SG_ 2549478160 EngineProtDerateStat 1500;
BA_REL_ "GenSigFirstTimeoutTime" BU_SG_REL_ VMCU SG_ 2549478160 EngineProtDerateStat 6000;
BA_REL_ "GenSigTimeoutTime" BU_SG_REL_ VMCU SG_ 2549478160 EngineProtDerateStat 1500;
BA_REL_ "GenSigFirstTimeoutTime" BU_SG_REL_ HMIIOM SG_ 2549478160 ClutchOverloadStatusMan 6000;
BA_REL_ "GenSigTimeoutTime" BU_SG_REL_ HMIIOM SG_ 2549478160 ClutchOverloadStatusMan 1500;
BA_REL_ "GenSigFirstTimeoutTime" BU_SG_REL_ VGGSECUSystem SG_ 2549478160 CoolantTempGaugeAdjustment_ISig_ 6000;
BA_REL_ "GenSigTimeoutTime" BU_SG_REL_ VGGSECUSystem SG_ 2549478160 CoolantTempGaugeAdjustment_ISig_ 1500;
BA_REL_ "GenSigFirstTimeoutTime" BU_SG_REL_ HMIIOM SG_ 2549478160 CoolantTempGaugeAdjustment_ISig_ 6000;
BA_REL_ "GenSigTimeoutTime" BU_SG_REL_ HMIIOM SG_ 2549478160 CoolantTempGaugeAdjustment_ISig_ 1500;
BA_REL_ "GenSigFirstTimeoutTime" BU_SG_REL_ VGGSECUSystem SG_ 2549478160 EngineFanOverspeed 6000;
BA_REL_ "GenSigTimeoutTime" BU_SG_REL_ VGGSECUSystem SG_ 2549478160 EngineFanOverspeed 1500;
BA_REL_ "GenSigFirstTimeoutTime" BU_SG_REL_ HMIIOM SG_ 2549478160 EngineFanOverspeed 6000;
BA_REL_ "GenSigTimeoutTime" BU_SG_REL_ HMIIOM SG_ 2549478160 EngineFanOverspeed 1500;
BA_REL_ "GenSigFirstTimeoutTime" BU_SG_REL_ HMIIOM SG_ 2466232336 DPF_LimitedSpeedDuetoInhibit_ISi 3000;
BA_REL_ "GenSigTimeoutTime" BU_SG_REL_ HMIIOM SG_ 2466232336 DPF_LimitedSpeedDuetoInhibit_ISi 270;
BA_REL_ "GenSigFirstTimeoutTime" BU_SG_REL_ HMIIOM SG_ 2466232336 DMSRecommendedGear 3000;
BA_REL_ "GenSigTimeoutTime" BU_SG_REL_ HMIIOM SG_ 2466232336 DMSRecommendedGear 270;
BA_REL_ "GenSigFirstTimeoutTime" BU_SG_REL_ DACU SG_ 2466232336 XARSystemState 3000;
BA_REL_ "GenSigTimeoutTime" BU_SG_REL_ DACU SG_ 2466232336 XARSystemState 270;
BA_REL_ "GenSigFirstTimeoutTime" BU_SG_REL_ DACU SG_ 2466232336 XARActiveControlMode 3000;
BA_REL_ "GenSigTimeoutTime" BU_SG_REL_ DACU SG_ 2466232336 XARActiveControlMode 270;
BA_REL_ "GenSigFirstTimeoutTime" BU_SG_REL_ VMCU SG_ 2466232336 CCBSetSpeedApplied 3000;
BA_REL_ "GenSigTimeoutTime" BU_SG_REL_ VMCU SG_ 2466232336 CCBSetSpeedApplied 270;
BA_REL_ "GenSigFirstTimeoutTime" BU_SG_REL_ DACU SG_ 2466232336 CCBSetSpeedApplied 3000;
BA_REL_ "GenSigTimeoutTime" BU_SG_REL_ DACU SG_ 2466232336 CCBSetSpeedApplied 270;
VAL_ 2483002322 AudioSourceBtStreamAvailable_ISi 3 "FalseTrue_NotAvaiable" 2 "FalseTrue_Error" 1 "FalseTrue_True" 0 "FalseTrue_False" ;
VAL_ 2483002322 MainBeam_StalkStatus_4 7 "MainBeam_StalkStatus_NotAvailable" 6 "MainBeam_StalkStatus_Error" 5 "MainBeam_StalkStatus_Spare_02" 4 "MainBeam_StalkStatus_Spare_01" 3 "MainBeam_StalkStatus_Spare" 2 "MainBeam_StalkStatus_ToggleMainBeam" 1 "MainBeam_StalkStatus_FlashToPass" 0 "MainBeam_StalkStatus_NeutralRestingPosition" ;
VAL_ 2483002322 AudioSourceCdAvailable_ISig_4 3 "FalseTrue_NotAvaiable" 2 "FalseTrue_Error" 1 "FalseTrue_True" 0 "FalseTrue_False" ;
VAL_ 2483002322 LightMode_SwitchStatus 7 "LightMode_SwitchStatus_NotAvailable" 6 "LightMode_SwitchStatus_Error" 5 "LightMode_SwitchStatus_Spare3" 4 "LightMode_SwitchStatus_Spare2" 3 "LightMode_SwitchStatus_Spare1" 2 "LightMode_SwitchStatus_Drive" 1 "LightMode_SwitchStatus_PositionLights" 0 "LightMode_SwitchStatus_Off_DRL" ;
VAL_ 2483002322 PhoneButtonIndication_cmd 3 "DeviceIndication_SpareValue" 2 "DeviceIndication_Blink" 1 "DeviceIndication_On" 0 "DeviceIndication_Off" ;
VAL_ 2483002322 AudioSourceIpodAvailable_ISig_4 3 "FalseTrue_NotAvaiable" 2 "FalseTrue_Error" 1 "FalseTrue_True" 0 "FalseTrue_False" ;
VAL_ 2483002322 AudioSystemStatus_ISig_4 3 "OffOn_NotAvailable" 2 "OffOn_Error" 1 "OffOn_On" 0 "OffOn_Off" ;
VAL_ 2483002322 WiperAdjustStatus_4 7 "WiperAdjustStatus_4_NotAvailable" 6 "WiperAdjustStatus_4_Error" 5 "WiperAdjustStatus_4_Spare2" 4 "WiperAdjustStatus_4_Spare1" 3 "WiperAdjustStatus_4_WiperAdjust3" 2 "WiperAdjustStatus_4_WiperAdjust2" 1 "WiperAdjustStatus_4_WiperAdjust1" 0 "WiperAdjustStatus_4_WiperAdjust0" ;
VAL_ 2483002322 AudioSourceUsbAvailable_ISig_4 3 "FalseTrue_NotAvaiable" 2 "FalseTrue_Error" 1 "FalseTrue_True" 0 "FalseTrue_False" ;
VAL_ 2483002322 BTStatus 3 "BTStatus_NotAvailable" 2 "BTStatus_BTOnAndDeviceConnected" 1 "BTStatus_BTOnAndNoDeviceConnected" 0 "BTStatus_BTOff" ;
VAL_ 2483002322 AudioSourceStatus_ISig_4 7 "AudioSourceStatus_NotAvailable" 6 "AudioSourceStatus_Error" 5 "AudioSourceStatus_AUX1" 4 "AudioSourceStatus_iPod" 3 "AudioSourceStatus_AUX2" 2 "AudioSourceStatus_USB" 1 "AudioSourceStatus_CD" 0 "AudioSourceStatus_Radio" ;
VAL_ 2483002322 Washing_Status_4 3 "A2PosSwitchStatus_NotAvailable" 2 "A2PosSwitchStatus_Error" 1 "A2PosSwitchStatus_On" 0 "A2PosSwitchStatus_Off" ;
VAL_ 2483002322 WiperStalkStat_4 7 "WiperStalkStat_4_NotAvailable" 6 "WiperStalkStat_4_Error" 5 "WiperStalkStat_4_Spare2" 4 "WiperStalkStat_4_FastPosition" 3 "WiperStalkStat_4_NormalPosition" 2 "WiperStalkStat_4_IntermittentPosition" 1 "WiperStalkStat_4_Spare1" 0 "WiperStalkStat_4_Idle" ;
VAL_ 2483002322 AudioSourceStatus2_ISig_4 15 "AudioSource_stat4bit_NotAvailable" 14 "AudioSource_stat4bit_Error" 13 "AudioSource_stat4bit_Spare7" 12 "AudioSource_stat4bit_Spare6" 11 "AudioSource_stat4bit_Spare5" 10 "AudioSource_stat4bit_Spare4" 9 "AudioSource_stat4bit_Spare3" 8 "AudioSource_stat4bit_Spare2" 7 "AudioSource_stat4bit_Spare1" 6 "AudioSource_stat4bit_BtStream" 5 "AudioSource_stat4bit_AUX1" 4 "AudioSource_stat4bit_IPOD" 3 "AudioSource_stat4bit_AUX2" 2 "AudioSource_stat4bit_USB" 1 "AudioSource_stat4bit_CD" 0 "AudioSource_stat4bit_Radio" ;
VAL_ 2483002322 BrakeBlending_DeviceIndication 3 "DeviceIndication_SpareValue" 2 "DeviceIndication_Blink" 1 "DeviceIndication_On" 0 "DeviceIndication_Off" ;
VAL_ 2483002322 BunkBacklightCmd_ISig_4 31 "BacklightCmd_NotAvailable" 30 "BacklightCmd_Error" 16 "BacklightCmd_BacklightLevel16" 15 "BacklightCmd_BacklightLevel15" 14 "BacklightCmd_BacklightLevel14" 13 "BacklightCmd_BacklightLevel13" 12 "BacklightCmd_BacklightLevel12" 11 "BacklightCmd_BacklightLevel11" 10 "BacklightCmd_BacklightLevel10" 9 "BacklightCmd_BacklightLevel9" 8 "BacklightCmd_BacklightLevel8" 7 "BacklightCmd_BacklightLevel7" 6 "BacklightCmd_BacklightLevel6" 5 "BacklightCmd_BacklightLevel5" 4 "BacklightCmd_BacklightLevel4" 3 "BacklightCmd_BacklightLevel3" 2 "BacklightCmd_BacklightLevel2" 1 "BacklightCmd_BacklightLevel1" 0 "BacklightCmd_BacklightOff" ;
VAL_ 2483002322 ABSInhibit_DeviceIndication 3 "DeviceIndication_SpareValue" 2 "DeviceIndication_Blink" 1 "DeviceIndication_On" 0 "DeviceIndication_Off" ;
VAL_ 2483002322 DayOfWeek_stat_ISig_4 15 "DayOfWeek_NotAvailable" 14 "DayOfWeek_Error" 13 "DayOfWeek_Spare_7" 12 "DayOfWeek_Spare_6" 11 "DayOfWeek_Spare_5" 10 "DayOfWeek_Spare_4" 9 "DayOfWeek_Spare_3" 8 "DayOfWeek_Spare_2" 7 "DayOfWeek_Spare_1" 6 "DayOfWeek_Sunday" 5 "DayOfWeek_Saturday" 4 "DayOfWeek_Friday" 3 "DayOfWeek_Thursday" 2 "DayOfWeek_Wednesday" 1 "DayOfWeek_Tuesday" 0 "DayOfWeek_Monday" ;
VAL_ 2499765032 PHTimerGUIEvCmd_Timer2Temp_ISig_ 31 "TemperatureRqstIndication_cmd_NotAvailable" 30 "TemperatureRqstIndication_cmd_Error" 29 "TemperatureRqstIndication_cmd_Spare_01" 28 "TemperatureRqstIndication_cmd_Spare" 27 "TemperatureRqstIndication_cmd_Max" 26 "TemperatureRqstIndication_cmd_29C" 25 "TemperatureRqstIndication_cmd_28C" 24 "TemperatureRqstIndication_cmd_27C" 23 "TemperatureRqstIndication_cmd_26C" 22 "TemperatureRqstIndication_cmd_25_5C" 21 "TemperatureRqstIndication_cmd_25C" 20 "TemperatureRqstIndication_cmd_24_5C" 19 "TemperatureRqstIndication_cmd_24C" 18 "TemperatureRqstIndication_cmd_23_5C" 17 "TemperatureRqstIndication_cmd_23C" 16 "TemperatureRqstIndication_cmd_22_5C" 15 "TemperatureRqstIndication_cmd_22C" 14 "TemperatureRqstIndication_cmd_21_5C" 13 "TemperatureRqstIndication_cmd_21C" 12 "TemperatureRqstIndication_cmd_20_5C" 11 "TemperatureRqstIndication_cmd_20C" 10 "TemperatureRqstIndication_cmd_19_5C" 9 "TemperatureRqstIndication_cmd_19C" 8 "TemperatureRqstIndication_cmd_18_5C" 7 "TemperatureRqstIndication_cmd_18C" 6 "TemperatureRqstIndication_cmd_17_5C" 5 "TemperatureRqstIndication_cmd_17C" 4 "TemperatureRqstIndication_cmd_16_5C" 3 "TemperatureRqstIndication_cmd_16C" 2 "TemperatureRqstIndication_cmd_15C" 1 "TemperatureRqstIndication_cmd_Min" 0 "TemperatureRqstIndication_cmd_NoTempDisplayed" ;
VAL_ 2499765032 PHTimerGUIEvCmd_Timer1Recur_ISig 15 "HeaterTimerRecurrence_NotAvailable" 14 "HeaterTimerRecurrence_Error" 13 "HeaterTimerRecurrence_Spare_3" 12 "HeaterTimerRecurrence_Spare_2" 11 "HeaterTimerRecurrence_Spare_1" 10 "HeaterTimerRecurrence_Sundays" 9 "HeaterTimerRecurrence_Saturdays" 8 "HeaterTimerRecurrence_Fridays" 7 "HeaterTimerRecurrence_Thursdays" 6 "HeaterTimerRecurrence_Wednesdays" 5 "HeaterTimerRecurrence_Tuesdays" 4 "HeaterTimerRecurrence_Mondays" 3 "HeaterTimerRecurrence_Weekends" 2 "HeaterTimerRecurrence_AllWeekdays" 1 "HeaterTimerRecurrence_Daily" 0 "HeaterTimerRecurrence_None" ;
VAL_ 2499765032 PHTimerGUIEvCmd_Timer3Recur_ISig 15 "HeaterTimerRecurrence_NotAvailable" 14 "HeaterTimerRecurrence_Error" 13 "HeaterTimerRecurrence_Spare_3" 12 "HeaterTimerRecurrence_Spare_2" 11 "HeaterTimerRecurrence_Spare_1" 10 "HeaterTimerRecurrence_Sundays" 9 "HeaterTimerRecurrence_Saturdays" 8 "HeaterTimerRecurrence_Fridays" 7 "HeaterTimerRecurrence_Thursdays" 6 "HeaterTimerRecurrence_Wednesdays" 5 "HeaterTimerRecurrence_Tuesdays" 4 "HeaterTimerRecurrence_Mondays" 3 "HeaterTimerRecurrence_Weekends" 2 "HeaterTimerRecurrence_AllWeekdays" 1 "HeaterTimerRecurrence_Daily" 0 "HeaterTimerRecurrence_None" ;
VAL_ 2499765032 PHTimerGUIEvCmd_PhTimer1_cmd_ISi 7 "PhTimer_cmd_NotAvailable" 6 "PhTimer_cmd_Error" 5 "PhTimer_cmd_Spare_02" 4 "PhTimer_cmd_Spare_01" 3 "PhTimer_cmd_TimerDeleted" 2 "PhTimer_cmd_TimerDisable" 1 "PhTimer_cmd_TimerEnable" 0 "PhTimer_cmd_NoAction" ;
VAL_ 2499765032 PHTimerGUIEvCmd_Timer3StartDay_I 15 "HeaterTimerStartDay_NotAvailable" 14 "HeaterTimerStartDay_Error" 13 "HeaterTimerStartDay_Spare_05" 12 "HeaterTimerStartDay_Spare_04" 11 "HeaterTimerStartDay_Spare_03" 10 "HeaterTimerStartDay_Spare_02" 9 "HeaterTimerStartDay_Spare_01" 8 "HeaterTimerStartDay_Spare" 7 "HeaterTimerStartDay_Sunday" 6 "HeaterTimerStartDay_Saturday" 5 "HeaterTimerStartDay_Friday" 4 "HeaterTimerStartDay_Thursday" 3 "HeaterTimerStartDay_Wednesday" 2 "HeaterTimerStartDay_Tuesday" 1 "HeaterTimerStartDay_Monday" 0 "HeaterTimerStartDay_NotUsed" ;
VAL_ 2499765032 PHTimerGUIEvCmd_Timer2Recur_ISig 15 "HeaterTimerRecurrence_NotAvailable" 14 "HeaterTimerRecurrence_Error" 13 "HeaterTimerRecurrence_Spare_3" 12 "HeaterTimerRecurrence_Spare_2" 11 "HeaterTimerRecurrence_Spare_1" 10 "HeaterTimerRecurrence_Sundays" 9 "HeaterTimerRecurrence_Saturdays" 8 "HeaterTimerRecurrence_Fridays" 7 "HeaterTimerRecurrence_Thursdays" 6 "HeaterTimerRecurrence_Wednesdays" 5 "HeaterTimerRecurrence_Tuesdays" 4 "HeaterTimerRecurrence_Mondays" 3 "HeaterTimerRecurrence_Weekends" 2 "HeaterTimerRecurrence_AllWeekdays" 1 "HeaterTimerRecurrence_Daily" 0 "HeaterTimerRecurrence_None" ;
VAL_ 2499765032 PHTimerGUIEvCmd_Timer2StartDay_I 15 "HeaterTimerStartDay_NotAvailable" 14 "HeaterTimerStartDay_Error" 13 "HeaterTimerStartDay_Spare_05" 12 "HeaterTimerStartDay_Spare_04" 11 "HeaterTimerStartDay_Spare_03" 10 "HeaterTimerStartDay_Spare_02" 9 "HeaterTimerStartDay_Spare_01" 8 "HeaterTimerStartDay_Spare" 7 "HeaterTimerStartDay_Sunday" 6 "HeaterTimerStartDay_Saturday" 5 "HeaterTimerStartDay_Friday" 4 "HeaterTimerStartDay_Thursday" 3 "HeaterTimerStartDay_Wednesday" 2 "HeaterTimerStartDay_Tuesday" 1 "HeaterTimerStartDay_Monday" 0 "HeaterTimerStartDay_NotUsed" ;
VAL_ 2499765032 PHTimerGUIEvCmd_Timer3Temp_ISig_ 31 "TemperatureRqstIndication_cmd_NotAvailable" 30 "TemperatureRqstIndication_cmd_Error" 29 "TemperatureRqstIndication_cmd_Spare_01" 28 "TemperatureRqstIndication_cmd_Spare" 27 "TemperatureRqstIndication_cmd_Max" 26 "TemperatureRqstIndication_cmd_29C" 25 "TemperatureRqstIndication_cmd_28C" 24 "TemperatureRqstIndication_cmd_27C" 23 "TemperatureRqstIndication_cmd_26C" 22 "TemperatureRqstIndication_cmd_25_5C" 21 "TemperatureRqstIndication_cmd_25C" 20 "TemperatureRqstIndication_cmd_24_5C" 19 "TemperatureRqstIndication_cmd_24C" 18 "TemperatureRqstIndication_cmd_23_5C" 17 "TemperatureRqstIndication_cmd_23C" 16 "TemperatureRqstIndication_cmd_22_5C" 15 "TemperatureRqstIndication_cmd_22C" 14 "TemperatureRqstIndication_cmd_21_5C" 13 "TemperatureRqstIndication_cmd_21C" 12 "TemperatureRqstIndication_cmd_20_5C" 11 "TemperatureRqstIndication_cmd_20C" 10 "TemperatureRqstIndication_cmd_19_5C" 9 "TemperatureRqstIndication_cmd_19C" 8 "TemperatureRqstIndication_cmd_18_5C" 7 "TemperatureRqstIndication_cmd_18C" 6 "TemperatureRqstIndication_cmd_17_5C" 5 "TemperatureRqstIndication_cmd_17C" 4 "TemperatureRqstIndication_cmd_16_5C" 3 "TemperatureRqstIndication_cmd_16C" 2 "TemperatureRqstIndication_cmd_15C" 1 "TemperatureRqstIndication_cmd_Min" 0 "TemperatureRqstIndication_cmd_NoTempDisplayed" ;
VAL_ 2499765032 PHTimerGUIEvCmd_Timer1Temp_ISig_ 31 "TemperatureRqstIndication_cmd_NotAvailable" 30 "TemperatureRqstIndication_cmd_Error" 29 "TemperatureRqstIndication_cmd_Spare_01" 28 "TemperatureRqstIndication_cmd_Spare" 27 "TemperatureRqstIndication_cmd_Max" 26 "TemperatureRqstIndication_cmd_29C" 25 "TemperatureRqstIndication_cmd_28C" 24 "TemperatureRqstIndication_cmd_27C" 23 "TemperatureRqstIndication_cmd_26C" 22 "TemperatureRqstIndication_cmd_25_5C" 21 "TemperatureRqstIndication_cmd_25C" 20 "TemperatureRqstIndication_cmd_24_5C" 19 "TemperatureRqstIndication_cmd_24C" 18 "TemperatureRqstIndication_cmd_23_5C" 17 "TemperatureRqstIndication_cmd_23C" 16 "TemperatureRqstIndication_cmd_22_5C" 15 "TemperatureRqstIndication_cmd_22C" 14 "TemperatureRqstIndication_cmd_21_5C" 13 "TemperatureRqstIndication_cmd_21C" 12 "TemperatureRqstIndication_cmd_20_5C" 11 "TemperatureRqstIndication_cmd_20C" 10 "TemperatureRqstIndication_cmd_19_5C" 9 "TemperatureRqstIndication_cmd_19C" 8 "TemperatureRqstIndication_cmd_18_5C" 7 "TemperatureRqstIndication_cmd_18C" 6 "TemperatureRqstIndication_cmd_17_5C" 5 "TemperatureRqstIndication_cmd_17C" 4 "TemperatureRqstIndication_cmd_16_5C" 3 "TemperatureRqstIndication_cmd_16C" 2 "TemperatureRqstIndication_cmd_15C" 1 "TemperatureRqstIndication_cmd_Min" 0 "TemperatureRqstIndication_cmd_NoTempDisplayed" ;
VAL_ 2499765032 PHTimerGUIEvCmd_Timer1StartDay_I 15 "HeaterTimerStartDay_NotAvailable" 14 "HeaterTimerStartDay_Error" 13 "HeaterTimerStartDay_Spare_05" 12 "HeaterTimerStartDay_Spare_04" 11 "HeaterTimerStartDay_Spare_03" 10 "HeaterTimerStartDay_Spare_02" 9 "HeaterTimerStartDay_Spare_01" 8 "HeaterTimerStartDay_Spare" 7 "HeaterTimerStartDay_Sunday" 6 "HeaterTimerStartDay_Saturday" 5 "HeaterTimerStartDay_Friday" 4 "HeaterTimerStartDay_Thursday" 3 "HeaterTimerStartDay_Wednesday" 2 "HeaterTimerStartDay_Tuesday" 1 "HeaterTimerStartDay_Monday" 0 "HeaterTimerStartDay_NotUsed" ;
VAL_ 2499765032 PHTimerGUIEvCmd_PhTimer3_cmd_ISi 7 "PhTimer_cmd_NotAvailable" 6 "PhTimer_cmd_Error" 5 "PhTimer_cmd_Spare_02" 4 "PhTimer_cmd_Spare_01" 3 "PhTimer_cmd_TimerDeleted" 2 "PhTimer_cmd_TimerDisable" 1 "PhTimer_cmd_TimerEnable" 0 "PhTimer_cmd_NoAction" ;
VAL_ 2499765032 PHTimerGUIEvCmd_PhTimer2_cmd_ISi 7 "PhTimer_cmd_NotAvailable" 6 "PhTimer_cmd_Error" 5 "PhTimer_cmd_Spare_02" 4 "PhTimer_cmd_Spare_01" 3 "PhTimer_cmd_TimerDeleted" 2 "PhTimer_cmd_TimerDisable" 1 "PhTimer_cmd_TimerEnable" 0 "PhTimer_cmd_NoAction" ;
VAL_ 2499743273 EngTimerGUIEvCmd_EhTimer3_cmd_IS 7 "PhTimer_cmd_NotAvailable" 6 "PhTimer_cmd_Error" 5 "PhTimer_cmd_Spare_02" 4 "PhTimer_cmd_Spare_01" 3 "PhTimer_cmd_TimerDeleted" 2 "PhTimer_cmd_TimerDisable" 1 "PhTimer_cmd_TimerEnable" 0 "PhTimer_cmd_NoAction" ;
VAL_ 2499743273 EngTimerGUIEvCmd_Timer3StartDay_ 15 "HeaterTimerStartDay_NotAvailable" 14 "HeaterTimerStartDay_Error" 13 "HeaterTimerStartDay_Spare_05" 12 "HeaterTimerStartDay_Spare_04" 11 "HeaterTimerStartDay_Spare_03" 10 "HeaterTimerStartDay_Spare_02" 9 "HeaterTimerStartDay_Spare_01" 8 "HeaterTimerStartDay_Spare" 7 "HeaterTimerStartDay_Sunday" 6 "HeaterTimerStartDay_Saturday" 5 "HeaterTimerStartDay_Friday" 4 "HeaterTimerStartDay_Thursday" 3 "HeaterTimerStartDay_Wednesday" 2 "HeaterTimerStartDay_Tuesday" 1 "HeaterTimerStartDay_Monday" 0 "HeaterTimerStartDay_NotUsed" ;
VAL_ 2499743273 EngTimerGUIEvCmd_Timer2Recur_ISi 15 "HeaterTimerRecurrence_NotAvailable" 14 "HeaterTimerRecurrence_Error" 13 "HeaterTimerRecurrence_Spare_3" 12 "HeaterTimerRecurrence_Spare_2" 11 "HeaterTimerRecurrence_Spare_1" 10 "HeaterTimerRecurrence_Sundays" 9 "HeaterTimerRecurrence_Saturdays" 8 "HeaterTimerRecurrence_Fridays" 7 "HeaterTimerRecurrence_Thursdays" 6 "HeaterTimerRecurrence_Wednesdays" 5 "HeaterTimerRecurrence_Tuesdays" 4 "HeaterTimerRecurrence_Mondays" 3 "HeaterTimerRecurrence_Weekends" 2 "HeaterTimerRecurrence_AllWeekdays" 1 "HeaterTimerRecurrence_Daily" 0 "HeaterTimerRecurrence_None" ;
VAL_ 2499743273 EngTimerGUIEvCmd_Timer3Recur_ISi 15 "HeaterTimerRecurrence_NotAvailable" 14 "HeaterTimerRecurrence_Error" 13 "HeaterTimerRecurrence_Spare_3" 12 "HeaterTimerRecurrence_Spare_2" 11 "HeaterTimerRecurrence_Spare_1" 10 "HeaterTimerRecurrence_Sundays" 9 "HeaterTimerRecurrence_Saturdays" 8 "HeaterTimerRecurrence_Fridays" 7 "HeaterTimerRecurrence_Thursdays" 6 "HeaterTimerRecurrence_Wednesdays" 5 "HeaterTimerRecurrence_Tuesdays" 4 "HeaterTimerRecurrence_Mondays" 3 "HeaterTimerRecurrence_Weekends" 2 "HeaterTimerRecurrence_AllWeekdays" 1 "HeaterTimerRecurrence_Daily" 0 "HeaterTimerRecurrence_None" ;
VAL_ 2499743273 EngTimerGUIEvCmd_Timer1StartDay_ 15 "HeaterTimerStartDay_NotAvailable" 14 "HeaterTimerStartDay_Error" 13 "HeaterTimerStartDay_Spare_05" 12 "HeaterTimerStartDay_Spare_04" 11 "HeaterTimerStartDay_Spare_03" 10 "HeaterTimerStartDay_Spare_02" 9 "HeaterTimerStartDay_Spare_01" 8 "HeaterTimerStartDay_Spare" 7 "HeaterTimerStartDay_Sunday" 6 "HeaterTimerStartDay_Saturday" 5 "HeaterTimerStartDay_Friday" 4 "HeaterTimerStartDay_Thursday" 3 "HeaterTimerStartDay_Wednesday" 2 "HeaterTimerStartDay_Tuesday" 1 "HeaterTimerStartDay_Monday" 0 "HeaterTimerStartDay_NotUsed" ;
VAL_ 2499743273 EngTimerGUIEvCmd_Timer2StartDay_ 15 "HeaterTimerStartDay_NotAvailable" 14 "HeaterTimerStartDay_Error" 13 "HeaterTimerStartDay_Spare_05" 12 "HeaterTimerStartDay_Spare_04" 11 "HeaterTimerStartDay_Spare_03" 10 "HeaterTimerStartDay_Spare_02" 9 "HeaterTimerStartDay_Spare_01" 8 "HeaterTimerStartDay_Spare" 7 "HeaterTimerStartDay_Sunday" 6 "HeaterTimerStartDay_Saturday" 5 "HeaterTimerStartDay_Friday" 4 "HeaterTimerStartDay_Thursday" 3 "HeaterTimerStartDay_Wednesday" 2 "HeaterTimerStartDay_Tuesday" 1 "HeaterTimerStartDay_Monday" 0 "HeaterTimerStartDay_NotUsed" ;
VAL_ 2499743273 EngTimerGUIEvCmd_EhTimer2_cmd_IS 7 "PhTimer_cmd_NotAvailable" 6 "PhTimer_cmd_Error" 5 "PhTimer_cmd_Spare_02" 4 "PhTimer_cmd_Spare_01" 3 "PhTimer_cmd_TimerDeleted" 2 "PhTimer_cmd_TimerDisable" 1 "PhTimer_cmd_TimerEnable" 0 "PhTimer_cmd_NoAction" ;
VAL_ 2499743273 EngTimerGUIEvCmd_Timer1Recur_ISi 15 "HeaterTimerRecurrence_NotAvailable" 14 "HeaterTimerRecurrence_Error" 13 "HeaterTimerRecurrence_Spare_3" 12 "HeaterTimerRecurrence_Spare_2" 11 "HeaterTimerRecurrence_Spare_1" 10 "HeaterTimerRecurrence_Sundays" 9 "HeaterTimerRecurrence_Saturdays" 8 "HeaterTimerRecurrence_Fridays" 7 "HeaterTimerRecurrence_Thursdays" 6 "HeaterTimerRecurrence_Wednesdays" 5 "HeaterTimerRecurrence_Tuesdays" 4 "HeaterTimerRecurrence_Mondays" 3 "HeaterTimerRecurrence_Weekends" 2 "HeaterTimerRecurrence_AllWeekdays" 1 "HeaterTimerRecurrence_Daily" 0 "HeaterTimerRecurrence_None" ;
VAL_ 2499743273 EngTimerGUIEvCmd_EhTimer1_cmd_IS 7 "PhTimer_cmd_NotAvailable" 6 "PhTimer_cmd_Error" 5 "PhTimer_cmd_Spare_02" 4 "PhTimer_cmd_Spare_01" 3 "PhTimer_cmd_TimerDeleted" 2 "PhTimer_cmd_TimerDisable" 1 "PhTimer_cmd_TimerEnable" 0 "PhTimer_cmd_NoAction" ;
VAL_ 2466245055 ASLDriverRequest 15 "ASLDriverRequest_NotAvailable" 14 "ASLDriverRequest_Error" 13 "ASLDriverRequest_Spare_06" 12 "ASLDriverRequest_Spare_05" 11 "ASLDriverRequest_Spare_04" 10 "ASLDriverRequest_Spare_03" 9 "ASLDriverRequest_Spare_02" 8 "ASLDriverRequest_Spare_01" 7 "ASLDriverRequest_Spare" 6 "ASLDriverRequest_SetPresetSpeed" 5 "ASLDriverRequest_Pause" 4 "ASLDriverRequest_Decrease" 3 "ASLDriverRequest_Increase" 2 "ASLDriverRequest_ResumePreviousSpeed" 1 "ASLDriverRequest_SetCurrentSpeed" 0 "ASLDriverRequest_NoRequest" ;
VAL_ 2466245055 ASLEnableRequest 3 "OffOn_NotAvailable" 2 "OffOn_Error" 1 "OffOn_On" 0 "OffOn_Off" ;
VAL_ 2466245055 CCEnableRequest_ISig_4 3 "DisableEnable_NotAvailable" 2 "DisableEnable_Error" 1 "DisableEnable_Enable" 0 "DisableEnable_Disable" ;
VAL_ 2466245055 CCDriverRequest 15 "CCDriverRequest_NotAvailable" 14 "CCDriverRequest_Error" 13 "CCDriverRequest_Spare_06" 12 "CCDriverRequest_Spare_05" 11 "CCDriverRequest_Spare_04" 10 "CCDriverRequest_Spare_03" 9 "CCDriverRequest_Spare_02" 8 "CCDriverRequest_Spare_01" 7 "CCDriverRequest_Spare" 6 "CCDriverRequest_SetPresetSpeed" 5 "CCDriverRequest_Pause" 4 "CCDriverRequest_Decrease" 3 "CCDriverRequest_Increase" 2 "CCDriverRequest_ResumePreviousSpeed" 1 "CCDriverRequest_SetCurrentSpeed" 0 "CCDriverRequest_NoRequest" ;
VAL_ 2466245055 RainsensorActivateRqst 3 "RainsensorActivateRqst_NotAvailable" 2 "RainsensorActivateRqst_Neutral" 1 "RainsensorActivateRqst_Activated" 0 "RainsensorActivateRqst_Deactivated" ;
VAL_ 2365538239 Rainsensor_ButtonStatus 3 "PushButtonStatus_NotAvailable" 2 "PushButtonStatus_Error" 1 "PushButtonStatus_Pushed" 0 "PushButtonStatus_Neutral" ;
VAL_ 2365538239 Traction_DualDeviceIndication 15 "DualDeviceIndication_UpperDontCareLowerDontCare" 14 "DualDeviceIndication_UpperBlinkLowerDontCare" 13 "DualDeviceIndication_UpperOnLowerDontCare" 12 "DualDeviceIndication_UpperOffLowerDontCare" 11 "DualDeviceIndication_UpperDontCareLowerBlink" 10 "DualDeviceIndication_UpperBlinkLowerBlink" 9 "DualDeviceIndication_UpperOnLowerBlink" 8 "DualDeviceIndication_UpperOffLowerBlink" 7 "DualDeviceIndication_UpperDontCareLowerOn" 6 "DualDeviceIndication_UpperBlinkLowerOn" 5 "DualDeviceIndication_UpperOnLowerOn" 4 "DualDeviceIndication_UpperOffLowerOn" 3 "DualDeviceIndication_UpperDontCareLowerOff" 2 "DualDeviceIndication_UpperBlinkLowerOff" 1 "DualDeviceIndication_UpperOnLowerOff" 0 "DualDeviceIndication_UpperOffLowerOff" ;
VAL_ 2365538239 WiperStalkStat_1 7 "WiperStalkStat_NotAvailable" 6 "WiperStalkStat_Error" 5 "WiperStalkStat_SpareValue" 4 "WiperStalkStat_FastPosition" 3 "WiperStalkStat_NormalPosition" 2 "WiperStalkStat_IntermittentPosition" 1 "WiperStalkStat_SingleWipePosition" 0 "WiperStalkStat_IdleRainsensorPosition" ;
VAL_ 2365538239 RequestForHighestGearRatio 3 "Request_NotAvailable" 2 "Request_Error" 1 "Request_RequestActive" 0 "Request_NotRequested" ;
VAL_ 2365538239 RequestedUpshiftDownshiftSteps 7 "RequestedUpshiftDownshiftSteps_NotAvailable" 6 "RequestedUpshiftDownshiftSteps_Error" 5 "RequestedUpshiftDownshiftSteps_NotDefined_01" 4 "RequestedUpshiftDownshiftSteps_NotDefined" 3 "RequestedUpshiftDownshiftSteps_ThreeSteps" 2 "RequestedUpshiftDownshiftSteps_TwoSteps" 1 "RequestedUpshiftDownshiftSteps_OneStep" 0 "RequestedUpshiftDownshiftSteps_NoRequest" ;
VAL_ 2365538239 WiperAdjustStatus_1 7 "WiperAdjustStatus_NotAvailable" 6 "WiperAdjustStatus_Error" 5 "WiperAdjustStatus_Spare_01" 4 "WiperAdjustStatus_Spare" 3 "WiperAdjustStatus_WiperAdjust3" 2 "WiperAdjustStatus_WiperAdjust2" 1 "WiperAdjustStatus_WiperAdjust1" 0 "WiperAdjustStatus_WiperAdjust0" ;
VAL_ 2365538239 UpShiftRequest 3 "UpShiftRequest_NotAvailable" 2 "UpShiftRequest_Error" 1 "UpShiftRequest_RequestToDoUpshiftOneStep" 0 "UpShiftRequest_NoRequest" ;
VAL_ 2365538239 MainBeam_StalkStatus_1 7 "MainBeam_StalkStatus_NotAvailable" 6 "MainBeam_StalkStatus_Error" 5 "MainBeam_StalkStatus_Spare_02" 4 "MainBeam_StalkStatus_Spare_01" 3 "MainBeam_StalkStatus_Spare" 2 "MainBeam_StalkStatus_ToggleMainBeam" 1 "MainBeam_StalkStatus_FlashToPass" 0 "MainBeam_StalkStatus_NeutralRestingPosition" ;
VAL_ 2365538239 DirInd_StalkStatus_1 7 "DirInd_StalkStatus_NotAvailable" 6 "DirInd_StalkStatus_Error" 5 "DirInd_StalkStatus_Spare" 4 "DirInd_StalkStatus_RightTemporaryTurningIndication" 3 "DirInd_StalkStatus_LeftTemporaryTurningIndication" 2 "DirInd_StalkStatus_RightTurningIndication" 1 "DirInd_StalkStatus_LeftTurningIndication" 0 "DirInd_StalkStatus_NeutralRestingPositon" ;
VAL_ 2365538239 LimpHomeSwitch_stat 3 "OffOn_NotAvailable" 2 "OffOn_Error" 1 "OffOn_On" 0 "OffOn_Off" ;
VAL_ 2365538239 Washing_Status_2 3 "A2PosSwitchStatus_NotAvailable" 2 "A2PosSwitchStatus_Error" 1 "A2PosSwitchStatus_On" 0 "A2PosSwitchStatus_Off" ;
VAL_ 2365538239 EconomyPowerSwitch_stat 3 "OffOn_NotAvailable" 2 "OffOn_Error" 1 "OffOn_On" 0 "OffOn_Off" ;
VAL_ 2365538239 GearLeverPosition_ISig_4 15 "GearLeverPosition_NotAvailable" 14 "GearLeverPosition_Error" 13 "GearLeverPosition_SpareValue_06" 12 "GearLeverPosition_SpareValue_05" 11 "GearLeverPosition_SpareValue_04" 10 "GearLeverPosition_SpareValue_03" 9 "GearLeverPosition_SpareValue_02" 8 "GearLeverPosition_SpareValue_01" 7 "GearLeverPosition_SpareValue" 6 "GearLeverPosition_SEG6" 5 "GearLeverPosition_LowGear" 4 "GearLeverPosition_Manual" 3 "GearLeverPosition_Automatic" 2 "GearLeverPosition_Neutral" 1 "GearLeverPosition_Reverse" 0 "GearLeverPosition_GearFoldedAway" ;
VAL_ 2365538239 DownShiftRequest 3 "DownShiftRequest_NotAvailable" 2 "DownShiftRequest_Error" 1 "DownShiftRequest_RequestToDownshiftOneGear" 0 "DownShiftRequest_NoRequest" ;
VAL_ 2365538239 MainBeam_StalkStatus_2 7 "MainBeam_StalkStatus_NotAvailable" 6 "MainBeam_StalkStatus_Error" 5 "MainBeam_StalkStatus_Spare_02" 4 "MainBeam_StalkStatus_Spare_01" 3 "MainBeam_StalkStatus_Spare" 2 "MainBeam_StalkStatus_ToggleMainBeam" 1 "MainBeam_StalkStatus_FlashToPass" 0 "MainBeam_StalkStatus_NeutralRestingPosition" ;
VAL_ 2365538239 DirInd_StalkStatus_2 7 "DirInd_StalkStatus_NotAvailable" 6 "DirInd_StalkStatus_Error" 5 "DirInd_StalkStatus_Spare" 4 "DirInd_StalkStatus_RightTemporaryTurningIndication" 3 "DirInd_StalkStatus_LeftTemporaryTurningIndication" 2 "DirInd_StalkStatus_RightTurningIndication" 1 "DirInd_StalkStatus_LeftTurningIndication" 0 "DirInd_StalkStatus_NeutralRestingPositon" ;
VAL_ 2365538239 RetarderStalkPosition_1 15 "RetarderStalkPosition_NotAvailable" 14 "RetarderStalkPosition_Error" 13 "RetarderStalkPosition_Spare05" 12 "RetarderStalkPosition_Spare04" 11 "RetarderStalkPosition_Spare03" 10 "RetarderStalkPosition_Spare02" 9 "RetarderStalkPosition_Spare01" 8 "RetarderStalkPosition_Spare" 7 "RetarderStalkPosition_PositionAAuto" 6 "RetarderStalkPosition_PositionBBrakeProgram" 5 "RetarderStalkPosition_Position5" 4 "RetarderStalkPosition_Position4" 3 "RetarderStalkPosition_Position3" 2 "RetarderStalkPosition_Position2" 1 "RetarderStalkPosition_Position1" 0 "RetarderStalkPosition_Position0Inactive" ;
VAL_ 2365538239 RetarderStalkPosition_2 15 "RetarderStalkPosition_NotAvailable" 14 "RetarderStalkPosition_Error" 13 "RetarderStalkPosition_Spare05" 12 "RetarderStalkPosition_Spare04" 11 "RetarderStalkPosition_Spare03" 10 "RetarderStalkPosition_Spare02" 9 "RetarderStalkPosition_Spare01" 8 "RetarderStalkPosition_Spare" 7 "RetarderStalkPosition_PositionAAuto" 6 "RetarderStalkPosition_PositionBBrakeProgram" 5 "RetarderStalkPosition_Position5" 4 "RetarderStalkPosition_Position4" 3 "RetarderStalkPosition_Position3" 2 "RetarderStalkPosition_Position2" 1 "RetarderStalkPosition_Position1" 0 "RetarderStalkPosition_Position0Inactive" ;
VAL_ 2365538239 EcoRollEnableRequest_ISig_4 3 "InactiveActive_NotAvailable" 2 "InactiveActive_Error" 1 "InactiveActive_Active" 0 "InactiveActive_Inactive" ;
VAL_ 2365538239 Washing_Status_1 3 "A2PosSwitchStatus_NotAvailable" 2 "A2PosSwitchStatus_Error" 1 "A2PosSwitchStatus_On" 0 "A2PosSwitchStatus_Off" ;
VAL_ 2365538239 SelectedEcoCruiseLevel_ISig_4 7 "SelectedEcoCruiseLevel_NotAvailable" 6 "SelectedEcoCruiseLevel_Error" 5 "SelectedEcoCruiseLevel_Spare01" 4 "SelectedEcoCruiseLevel_Spare" 3 "SelectedEcoCruiseLevel_Level3" 2 "SelectedEcoCruiseLevel_Level2" 1 "SelectedEcoCruiseLevel_Level1" 0 "SelectedEcoCruiseLevel_Off" ;
VAL_ 2365538239 WiperStalkStat_2 7 "WiperStalkStat_NotAvailable" 6 "WiperStalkStat_Error" 5 "WiperStalkStat_SpareValue" 4 "WiperStalkStat_FastPosition" 3 "WiperStalkStat_NormalPosition" 2 "WiperStalkStat_IntermittentPosition" 1 "WiperStalkStat_SingleWipePosition" 0 "WiperStalkStat_IdleRainsensorPosition" ;
VAL_ 2432634208 IdleAdjustDeactivationRequest 3 "GUIEventCmd_NotAvailable" 2 "GUIEventCmd_Error" 1 "GUIEventCmd_Activated" 0 "GUIEventCmd_Neutral" ;
VAL_ 2432634208 ACMode_Selection_ISig_4 7 "ACMode_NotAvailable" 6 "ACMode_Error" 5 "ACMode_Spare_01" 4 "ACMode_Spare" 3 "ACMode_ExtraDryCabAir" 2 "ACMode_HumidCabAir" 1 "ACMode_Standard" 0 "ACMode_Economy" ;
VAL_ 2432634208 TripmeterReset_rqst_ISig_4 7 "TripmeterReset_rqst_NotAvailable" 6 "TripmeterReset_rqst_ErrorIndicator" 5 "TripmeterReset_rqst_SpareValue_02" 4 "TripmeterReset_rqst_SpareValue_01" 3 "TripmeterReset_rqst_SpareValue" 2 "TripmeterReset_rqst_Inactive" 1 "TripmeterReset_rqst_Tripcounter2Reset" 0 "TripmeterReset_rqst_Tripcounter1Reset" ;
VAL_ 2432634208 WaterInFuelDrainRequest 3 "Request_NotAvailable" 2 "Request_Error" 1 "Request_RequestActive" 0 "Request_NotRequested" ;
VAL_ 2432634208 FuncIndIlluminationLevel_ISig_4 7 "FuncIndIlluminationLevel_NotAvailable" 6 "FuncIndIlluminationLevel_Error" 5 "FuncIndIlluminationLevel_Spare" 4 "FuncIndIlluminationLevel_IlluminationLevel4" 3 "FuncIndIlluminationLevel_IlluminationLevel3" 2 "FuncIndIlluminationLevel_IlluminationLevel2" 1 "FuncIndIlluminationLevel_IlluminationLevel1" 0 "FuncIndIlluminationLevel_IlluminationOff" ;
VAL_ 2432634208 IdleAdjustActivationRequest 3 "GUIEventCmd_NotAvailable" 2 "GUIEventCmd_Error" 1 "GUIEventCmd_Activated" 0 "GUIEventCmd_Neutral" ;
VAL_ 2432634208 AutoDefogmode_Selection_ISig_4 7 "AutoDefogmode_NotAvailable" 6 "AutoDefogmode_Error" 5 "AutoDefogmode_Spare_01" 4 "AutoDefogmode_Spare" 3 "AutoDefogmode_Moderate" 2 "AutoDefogmode_Normal" 1 "AutoDefogmode_Sensitive" 0 "AutoDefogmode_OFF" ;
VAL_ 2432634208 ResumeRequestForACC_ISig_4 3 "OffOn_NotAvailable" 2 "OffOn_Error" 1 "OffOn_On" 0 "OffOn_Off" ;
VAL_ 2432634208 AudioMuteStat_ISig_4 7 "AudioMute_NotAvailable" 6 "AudioMute_ErrorIndication" 5 "AudioMute_Spare_03" 4 "AudioMute_Spare_02" 3 "AudioMute_Spare_01" 2 "AudioMute_Spare" 1 "AudioMute_Mute" 0 "AudioMute_Off" ;
VAL_ 2432634208 IdleAdjustTrimGuiEventCmd 7 "IdleAdjustTrimGuiEventCmd_NotAvailabe" 6 "IdleAdjustTrimGuiEventCmd_Error" 2 "IdleAdjustTrimGuiEventCmd_TrimDown" 1 "IdleAdjustTrimGuiEventCmd_TrimUp" 0 "IdleAdjustTrimGuiEventCmd_NoRequest" ;
VAL_ 2432634208 IdleAdjustStoreRequest 3 "GUIEventCmd_NotAvailable" 2 "GUIEventCmd_Error" 1 "GUIEventCmd_Activated" 0 "GUIEventCmd_Neutral" ;
VAL_ 2432634208 SWSpeedControlAdjustMode 15 "SWSpeedControlAdjustMode_NotAvailable" 14 "SWSpeedControlAdjustMode_Error" 13 "SWSpeedControlAdjustMode_Spare_10" 12 "SWSpeedControlAdjustMode_Spare_09" 11 "SWSpeedControlAdjustMode_Spare_08" 10 "SWSpeedControlAdjustMode_Spare_07" 9 "SWSpeedControlAdjustMode_Spare_06" 8 "SWSpeedControlAdjustMode_Spare_05" 7 "SWSpeedControlAdjustMode_Spare_04" 6 "SWSpeedControlAdjustMode_Spare_03" 5 "SWSpeedControlAdjustMode_Spare_02" 4 "SWSpeedControlAdjustMode_Spare_01" 3 "SWSpeedControlAdjustMode_Spare" 2 "SWSpeedControlAdjustMode_AdjustTimeGap" 1 "SWSpeedControlAdjustMode_AdjustOverspeed" 0 "SWSpeedControlAdjustMode_AdjustSpeed" ;
VAL_ 2432634208 ACCTimeGapRqst_ISig_4 7 "ACCTimeGapRqst_Unavailable" 6 "ACCTimeGapRqst_Error" 5 "ACCTimeGapRqst_Spare" 4 "ACCTimeGapRqst_Set5" 3 "ACCTimeGapRqst_Set4" 2 "ACCTimeGapRqst_Set3" 1 "ACCTimeGapRqst_Set2" 0 "ACCTimeGapRqst_Set1" ;
VAL_ 2432634208 AQSMode_Selection_ISig_4 3 "AQSMode_NotAvailable" 2 "AQSMode_Error" 1 "AQSMode_Auto" 0 "AQSMode_OFF" ;
VAL_ 2432634208 ACCEnableRqst_ISig_4 3 "DisableEnable_NotAvailable" 2 "DisableEnable_Error" 1 "DisableEnable_Enable" 0 "DisableEnable_Disable" ;
VAL_ 2432634208 StopAlert_cmd_ISig_4 7 "Telltale_cmd_NotAvailable" 6 "Telltale_cmd_ErrorIndication" 5 "Telltale_cmd_Spare_02" 4 "Telltale_cmd_Spare_01" 3 "Telltale_cmd_Spare" 2 "Telltale_cmd_Flashing" 1 "Telltale_cmd_OnSteady" 0 "Telltale_cmd_Off" ;
VAL_ 2432634208 BacklightCmd_ISig_4 31 "BacklightCmd_NotAvailable" 30 "BacklightCmd_Error" 16 "BacklightCmd_BacklightLevel16" 15 "BacklightCmd_BacklightLevel15" 14 "BacklightCmd_BacklightLevel14" 13 "BacklightCmd_BacklightLevel13" 12 "BacklightCmd_BacklightLevel12" 11 "BacklightCmd_BacklightLevel11" 10 "BacklightCmd_BacklightLevel10" 9 "BacklightCmd_BacklightLevel9" 8 "BacklightCmd_BacklightLevel8" 7 "BacklightCmd_BacklightLevel7" 6 "BacklightCmd_BacklightLevel6" 5 "BacklightCmd_BacklightLevel5" 4 "BacklightCmd_BacklightLevel4" 3 "BacklightCmd_BacklightLevel3" 2 "BacklightCmd_BacklightLevel2" 1 "BacklightCmd_BacklightLevel1" 0 "BacklightCmd_BacklightOff" ;
VAL_ 2432634208 AutoBlowerLevel_Selection_ISig_4 7 "AutoBlowerLevel_NotAvailable" 6 "AutoBlowerLevel_Error" 5 "AutoBlowerLevel_Spare_02" 4 "AutoBlowerLevel_Spare_01" 3 "AutoBlowerLevel_Spare" 2 "AutoBlowerLevel_Low" 1 "AutoBlowerLevel_Normal" 0 "AutoBlowerLevel_High" ;
VAL_ 2432634208 CMTelltale_stat_ISig_4 7 "Telltale_cmd_NotAvailable" 6 "Telltale_cmd_ErrorIndication" 5 "Telltale_cmd_Spare_02" 4 "Telltale_cmd_Spare_01" 3 "Telltale_cmd_Spare" 2 "Telltale_cmd_Flashing" 1 "Telltale_cmd_OnSteady" 0 "Telltale_cmd_Off" ;
VAL_ 2432634208 SWSpdCtrlButtonsStatus1 15 "SWSpdCtrlButtonsStatus1_NotAvaillable" 14 "SWSpdCtrlButtonsStatus1_Error" 13 "SWSpdCtrlButtonsStatus1_Spare_03" 12 "SWSpdCtrlButtonsStatus1_Spare_02" 11 "SWSpdCtrlButtonsStatus1_Spare_01" 10 "SWSpdCtrlButtonsStatus1_Spare" 9 "SWSpdCtrlButtonsStatus1_TimeGap" 8 "SWSpdCtrlButtonsStatus1_ACC" 7 "SWSpdCtrlButtonsStatus1_Overspeed" 6 "SWSpdCtrlButtonsStatus1_CC" 5 "SWSpdCtrlButtonsStatus1_Enter" 4 "SWSpdCtrlButtonsStatus1_Decrease" 3 "SWSpdCtrlButtonsStatus1_Increase" 2 "SWSpdCtrlButtonsStatus1_Resume" 1 "SWSpdCtrlButtonsStatus1_PauseOff" 0 "SWSpdCtrlButtonsStatus1_None" ;
VAL_ 2549478672 EngineFuelMode_ISig_4 3 "FuelMode_NotAvailable" 2 "FuelMode_Error" 1 "FuelMode_RunOnDiesel" 0 "FuelMode_RunOnGas" ;
VAL_ 2549478672 LNGOperatorInducementReason 7 "LNGOperatorInducementReason_NotAvailable" 6 "LNGOperatorInducementReason_Error" 5 "LNGOperatorInducementReason_Spare2" 4 "LNGOperatorInducementReason_Spare1" 3 "LNGOperatorInducementReason_IncorrectConsumption" 2 "LNGOperatorInducementReason_GasSupplyMalfunction" 1 "LNGOperatorInducementReason_LNGLevelLow" 0 "LNGOperatorInducementReason_OK" ;
VAL_ 2549478672 DPF_RegenCompleted_ISig_4 7 "RegenCompleted_NotAvailable" 6 "RegenCompleted_Error" 5 "RegenCompleted_Spare3" 4 "RegenCompleted_Spare2" 3 "RegenCompleted_Spare1" 2 "RegenCompleted_Completed" 1 "RegenCompleted_NotCompleted" 0 "RegenCompleted_NoInformation" ;
VAL_ 2549478672 SCR_SulphurRegenNeeded_ISig_4 7 "RegenerationNeeded_NotAvailable" 6 "RegenerationNeeded_Spare3" 5 "RegenerationNeeded_Spare2" 4 "RegenerationNeeded_Spare1" 3 "RegenerationNeeded_HighNeed" 2 "RegenerationNeeded_ModerateNeed" 1 "RegenerationNeeded_LowNeed" 0 "RegenerationNeeded_NoNeed" ;
VAL_ 2566211344 MIStatus_ISig_4 3 "OffOn_NotAvailable" 2 "OffOn_Error" 1 "OffOn_On" 0 "OffOn_Off" ;
VAL_ 2566211344 AshLevelHigh 7 "AshLevelHigh_NotAvailable" 6 "AshLevelHigh_Error" 5 "AshLevelHigh_HighLevel5" 4 "AshLevelHigh_HighLevel4" 3 "AshLevelHigh_HighLevel3" 2 "AshLevelHigh_HighLevel2" 1 "AshLevelHigh_HighLevel1" 0 "AshLevelHigh_OK" ;
VAL_ 2566211344 TorqueReductionStatus_OBD_ISig_4 7 "TorqueReductionStatus_OBD_NotAvailable" 6 "TorqueReductionStatus_OBD_Error" 5 "TorqueReductionStatus_OBD_Spare_01" 4 "TorqueReductionStatus_OBD_Spare" 3 "TorqueReductionStatus_OBD_TorqueReductionActive" 2 "TorqueReductionStatus_OBD_TorqueReductionActiveNextStandstill" 1 "TorqueReductionStatus_OBD_Pending" 0 "TorqueReductionStatus_OBD_NotActive" ;
VAL_ 2566211344 SCROperatorInducementSeverity_IS 7 "SCROperatorInducementSeverity_NotAvailable" 6 "SCROperatorInducementSeverity_Reserved" 5 "SCROperatorInducementSeverity_SevereInducementActive" 4 "SCROperatorInducementSeverity_SevereIndEnabledWaitActCondition" 3 "SCROperatorInducementSeverity_IndLevel3LowLevelInducementActive" 2 "SCROperatorInducementSeverity_IndLevel2IntensiveWarning" 1 "SCROperatorInducementSeverity_IndLevel1InitialWarning" 0 "SCROperatorInducementSeverity_NoInducementActive" ;
VAL_ 2566211344 SCROperatorInducementReason_ISig 7 "SCROperatorInducementReason_NotAvailable" 6 "SCROperatorInducementReason_Error" 5 "SCROperatorInducementReason_Spare" 4 "SCROperatorInducementReason_Tampering" 3 "SCROperatorInducementReason_IncorrectConsumption" 2 "SCROperatorInducementReason_IncorrectQuality" 1 "SCROperatorInducementReason_ReagentLevelLow" 0 "SCROperatorInducementReason_OK" ;
VAL_ 2566211344 MIDistinctWarning_ISig_4 3 "OffOn_NotAvailable" 2 "OffOn_Error" 1 "OffOn_On" 0 "OffOn_Off" ;
VAL_ 2566211344 MIStatusExtEMS_ISig_4 3 "MIStatusExt_NotAvailable" 2 "MIStatusExt_Error" 1 "MIStatusExt_Ready" 0 "MIStatusExt_NotReady5Flash" ;
VAL_ 2566211344 MIDistinctWarningExtEMS_ISig_4 15 "MIDistinctWarningExt_NotAvailable" 14 "MIDistinctWarningExt_Error" 3 "MIDistinctWarningExt_ContinuousMISteady" 2 "MIDistinctWarningExt_ShortMI3Flash" 1 "MIDistinctWarningExt_OnDemandMI2Flash" 0 "MIDistinctWarningExt_Off1Flash" ;
VAL_ 2566356786 OilPrediction_Quality 7 "OilQuality_NotAvailable" 6 "OilQuality_Error" 5 "OilQuality_NoSelectionMade" 4 "OilQuality_VDS4" 3 "OilQuality_VDS3" 2 "OilQuality_VDS2" 1 "OilQuality_VDSVDS3WithFixedInterval" 0 "OilQuality_NonVDS_VDS4WithFixedInterval" ;
VAL_ 2566356786 OilPrediction_Status 7 "OilStatus_NotAvailable" 6 "OilStatus_Error" 5 "OilStatus_Spare" 4 "OilStatus_Ok" 3 "OilStatus_ServiceNearDue" 2 "OilStatus_ServiceDue" 1 "OilStatus_ServiceOverDue" 0 "OilStatus_NotActive" ;
VAL_ 2549445904 DMSDriverFollow 3 "DMSDriverFollow_NotAvailable" 2 "DMSDriverFollow_Error" 1 "DMSDriverFollow_AdviseFollowed" 0 "DMSDriverFollow_AdviseNotFollowed" ;
VAL_ 2549445904 FuelEcoEngStatus 3 "InactiveActive_NotAvailable" 2 "InactiveActive_Error" 1 "InactiveActive_Active" 0 "InactiveActive_Inactive" ;
VAL_ 2549579536 DrainPrimingStatus_ISig_4 7 "DrainPrimingStatus_NotAvailable" 6 "DrainPrimingStatus_Error" 5 "DrainPrimingStatus_SpareValue_01" 4 "DrainPrimingStatus_SpareValue" 3 "DrainPrimingStatus_DrainingActive" 2 "DrainPrimingStatus_PrimingActive" 1 "DrainPrimingStatus_DrainingPrimingNotAllowed" 0 "DrainPrimingStatus_DrainingPrimingInactive" ;
VAL_ 2549579536 CoolantTempHigh_ISig_4 7 "TempHigh3bit_NotAvailable" 6 "TempHigh3bit_Error" 5 "TempHigh3bit_HighLevel5" 4 "TempHigh3bit_HighLevel4" 3 "TempHigh3bit_HighLevel3" 2 "TempHigh3bit_HighLevel2" 1 "TempHigh3bit_HighLevel1" 0 "TempHigh3bit_OK" ;
VAL_ 2549579536 CoolantLevelLow_ISig_4 7 "LevelLow3bit_NotAvailable" 6 "LevelLow3bit_Error" 5 "LevelLow3bit_LowLevel5" 4 "LevelLow3bit_LowLevel4" 3 "LevelLow3bit_LowLevel3" 2 "LevelLow3bit_LowLevel2" 1 "LevelLow3bit_LowLevel1" 0 "LevelLow3bit_OK" ;
VAL_ 2549579536 AutoWheelBrakesStatus 7 "CCWheelBrkActBySyst_NotAvailable" 6 "CCWheelBrkActBySyst_Error" 5 "CCWheelBrkActBySyst_Spare3" 4 "CCWheelBrkActBySyst_Spare2" 3 "CCWheelBrkActBySyst_Spare1" 2 "CCWheelBrkActBySyst_ReducedAutoBraking_WithoutSerBrkDemand" 1 "CCWheelBrkActBySyst_FullAutoBraking_withSerBrksDemand" 0 "CCWheelBrkActBySyst_NoAutoBrakingActive" ;
VAL_ 2549579536 OilPressureLow_ISig_4 7 "LevelLow3bit_NotAvailable" 6 "LevelLow3bit_Error" 5 "LevelLow3bit_LowLevel5" 4 "LevelLow3bit_LowLevel4" 3 "LevelLow3bit_LowLevel3" 2 "LevelLow3bit_LowLevel2" 1 "LevelLow3bit_LowLevel1" 0 "LevelLow3bit_OK" ;
VAL_ 2549579536 TopGearMode_ISig_4 3 "TopGearMode_NotAvailable" 2 "TopGearMode_Error" 1 "TopGearMode_Active" 0 "TopGearMode_NotActive" ;
VAL_ 2549579536 OilLevelLow_ISig_4 7 "LevelLow3bit_NotAvailable" 6 "LevelLow3bit_Error" 5 "LevelLow3bit_LowLevel5" 4 "LevelLow3bit_LowLevel4" 3 "LevelLow3bit_LowLevel3" 2 "LevelLow3bit_LowLevel2" 1 "LevelLow3bit_LowLevel1" 0 "LevelLow3bit_OK" ;
VAL_ 2549579536 InletAirHeaterStatus1_ISig_4 3 "OffOn_NotAvailable" 2 "OffOn_Error" 1 "OffOn_On" 0 "OffOn_Off" ;
VAL_ 2549478160 FuelFilterClogged_ISig_4 7 "LevelLow3bit_NotAvailable" 6 "LevelLow3bit_Error" 5 "LevelLow3bit_LowLevel5" 4 "LevelLow3bit_LowLevel4" 3 "LevelLow3bit_LowLevel3" 2 "LevelLow3bit_LowLevel2" 1 "LevelLow3bit_LowLevel1" 0 "LevelLow3bit_OK" ;
VAL_ 2549478160 AirFilterPressureDrop 7 "AirFilterPressureDrop_NotAvailable" 6 "AirFilterPressureDrop_Error" 5 "AirFilterPressureDrop_AirFilterPressureDropLevel5" 4 "AirFilterPressureDrop_AirFilterPressureDropLevel4" 3 "AirFilterPressureDrop_AirFilterPressureDropLevel3" 2 "AirFilterPressureDrop_AirFilterPressureDropLevel2" 1 "AirFilterPressureDrop_AirFilterPressureDropLevel1" 0 "AirFilterPressureDrop_OK" ;
VAL_ 2549478160 EngineProtDerateStat 3 "InactiveActive_NotAvailable" 2 "InactiveActive_Error" 1 "InactiveActive_Active" 0 "InactiveActive_Inactive" ;
VAL_ 2549478160 ClutchOverloadStatusMan 3 "ClutchOverloadStatus_NotAvailable" 2 "ClutchOverloadStatus_Error" 1 "ClutchOverloadStatus_Overloaded" 0 "ClutchOverloadStatus_NotOverloaded" ;
VAL_ 2549478160 EngineFanOverspeed 3 "NoYes_NotAvailable" 2 "NoYes_Error" 1 "NoYes_Yes" 0 "NoYes_No" ;
VAL_ 2466232336 DPF_LimitedSpeedDuetoInhibit_ISi 7 "LimitedSpeedInhibit_NotAvailable" 6 "LimitedSpeedInhibit_Error" 5 "LimitedSpeedInhibit_Spare2" 4 "LimitedSpeedInhibit_Spare1" 3 "LimitedSpeedInhibit_SpeedNotLimited_InhibitActive" 2 "LimitedSpeedInhibit_SpeedNotLimited_InhibitDenied" 1 "LimitedSpeedInhibit_SpeedLimited_InhibitionActive" 0 "LimitedSpeedInhibit_SpeedNotLimited_NoInhibitRequest" ;
VAL_ 2466232336 XARSystemState 3 "XARSystemState_NotAvailable" 2 "XARSystemState_Error" 1 "XARSystemState_NoExternalAccelerationDemandWillBeAccepted" 0 "XARSystemState_AnyExternalAccelerationDemandWillBeAccepted" ;
VAL_ 2466232336 XARActiveControlMode 7 "XARActiveControlMode_NotAvailable" 6 "XARActiveControlMode_Error" 5 "XARActiveControlMode_Spare_2" 4 "XARActiveControlMode_Spare_1" 3 "XARActiveControlMode_CoastingActive" 2 "XARActiveControlMode_DriversAccelerationDemandExecuted" 1 "XARActiveControlMode_AccelerationControlMaximumMode" 0 "XARActiveControlMode_OverrideDisabled" ;
SIG_GROUP_ 2499765032 PHTimerGUIEvCmd_sg_ISig_4 1 : PHTimerGUIEvCmd_Timer2Temp_ISig_ PHTimerGUIEvCmd_Timer1Recur_ISig PHTimerGUIEvCmd_Timer3Hours_ISig PHTimerGUIEvCmd_Timer3Recur_ISig PHTimerGUIEvCmd_PhTimer1_cmd_ISi PHTimerGUIEvCmd_Timer2Minutes_IS PHTimerGUIEvCmd_Timer3StartDay_I PHTimerGUIEvCmd_Timer2Hours_ISig PHTimerGUIEvCmd_Timer1Duration_I PHTimerGUIEvCmd_Timer2Recur_ISig PHTimerGUIEvCmd_Timer2StartDay_I PHTimerGUIEvCmd_Timer3Minutes_IS PHTimerGUIEvCmd_Timer3Temp_ISig_ PHTimerGUIEvCmd_Timer1Temp_ISig_ PHTimerGUIEvCmd_Timer1StartDay_I PHTimerGUIEvCmd_PhTimer3_cmd_ISi PHTimerGUIEvCmd_PhTimer2_cmd_ISi PHTimerGUIEvCmd_Timer1Hours_ISig PHTimerGUIEvCmd_Timer1Minutes_IS;
SIG_GROUP_ 2499743273 EngTimerGUIEvCmd_sg_ISig_4 1 : EngTimerGUIEvCmd_EhTimer3_cmd_IS EngTimerGUIEvCmd_Timer3StartDay_ EngTimerGUIEvCmd_Timer2Recur_ISi EngTimerGUIEvCmd_Timer3Recur_ISi EngTimerGUIEvCmd_Timer1Minutes_I EngTimerGUIEvCmd_Timer3Hours_ISi EngTimerGUIEvCmd_Timer1StartDay_ EngTimerGUIEvCmd_Timer3Minutes_I EngTimerGUIEvCmd_Timer2StartDay_ EngTimerGUIEvCmd_Timer1Hours_ISi EngTimerGUIEvCmd_EhTimer2_cmd_IS EngTimerGUIEvCmd_Timer2Minutes_I EngTimerGUIEvCmd_Timer2Hours_ISi EngTimerGUIEvCmd_Timer1Recur_ISi EngTimerGUIEvCmd_EhTimer1_cmd_IS;
SIG_GROUP_ 2566356786 OilPrediction_sg 1 : OilPrediction_Quality OilPrediction_RemainDist OilPrediction_RemainTime OilPrediction_Status;
